VERSION "HINBNNNYYNNNYYNNNNNNNNNNNNYNNNYYYNNYNNNNNN/4//%%/4/'%**4NNN///"

NS_ :

BS_:

BU_: VirtualNMTMaster I_O_Device_2 Master I_O_Device_1

BO_ 1803 HBGuard_011: 1 I_O_Device_2
 SG_ Toggle : 7|1@1+ (1,0) [0|0] "" Vector__XXX
 SG_ State : 0|7@1+ (1,0) [0|0] "" Vector__XXX

BO_ 1419 SSDO_011: 8 I_O_Device_2
 SG_ Write_Output_32_Bit16_6320_10 m16 : 32|32@1+ (1,0) [0|4294967295] "" Vector__XXX
 SG_ Write_Output_32_Bit15_6320_0F m15 : 32|32@1+ (1,0) [0|4294967295] "" Vector__XXX
 SG_ Write_Output_32_Bit14_6320_0E m14 : 32|32@1+ (1,0) [0|4294967295] "" Vector__XXX
 SG_ Write_Output_32_Bit13_6320_0D m13 : 32|32@1+ (1,0) [0|4294967295] "" Vector__XXX
 SG_ Write_Output_32_Bit12_6320_0C m12 : 32|32@1+ (1,0) [0|4294967295] "" Vector__XXX
 SG_ Write_Output_32_Bit11_6320_0B m11 : 32|32@1+ (1,0) [0|4294967295] "" Vector__XXX
 SG_ Write_Output_32_Bit10_6320_0A m10 : 32|32@1+ (1,0) [0|4294967295] "" Vector__XXX
 SG_ Write_Output_32_Bit9_6320_09 m9 : 32|32@1+ (1,0) [0|4294967295] "" Vector__XXX
 SG_ Write_Output_32_Bit8_6320_08 m8 : 32|32@1+ (1,0) [0|4294967295] "" Vector__XXX
 SG_ Write_Output_32_Bit7_6320_07 m7 : 32|32@1+ (1,0) [0|4294967295] "" Vector__XXX
 SG_ Write_Output_32_Bit6_6320_06 m6 : 32|32@1+ (1,0) [0|4294967295] "" Vector__XXX
 SG_ Write_Output_32_Bit5_6320_05 m5 : 32|32@1+ (1,0) [0|4294967295] "" Vector__XXX
 SG_ Write_Output_32_Bit4_6320_04 m4 : 32|32@1+ (1,0) [0|4294967295] "" Vector__XXX
 SG_ Write_Output_32_Bit3_6320_03 m3 : 32|32@1+ (1,0) [0|4294967295] "" Vector__XXX
 SG_ Write_Output_32_Bit2_6320_02 m2 : 32|32@1+ (1,0) [0|4294967295] "" Vector__XXX
 SG_ Write_Output_32_Bit1_6320_01 m1 : 32|32@1+ (1,0) [0|4294967295] "" Vector__XXX
 SG_ NrOfObjects_6320_00 m0 : 32|8@1+ (1,0) [0|255] "" Vector__XXX
 SG_ SubIndex_6320 m25376M : 24|8@1+ (1,0) [0|16] "" Vector__XXX
 SG_ Write_Output_16_Bit16_6300_10 m16 : 32|16@1+ (1,0) [0|65535] "" Vector__XXX
 SG_ Write_Output_16_Bit15_6300_0F m15 : 32|16@1+ (1,0) [0|65535] "" Vector__XXX
 SG_ Write_Output_16_Bit14_6300_0E m14 : 32|16@1+ (1,0) [0|65535] "" Vector__XXX
 SG_ Write_Output_16_Bit13_6300_0D m13 : 32|16@1+ (1,0) [0|65535] "" Vector__XXX
 SG_ Write_Output_16_Bit12_6300_0C m12 : 32|16@1+ (1,0) [0|65535] "" Vector__XXX
 SG_ Write_Output_16_Bit11_6300_0B m11 : 32|16@1+ (1,0) [0|65535] "" Vector__XXX
 SG_ Write_Output_16_Bit10_6300_0A m10 : 32|16@1+ (1,0) [0|65535] "" Vector__XXX
 SG_ Write_Output_16_Bit9_6300_09 m9 : 32|16@1+ (1,0) [0|65535] "" Vector__XXX
 SG_ Write_Output_16_Bit8_6300_08 m8 : 32|16@1+ (1,0) [0|65535] "" Vector__XXX
 SG_ Write_Output_16_Bit7_6300_07 m7 : 32|16@1+ (1,0) [0|65535] "" Vector__XXX
 SG_ Write_Output_16_Bit6_6300_06 m6 : 32|16@1+ (1,0) [0|65535] "" Vector__XXX
 SG_ Write_Output_16_Bit5_6300_05 m5 : 32|16@1+ (1,0) [0|65535] "" Vector__XXX
 SG_ Write_Output_16_Bit4_6300_04 m4 : 32|16@1+ (1,0) [0|65535] "" Vector__XXX
 SG_ Write_Output_16_Bit3_6300_03 m3 : 32|16@1+ (1,0) [0|65535] "" Vector__XXX
 SG_ Write_Output_16_Bit2_6300_02 m2 : 32|16@1+ (1,0) [0|65535] "" Vector__XXX
 SG_ Write_Output_16_Bit1_6300_01 m1 : 32|16@1+ (1,0) [0|65535] "" Vector__XXX
 SG_ NrOfObjects_6300_00 m0 : 32|8@1+ (1,0) [0|255] "" Vector__XXX
 SG_ SubIndex_6300 m25344M : 24|8@1+ (1,0) [0|16] "" Vector__XXX
 SG_ Write_Output_1_Bit64_6220_40 m64 : 32|1@1+ (1,0) [0|1] "" Vector__XXX
 SG_ Write_Output_1_Bit63_6220_3F m63 : 32|1@1+ (1,0) [0|1] "" Vector__XXX
 SG_ Write_Output_1_Bit62_6220_3E m62 : 32|1@1+ (1,0) [0|1] "" Vector__XXX
 SG_ Write_Output_1_Bit61_6220_3D m61 : 32|1@1+ (1,0) [0|1] "" Vector__XXX
 SG_ Write_Output_1_Bit60_6220_3C m60 : 32|1@1+ (1,0) [0|1] "" Vector__XXX
 SG_ Write_Output_1_Bit59_6220_3B m59 : 32|1@1+ (1,0) [0|1] "" Vector__XXX
 SG_ Write_Output_1_Bit58_6220_3A m58 : 32|1@1+ (1,0) [0|1] "" Vector__XXX
 SG_ Write_Output_1_Bit57_6220_39 m57 : 32|1@1+ (1,0) [0|1] "" Vector__XXX
 SG_ Write_Output_1_Bit56_6220_38 m56 : 32|1@1+ (1,0) [0|1] "" Vector__XXX
 SG_ Write_Output_1_Bit55_6220_37 m55 : 32|1@1+ (1,0) [0|1] "" Vector__XXX
 SG_ Write_Output_1_Bit54_6220_36 m54 : 32|1@1+ (1,0) [0|1] "" Vector__XXX
 SG_ Write_Output_1_Bit53_6220_35 m53 : 32|1@1+ (1,0) [0|1] "" Vector__XXX
 SG_ Write_Output_1_Bit52_6220_34 m52 : 32|1@1+ (1,0) [0|1] "" Vector__XXX
 SG_ Write_Output_1_Bit51_6220_33 m51 : 32|1@1+ (1,0) [0|1] "" Vector__XXX
 SG_ Write_Output_1_Bit50_6220_32 m50 : 32|1@1+ (1,0) [0|1] "" Vector__XXX
 SG_ Write_Output_1_Bit49_6220_31 m49 : 32|1@1+ (1,0) [0|1] "" Vector__XXX
 SG_ Write_Output_1_Bit48_6220_30 m48 : 32|1@1+ (1,0) [0|1] "" Vector__XXX
 SG_ Write_Output_1_Bit47_6220_2F m47 : 32|1@1+ (1,0) [0|1] "" Vector__XXX
 SG_ Write_Output_1_Bit46_6220_2E m46 : 32|1@1+ (1,0) [0|1] "" Vector__XXX
 SG_ Write_Output_1_Bit45_6220_2D m45 : 32|1@1+ (1,0) [0|1] "" Vector__XXX
 SG_ Write_Output_1_Bit44_6220_2C m44 : 32|1@1+ (1,0) [0|1] "" Vector__XXX
 SG_ Write_Output_1_Bit43_6220_2B m43 : 32|1@1+ (1,0) [0|1] "" Vector__XXX
 SG_ Write_Output_1_Bit42_6220_2A m42 : 32|1@1+ (1,0) [0|1] "" Vector__XXX
 SG_ Write_Output_1_Bit41_6220_29 m41 : 32|1@1+ (1,0) [0|1] "" Vector__XXX
 SG_ Write_Output_1_Bit40_6220_28 m40 : 32|1@1+ (1,0) [0|1] "" Vector__XXX
 SG_ Write_Output_1_Bit39_6220_27 m39 : 32|1@1+ (1,0) [0|1] "" Vector__XXX
 SG_ Write_Output_1_Bit38_6220_26 m38 : 32|1@1+ (1,0) [0|1] "" Vector__XXX
 SG_ Write_Output_1_Bit37_6220_25 m37 : 32|1@1+ (1,0) [0|1] "" Vector__XXX
 SG_ Write_Output_1_Bit36_6220_24 m36 : 32|1@1+ (1,0) [0|1] "" Vector__XXX
 SG_ Write_Output_1_Bit35_6220_23 m35 : 32|1@1+ (1,0) [0|1] "" Vector__XXX
 SG_ Write_Output_1_Bit34_6220_22 m34 : 32|1@1+ (1,0) [0|1] "" Vector__XXX
 SG_ Write_Output_1_Bit33_6220_21 m33 : 32|1@1+ (1,0) [0|1] "" Vector__XXX
 SG_ Write_Output_1_Bit32_6220_20 m32 : 32|1@1+ (1,0) [0|1] "" Vector__XXX
 SG_ Write_Output_1_Bit31_6220_1F m31 : 32|1@1+ (1,0) [0|1] "" Vector__XXX
 SG_ Write_Output_1_Bit30_6220_1E m30 : 32|1@1+ (1,0) [0|1] "" Vector__XXX
 SG_ Write_Output_1_Bit29_6220_1D m29 : 32|1@1+ (1,0) [0|1] "" Vector__XXX
 SG_ Write_Output_1_Bit28_6220_1C m28 : 32|1@1+ (1,0) [0|1] "" Vector__XXX
 SG_ Write_Output_1_Bit27_6220_1B m27 : 32|1@1+ (1,0) [0|1] "" Vector__XXX
 SG_ Write_Output_1_Bit26_6220_1A m26 : 32|1@1+ (1,0) [0|1] "" Vector__XXX
 SG_ Write_Output_1_Bit25_6220_19 m25 : 32|1@1+ (1,0) [0|1] "" Vector__XXX
 SG_ Write_Output_1_Bit24_6220_18 m24 : 32|1@1+ (1,0) [0|1] "" Vector__XXX
 SG_ Write_Output_1_Bit23_6220_17 m23 : 32|1@1+ (1,0) [0|1] "" Vector__XXX
 SG_ Write_Output_1_Bit22_6220_16 m22 : 32|1@1+ (1,0) [0|1] "" Vector__XXX
 SG_ Write_Output_1_Bit21_6220_15 m21 : 32|1@1+ (1,0) [0|1] "" Vector__XXX
 SG_ Write_Output_1_Bit20_6220_14 m20 : 32|1@1+ (1,0) [0|1] "" Vector__XXX
 SG_ Write_Output_1_Bit19_6220_13 m19 : 32|1@1+ (1,0) [0|1] "" Vector__XXX
 SG_ Write_Output_1_Bit18_6220_12 m18 : 32|1@1+ (1,0) [0|1] "" Vector__XXX
 SG_ Write_Output_1_Bit17_6220_11 m17 : 32|1@1+ (1,0) [0|1] "" Vector__XXX
 SG_ Write_Output_1_Bit16_6220_10 m16 : 32|1@1+ (1,0) [0|1] "" Vector__XXX
 SG_ Write_Output_1_Bit15_6220_0F m15 : 32|1@1+ (1,0) [0|1] "" Vector__XXX
 SG_ Write_Output_1_Bit14_6220_0E m14 : 32|1@1+ (1,0) [0|1] "" Vector__XXX
 SG_ Write_Output_1_Bit13_6220_0D m13 : 32|1@1+ (1,0) [0|1] "" Vector__XXX
 SG_ Write_Output_1_Bit12_6220_0C m12 : 32|1@1+ (1,0) [0|1] "" Vector__XXX
 SG_ Write_Output_1_Bit11_6220_0B m11 : 32|1@1+ (1,0) [0|1] "" Vector__XXX
 SG_ Write_Output_1_Bit10_6220_0A m10 : 32|1@1+ (1,0) [0|1] "" Vector__XXX
 SG_ Write_Output_1_Bit9_6220_09 m9 : 32|1@1+ (1,0) [0|1] "" Vector__XXX
 SG_ Write_Output_1_Bit8_6220_08 m8 : 32|1@1+ (1,0) [0|1] "" Vector__XXX
 SG_ Write_Output_1_Bit7_6220_07 m7 : 32|1@1+ (1,0) [0|1] "" Vector__XXX
 SG_ Write_Output_1_Bit6_6220_06 m6 : 32|1@1+ (1,0) [0|1] "" Vector__XXX
 SG_ Write_Output_1_Bit5_6220_05 m5 : 32|1@1+ (1,0) [0|1] "" Vector__XXX
 SG_ Write_Output_1_Bit4_6220_04 m4 : 32|1@1+ (1,0) [0|1] "" Vector__XXX
 SG_ Write_Output_1_Bit3_6220_03 m3 : 32|1@1+ (1,0) [0|1] "" Vector__XXX
 SG_ Write_Output_1_Bit2_6220_02 m2 : 32|1@1+ (1,0) [0|1] "" Vector__XXX
 SG_ Write_Output_1_Bit1_6220_01 m1 : 32|1@1+ (1,0) [0|1] "" Vector__XXX
 SG_ NrOfObjects_6220_00 m0 : 32|8@1+ (1,0) [0|255] "" Vector__XXX
 SG_ SubIndex_6220 m25120M : 24|8@1+ (1,0) [0|64] "" Vector__XXX
 SG_ Write_Output_8_Bit16_6200_10 m16 : 32|8@1+ (1,0) [0|255] "" Vector__XXX
 SG_ Write_Output_8_Bit15_6200_0F m15 : 32|8@1+ (1,0) [0|255] "" Vector__XXX
 SG_ Write_Output_8_Bit14_6200_0E m14 : 32|8@1+ (1,0) [0|255] "" Vector__XXX
 SG_ Write_Output_8_Bit13_6200_0D m13 : 32|8@1+ (1,0) [0|255] "" Vector__XXX
 SG_ Write_Output_8_Bit12_6200_0C m12 : 32|8@1+ (1,0) [0|255] "" Vector__XXX
 SG_ Write_Output_8_Bit11_6200_0B m11 : 32|8@1+ (1,0) [0|255] "" Vector__XXX
 SG_ Write_Output_8_Bit10_6200_0A m10 : 32|8@1+ (1,0) [0|255] "" Vector__XXX
 SG_ Write_Output_8_Bit9_6200_09 m9 : 32|8@1+ (1,0) [0|255] "" Vector__XXX
 SG_ Write_Output_8_Bit8_6200_08 m8 : 32|8@1+ (1,0) [0|255] "" Vector__XXX
 SG_ Write_Output_8_Bit7_6200_07 m7 : 32|8@1+ (1,0) [0|255] "" Vector__XXX
 SG_ Write_Output_8_Bit6_6200_06 m6 : 32|8@1+ (1,0) [0|255] "" Vector__XXX
 SG_ Write_Output_8_Bit5_6200_05 m5 : 32|8@1+ (1,0) [0|255] "" Vector__XXX
 SG_ Write_Output_8_Bit4_6200_04 m4 : 32|8@1+ (1,0) [0|255] "" Vector__XXX
 SG_ Write_Output_8_Bit3_6200_03 m3 : 32|8@1+ (1,0) [0|255] "" Vector__XXX
 SG_ Write_Output_8_Bit2_6200_02 m2 : 32|8@1+ (1,0) [0|255] "" Vector__XXX
 SG_ Write_Output_8_Bit1_6200_01 m1 : 32|8@1+ (1,0) [0|255] "" Vector__XXX
 SG_ NrOfObjects_6200_00 m0 : 32|8@1+ (1,0) [0|255] "" Vector__XXX
 SG_ SubIndex_6200 m25088M : 24|8@1+ (1,0) [0|16] "" Vector__XXX
 SG_ Read_Input_32_Bit16_6120_10 m16 : 32|32@1+ (1,0) [0|4294967295] "" Vector__XXX
 SG_ Read_Input_32_Bit15_6120_0F m15 : 32|32@1+ (1,0) [0|4294967295] "" Vector__XXX
 SG_ Read_Input_32_Bit14_6120_0E m14 : 32|32@1+ (1,0) [0|4294967295] "" Vector__XXX
 SG_ Read_Input_32_Bit13_6120_0D m13 : 32|32@1+ (1,0) [0|4294967295] "" Vector__XXX
 SG_ Read_Input_32_Bit12_6120_0C m12 : 32|32@1+ (1,0) [0|4294967295] "" Vector__XXX
 SG_ Read_Input_32_Bit11_6120_0B m11 : 32|32@1+ (1,0) [0|4294967295] "" Vector__XXX
 SG_ Read_Input_32_Bit10_6120_0A m10 : 32|32@1+ (1,0) [0|4294967295] "" Vector__XXX
 SG_ Read_Input_32_Bit9_6120_09 m9 : 32|32@1+ (1,0) [0|4294967295] "" Vector__XXX
 SG_ Read_Input_32_Bit8_6120_08 m8 : 32|32@1+ (1,0) [0|4294967295] "" Vector__XXX
 SG_ Read_Input_32_Bit7_6120_07 m7 : 32|32@1+ (1,0) [0|4294967295] "" Vector__XXX
 SG_ Read_Input_32_Bit6_6120_06 m6 : 32|32@1+ (1,0) [0|4294967295] "" Vector__XXX
 SG_ Read_Input_32_Bit5_6120_05 m5 : 32|32@1+ (1,0) [0|4294967295] "" Vector__XXX
 SG_ Read_Input_32_Bit4_6120_04 m4 : 32|32@1+ (1,0) [0|4294967295] "" Vector__XXX
 SG_ Read_Input_32_Bit3_6120_03 m3 : 32|32@1+ (1,0) [0|4294967295] "" Vector__XXX
 SG_ Read_Input_32_Bit2_6120_02 m2 : 32|32@1+ (1,0) [0|4294967295] "" Vector__XXX
 SG_ Read_Input_32_Bit1_6120_01 m1 : 32|32@1+ (1,0) [0|4294967295] "" Vector__XXX
 SG_ NrOfObjects_6120_00 m0 : 32|8@1+ (1,0) [0|255] "" Vector__XXX
 SG_ SubIndex_6120 m24864M : 24|8@1+ (1,0) [0|16] "" Vector__XXX
 SG_ Read_Input_16_Bit16_6100_10 m16 : 32|16@1+ (1,0) [0|65535] "" Vector__XXX
 SG_ Read_Input_16_Bit15_6100_0F m15 : 32|16@1+ (1,0) [0|65535] "" Vector__XXX
 SG_ Read_Input_16_Bit14_6100_0E m14 : 32|16@1+ (1,0) [0|65535] "" Vector__XXX
 SG_ Read_Input_16_Bit13_6100_0D m13 : 32|16@1+ (1,0) [0|65535] "" Vector__XXX
 SG_ Read_Input_16_Bit12_6100_0C m12 : 32|16@1+ (1,0) [0|65535] "" Vector__XXX
 SG_ Read_Input_16_Bit11_6100_0B m11 : 32|16@1+ (1,0) [0|65535] "" Vector__XXX
 SG_ Read_Input_16_Bit10_6100_0A m10 : 32|16@1+ (1,0) [0|65535] "" Vector__XXX
 SG_ Read_Input_16_Bit9_6100_09 m9 : 32|16@1+ (1,0) [0|65535] "" Vector__XXX
 SG_ Read_Input_16_Bit8_6100_08 m8 : 32|16@1+ (1,0) [0|65535] "" Vector__XXX
 SG_ Read_Input_16_Bit7_6100_07 m7 : 32|16@1+ (1,0) [0|65535] "" Vector__XXX
 SG_ Read_Input_16_Bit6_6100_06 m6 : 32|16@1+ (1,0) [0|65535] "" Vector__XXX
 SG_ Read_Input_16_Bit5_6100_05 m5 : 32|16@1+ (1,0) [0|65535] "" Vector__XXX
 SG_ Read_Input_16_Bit4_6100_04 m4 : 32|16@1+ (1,0) [0|65535] "" Vector__XXX
 SG_ Read_Input_16_Bit3_6100_03 m3 : 32|16@1+ (1,0) [0|65535] "" Vector__XXX
 SG_ Read_Input_16_Bit2_6100_02 m2 : 32|16@1+ (1,0) [0|65535] "" Vector__XXX
 SG_ Read_Input_16_Bit1_6100_01 m1 : 32|16@1+ (1,0) [0|65535] "" Vector__XXX
 SG_ NrOfObjects_6100_00 m0 : 32|8@1+ (1,0) [0|255] "" Vector__XXX
 SG_ SubIndex_6100 m24832M : 24|8@1+ (1,0) [0|16] "" Vector__XXX
 SG_ Read_Input_1_Bit64_6020_40 m64 : 32|1@1+ (1,0) [0|1] "" Vector__XXX
 SG_ Read_Input_1_Bit63_6020_3F m63 : 32|1@1+ (1,0) [0|1] "" Vector__XXX
 SG_ Read_Input_1_Bit62_6020_3E m62 : 32|1@1+ (1,0) [0|1] "" Vector__XXX
 SG_ Read_Input_1_Bit61_6020_3D m61 : 32|1@1+ (1,0) [0|1] "" Vector__XXX
 SG_ Read_Input_1_Bit60_6020_3C m60 : 32|1@1+ (1,0) [0|1] "" Vector__XXX
 SG_ Read_Input_1_Bit59_6020_3B m59 : 32|1@1+ (1,0) [0|1] "" Vector__XXX
 SG_ Read_Input_1_Bit58_6020_3A m58 : 32|1@1+ (1,0) [0|1] "" Vector__XXX
 SG_ Read_Input_1_Bit57_6020_39 m57 : 32|1@1+ (1,0) [0|1] "" Vector__XXX
 SG_ Read_Input_1_Bit56_6020_38 m56 : 32|1@1+ (1,0) [0|1] "" Vector__XXX
 SG_ Read_Input_1_Bit55_6020_37 m55 : 32|1@1+ (1,0) [0|1] "" Vector__XXX
 SG_ Read_Input_1_Bit54_6020_36 m54 : 32|1@1+ (1,0) [0|1] "" Vector__XXX
 SG_ Read_Input_1_Bit53_6020_35 m53 : 32|1@1+ (1,0) [0|1] "" Vector__XXX
 SG_ Read_Input_1_Bit52_6020_34 m52 : 32|1@1+ (1,0) [0|1] "" Vector__XXX
 SG_ Read_Input_1_Bit51_6020_33 m51 : 32|1@1+ (1,0) [0|1] "" Vector__XXX
 SG_ Read_Input_1_Bit50_6020_32 m50 : 32|1@1+ (1,0) [0|1] "" Vector__XXX
 SG_ Read_Input_1_Bit49_6020_31 m49 : 32|1@1+ (1,0) [0|1] "" Vector__XXX
 SG_ Read_Input_1_Bit48_6020_30 m48 : 32|1@1+ (1,0) [0|1] "" Vector__XXX
 SG_ Read_Input_1_Bit47_6020_2F m47 : 32|1@1+ (1,0) [0|1] "" Vector__XXX
 SG_ Read_Input_1_Bit46_6020_2E m46 : 32|1@1+ (1,0) [0|1] "" Vector__XXX
 SG_ Read_Input_1_Bit45_6020_2D m45 : 32|1@1+ (1,0) [0|1] "" Vector__XXX
 SG_ Read_Input_1_Bit44_6020_2C m44 : 32|1@1+ (1,0) [0|1] "" Vector__XXX
 SG_ Read_Input_1_Bit43_6020_2B m43 : 32|1@1+ (1,0) [0|1] "" Vector__XXX
 SG_ Read_Input_1_Bit42_6020_2A m42 : 32|1@1+ (1,0) [0|1] "" Vector__XXX
 SG_ Read_Input_1_Bit41_6020_29 m41 : 32|1@1+ (1,0) [0|1] "" Vector__XXX
 SG_ Read_Input_1_Bit40_6020_28 m40 : 32|1@1+ (1,0) [0|1] "" Vector__XXX
 SG_ Read_Input_1_Bit39_6020_27 m39 : 32|1@1+ (1,0) [0|1] "" Vector__XXX
 SG_ Read_Input_1_Bit38_6020_26 m38 : 32|1@1+ (1,0) [0|1] "" Vector__XXX
 SG_ Read_Input_1_Bit37_6020_25 m37 : 32|1@1+ (1,0) [0|1] "" Vector__XXX
 SG_ Read_Input_1_Bit36_6020_24 m36 : 32|1@1+ (1,0) [0|1] "" Vector__XXX
 SG_ Read_Input_1_Bit35_6020_23 m35 : 32|1@1+ (1,0) [0|1] "" Vector__XXX
 SG_ Read_Input_1_Bit34_6020_22 m34 : 32|1@1+ (1,0) [0|1] "" Vector__XXX
 SG_ Read_Input_1_Bit33_6020_21 m33 : 32|1@1+ (1,0) [0|1] "" Vector__XXX
 SG_ Read_Input_1_Bit32_6020_20 m32 : 32|1@1+ (1,0) [0|1] "" Vector__XXX
 SG_ Read_Input_1_Bit31_6020_1F m31 : 32|1@1+ (1,0) [0|1] "" Vector__XXX
 SG_ Read_Input_1_Bit30_6020_1E m30 : 32|1@1+ (1,0) [0|1] "" Vector__XXX
 SG_ Read_Input_1_Bit29_6020_1D m29 : 32|1@1+ (1,0) [0|1] "" Vector__XXX
 SG_ Read_Input_1_Bit28_6020_1C m28 : 32|1@1+ (1,0) [0|1] "" Vector__XXX
 SG_ Read_Input_1_Bit27_6020_1B m27 : 32|1@1+ (1,0) [0|1] "" Vector__XXX
 SG_ Read_Input_1_Bit26_6020_1A m26 : 32|1@1+ (1,0) [0|1] "" Vector__XXX
 SG_ Read_Input_1_Bit25_6020_19 m25 : 32|1@1+ (1,0) [0|1] "" Vector__XXX
 SG_ Read_Input_1_Bit24_6020_18 m24 : 32|1@1+ (1,0) [0|1] "" Vector__XXX
 SG_ Read_Input_1_Bit23_6020_17 m23 : 32|1@1+ (1,0) [0|1] "" Vector__XXX
 SG_ Read_Input_1_Bit22_6020_16 m22 : 32|1@1+ (1,0) [0|1] "" Vector__XXX
 SG_ Read_Input_1_Bit21_6020_15 m21 : 32|1@1+ (1,0) [0|1] "" Vector__XXX
 SG_ Read_Input_1_Bit20_6020_14 m20 : 32|1@1+ (1,0) [0|1] "" Vector__XXX
 SG_ Read_Input_1_Bit19_6020_13 m19 : 32|1@1+ (1,0) [0|1] "" Vector__XXX
 SG_ Read_Input_1_Bit18_6020_12 m18 : 32|1@1+ (1,0) [0|1] "" Vector__XXX
 SG_ Read_Input_1_Bit17_6020_11 m17 : 32|1@1+ (1,0) [0|1] "" Vector__XXX
 SG_ Read_Input_1_Bit16_6020_10 m16 : 32|1@1+ (1,0) [0|1] "" Vector__XXX
 SG_ Read_Input_1_Bit15_6020_0F m15 : 32|1@1+ (1,0) [0|1] "" Vector__XXX
 SG_ Read_Input_1_Bit14_6020_0E m14 : 32|1@1+ (1,0) [0|1] "" Vector__XXX
 SG_ Read_Input_1_Bit13_6020_0D m13 : 32|1@1+ (1,0) [0|1] "" Vector__XXX
 SG_ Read_Input_1_Bit12_6020_0C m12 : 32|1@1+ (1,0) [0|1] "" Vector__XXX
 SG_ Read_Input_1_Bit11_6020_0B m11 : 32|1@1+ (1,0) [0|1] "" Vector__XXX
 SG_ Read_Input_1_Bit10_6020_0A m10 : 32|1@1+ (1,0) [0|1] "" Vector__XXX
 SG_ Read_Input_1_Bit9_6020_09 m9 : 32|1@1+ (1,0) [0|1] "" Vector__XXX
 SG_ Read_Input_1_Bit8_6020_08 m8 : 32|1@1+ (1,0) [0|1] "" Vector__XXX
 SG_ Read_Input_1_Bit7_6020_07 m7 : 32|1@1+ (1,0) [0|1] "" Vector__XXX
 SG_ Read_Input_1_Bit6_6020_06 m6 : 32|1@1+ (1,0) [0|1] "" Vector__XXX
 SG_ Read_Input_1_Bit5_6020_05 m5 : 32|1@1+ (1,0) [0|1] "" Vector__XXX
 SG_ Read_Input_1_Bit4_6020_04 m4 : 32|1@1+ (1,0) [0|1] "" Vector__XXX
 SG_ Read_Input_1_Bit3_6020_03 m3 : 32|1@1+ (1,0) [0|1] "" Vector__XXX
 SG_ Read_Input_1_Bit2_6020_02 m2 : 32|1@1+ (1,0) [0|1] "" Vector__XXX
 SG_ Read_Input_1_Bit1_6020_01 m1 : 32|1@1+ (1,0) [0|1] "" Vector__XXX
 SG_ NrOfObjects_6020_00 m0 : 32|8@1+ (1,0) [0|255] "" Vector__XXX
 SG_ SubIndex_6020 m24608M : 24|8@1+ (1,0) [0|64] "" Vector__XXX
 SG_ Read_Input_8_Bit16_6000_10 m16 : 32|8@1+ (1,0) [0|255] "" Vector__XXX
 SG_ Read_Input_8_Bit15_6000_0F m15 : 32|8@1+ (1,0) [0|255] "" Vector__XXX
 SG_ Read_Input_8_Bit14_6000_0E m14 : 32|8@1+ (1,0) [0|255] "" Vector__XXX
 SG_ Read_Input_8_Bit13_6000_0D m13 : 32|8@1+ (1,0) [0|255] "" Vector__XXX
 SG_ Read_Input_8_Bit12_6000_0C m12 : 32|8@1+ (1,0) [0|255] "" Vector__XXX
 SG_ Read_Input_8_Bit11_6000_0B m11 : 32|8@1+ (1,0) [0|255] "" Vector__XXX
 SG_ Read_Input_8_Bit10_6000_0A m10 : 32|8@1+ (1,0) [0|255] "" Vector__XXX
 SG_ Read_Input_8_Bit9_6000_09 m9 : 32|8@1+ (1,0) [0|255] "" Vector__XXX
 SG_ Read_Input_8_Bit8_6000_08 m8 : 32|8@1+ (1,0) [0|255] "" Vector__XXX
 SG_ Read_Input_8_Bit7_6000_07 m7 : 32|8@1+ (1,0) [0|255] "" Vector__XXX
 SG_ Read_Input_8_Bit6_6000_06 m6 : 32|8@1+ (1,0) [0|255] "" Vector__XXX
 SG_ Read_Input_8_Bit5_6000_05 m5 : 32|8@1+ (1,0) [0|255] "" Vector__XXX
 SG_ Read_Input_8_Bit4_6000_04 m4 : 32|8@1+ (1,0) [0|255] "" Vector__XXX
 SG_ Read_Input_8_Bit3_6000_03 m3 : 32|8@1+ (1,0) [0|255] "" Vector__XXX
 SG_ Read_Input_8_Bit2_6000_02 m2 : 32|8@1+ (1,0) [0|255] "" Vector__XXX
 SG_ Read_Input_8_Bit1_6000_01 m1 : 32|8@1+ (1,0) [0|255] "" Vector__XXX
 SG_ NrOfObjects_6000_00 m0 : 32|8@1+ (1,0) [0|255] "" Vector__XXX
 SG_ SubIndex_6000 m24576M : 24|8@1+ (1,0) [0|16] "" Vector__XXX
 SG_ NrOfObjects_2300_00 m0 : 32|8@1+ (1,0) [0|255] "" Vector__XXX
 SG_ SubIndex_2300 m8960M : 24|8@1+ (1,0) [0|4] "" Vector__XXX
 SG_ NrOfObjects_2200_00 m0 : 32|8@1+ (1,0) [0|255] "" Vector__XXX
 SG_ SubIndex_2200 m8704M : 24|8@1+ (1,0) [0|4] "" Vector__XXX
 SG_ NrOfMappedObjects_1A03_00 m0 : 32|8@1+ (1,0) [0|64] "" Vector__XXX
 SG_ SubIndex_1A03 m6659M : 24|8@1+ (1,0) [0|0] "" Vector__XXX
 SG_ NrOfMappedObjects_1A02_00 m0 : 32|8@1+ (1,0) [0|64] "" Vector__XXX
 SG_ SubIndex_1A02 m6658M : 24|8@1+ (1,0) [0|0] "" Vector__XXX
 SG_ NrOfMappedObjects_1A01_00 m0 : 32|8@1+ (1,0) [0|64] "" Vector__XXX
 SG_ SubIndex_1A01 m6657M : 24|8@1+ (1,0) [0|0] "" Vector__XXX
 SG_ NrOfMappedObjects_1A00_00 m0 : 32|8@1+ (1,0) [0|64] "" Vector__XXX
 SG_ SubIndex_1A00 m6656M : 24|8@1+ (1,0) [0|0] "" Vector__XXX
 SG_ EventTimer_1803_05 m5 : 32|16@1+ (1,0) [0|65535] "" Vector__XXX
 SG_ TransmissionType_1803_02 m2 : 32|8@1+ (1,0) [0|255] "" Vector__XXX
 SG_ COB_ID_1803_01 m1 : 32|32@1+ (1,0) [128|4294967295] "" Vector__XXX
 SG_ NrOfEntries_1803_00 m0 : 32|8@1+ (1,0) [2|5] "" Vector__XXX
 SG_ SubIndex_1803 m6147M : 24|8@1+ (1,0) [0|5] "" Vector__XXX
 SG_ EventTimer_1802_05 m5 : 32|16@1+ (1,0) [0|65535] "" Vector__XXX
 SG_ TransmissionType_1802_02 m2 : 32|8@1+ (1,0) [0|255] "" Vector__XXX
 SG_ COB_ID_1802_01 m1 : 32|32@1+ (1,0) [128|4294967295] "" Vector__XXX
 SG_ NrOfEntries_1802_00 m0 : 32|8@1+ (1,0) [2|5] "" Vector__XXX
 SG_ SubIndex_1802 m6146M : 24|8@1+ (1,0) [0|5] "" Vector__XXX
 SG_ EventTimer_1801_05 m5 : 32|16@1+ (1,0) [0|65535] "" Vector__XXX
 SG_ TransmissionType_1801_02 m2 : 32|8@1+ (1,0) [0|255] "" Vector__XXX
 SG_ COB_ID_1801_01 m1 : 32|32@1+ (1,0) [128|4294967295] "" Vector__XXX
 SG_ NrOfEntries_1801_00 m0 : 32|8@1+ (1,0) [2|5] "" Vector__XXX
 SG_ SubIndex_1801 m6145M : 24|8@1+ (1,0) [0|5] "" Vector__XXX
 SG_ EventTimer_1800_05 m5 : 32|16@1+ (1,0) [0|65535] "" Vector__XXX
 SG_ TransmissionType_1800_02 m2 : 32|8@1+ (1,0) [0|255] "" Vector__XXX
 SG_ COB_ID_1800_01 m1 : 32|32@1+ (1,0) [128|4294967295] "" Vector__XXX
 SG_ NrOfEntries_1800_00 m0 : 32|8@1+ (1,0) [2|5] "" Vector__XXX
 SG_ SubIndex_1800 m6144M : 24|8@1+ (1,0) [0|5] "" Vector__XXX
 SG_ NrOfMappedObjects_1603_00 m0 : 32|8@1+ (1,0) [0|64] "" Vector__XXX
 SG_ SubIndex_1603 m5635M : 24|8@1+ (1,0) [0|0] "" Vector__XXX
 SG_ NrOfMappedObjects_1602_00 m0 : 32|8@1+ (1,0) [0|64] "" Vector__XXX
 SG_ SubIndex_1602 m5634M : 24|8@1+ (1,0) [0|0] "" Vector__XXX
 SG_ NrOfMappedObjects_1601_00 m0 : 32|8@1+ (1,0) [0|64] "" Vector__XXX
 SG_ SubIndex_1601 m5633M : 24|8@1+ (1,0) [0|0] "" Vector__XXX
 SG_ mappedObj2_1600_02 m2 : 32|32@1+ (1,0) [0|4294967295] "" Vector__XXX
 SG_ mappedObj1_1600_01 m1 : 32|32@1+ (1,0) [0|4294967295] "" Vector__XXX
 SG_ NrOfMappedObjects_1600_00 m0 : 32|8@1+ (1,0) [0|64] "" Vector__XXX
 SG_ SubIndex_1600 m5632M : 24|8@1+ (1,0) [0|2] "" Vector__XXX
 SG_ TransmissionType_1403_02 m2 : 32|8@1+ (1,0) [0|255] "" Vector__XXX
 SG_ COB_ID_1403_01 m1 : 32|32@1+ (1,0) [128|4294967295] "" Vector__XXX
 SG_ NrOfEntries_1403_00 m0 : 32|8@1+ (1,0) [2|5] "" Vector__XXX
 SG_ SubIndex_1403 m5123M : 24|8@1+ (1,0) [0|2] "" Vector__XXX
 SG_ TransmissionType_1402_02 m2 : 32|8@1+ (1,0) [0|255] "" Vector__XXX
 SG_ COB_ID_1402_01 m1 : 32|32@1+ (1,0) [128|4294967295] "" Vector__XXX
 SG_ NrOfEntries_1402_00 m0 : 32|8@1+ (1,0) [2|5] "" Vector__XXX
 SG_ SubIndex_1402 m5122M : 24|8@1+ (1,0) [0|2] "" Vector__XXX
 SG_ TransmissionType_1401_02 m2 : 32|8@1+ (1,0) [0|255] "" Vector__XXX
 SG_ COB_ID_1401_01 m1 : 32|32@1+ (1,0) [128|4294967295] "" Vector__XXX
 SG_ NrOfEntries_1401_00 m0 : 32|8@1+ (1,0) [2|5] "" Vector__XXX
 SG_ SubIndex_1401 m5121M : 24|8@1+ (1,0) [0|2] "" Vector__XXX
 SG_ TransmissionType_1400_02 m2 : 32|8@1+ (1,0) [0|255] "" Vector__XXX
 SG_ COB_ID_1400_01 m1 : 32|32@1+ (1,0) [128|4294967295] "" Vector__XXX
 SG_ NrOfEntries_1400_00 m0 : 32|8@1+ (1,0) [2|5] "" Vector__XXX
 SG_ SubIndex_1400 m5120M : 24|8@1+ (1,0) [0|2] "" Vector__XXX
 SG_ Serial_number_1018_04 m4 : 32|32@1+ (1,0) [0|4294967295] "" Vector__XXX
 SG_ Revision_number_1018_03 m3 : 32|32@1+ (1,0) [0|4294967295] "" Vector__XXX
 SG_ Product_Code_1018_02 m2 : 32|32@1+ (1,0) [0|4294967295] "" Vector__XXX
 SG_ Vendor_Id_1018_01 m1 : 32|32@1+ (1,0) [0|4294967295] "" Vector__XXX
 SG_ number_of_entries_1018_00 m0 : 32|8@1+ (1,0) [1|4] "" Vector__XXX
 SG_ SubIndex_1018 m4120M : 24|8@1+ (1,0) [0|4] "" Vector__XXX
 SG_ Producer_Heartbeat_Time_1017 m0 : 32|16@1+ (1,0) [0|65535] "" Vector__XXX
 SG_ SubIndex_1017 m4119M : 24|8@1+ (1,0) [0|0] "" Vector__XXX
 SG_ Consumer_Heartbeat_Time16_1016_1 m16 : 32|32@1+ (1,0) [0|4294967295] "" Vector__XXX
 SG_ Consumer_Heartbeat_Time15_1016_0 m15 : 32|32@1+ (1,0) [0|4294967295] "" Vector__XXX
 SG_ Consumer_Heartbeat_Time14_1016_0 m14 : 32|32@1+ (1,0) [0|4294967295] "" Vector__XXX
 SG_ Consumer_Heartbeat_Time13_1016_0 m13 : 32|32@1+ (1,0) [0|4294967295] "" Vector__XXX
 SG_ Consumer_Heartbeat_Time12_1016_0 m12 : 32|32@1+ (1,0) [0|4294967295] "" Vector__XXX
 SG_ Consumer_Heartbeat_Time11_1016_0 m11 : 32|32@1+ (1,0) [0|4294967295] "" Vector__XXX
 SG_ Consumer_Heartbeat_Time10_1016_0 m10 : 32|32@1+ (1,0) [0|4294967295] "" Vector__XXX
 SG_ Consumer_Heartbeat_Time9_1016_09 m9 : 32|32@1+ (1,0) [0|4294967295] "" Vector__XXX
 SG_ Consumer_Heartbeat_Time8_1016_08 m8 : 32|32@1+ (1,0) [0|4294967295] "" Vector__XXX
 SG_ Consumer_Heartbeat_Time7_1016_07 m7 : 32|32@1+ (1,0) [0|4294967295] "" Vector__XXX
 SG_ Consumer_Heartbeat_Time6_1016_06 m6 : 32|32@1+ (1,0) [0|4294967295] "" Vector__XXX
 SG_ Consumer_Heartbeat_Time5_1016_05 m5 : 32|32@1+ (1,0) [0|4294967295] "" Vector__XXX
 SG_ Consumer_Heartbeat_Time4_1016_04 m4 : 32|32@1+ (1,0) [0|4294967295] "" Vector__XXX
 SG_ Consumer_Heartbeat_Time3_1016_03 m3 : 32|32@1+ (1,0) [0|4294967295] "" Vector__XXX
 SG_ Consumer_Heartbeat_Time2_1016_02 m2 : 32|32@1+ (1,0) [0|4294967295] "" Vector__XXX
 SG_ Consumer_Heartbeat_Time1_1016_01 m1 : 32|32@1+ (1,0) [0|4294967295] "" Vector__XXX
 SG_ NrOfObjects_1016_00 m0 : 32|8@1+ (1,0) [0|255] "" Vector__XXX
 SG_ SubIndex_1016 m4118M : 24|8@1+ (1,0) [0|16] "" Vector__XXX
 SG_ COB_ID_EMCY_1014 m0 : 32|32@1+ (1,0) [128|3221225471] "" Vector__XXX
 SG_ SubIndex_1014 m4116M : 24|8@1+ (1,0) [0|0] "" Vector__XXX
 SG_ Restore_all_Default_Parameters_1 m1 : 32|32@1+ (1,0) [0|4294967295] "" Vector__XXX
 SG_ Number_of_Entries_1011_00 m0 : 32|8@1+ (1,0) [0|255] "" Vector__XXX
 SG_ SubIndex_1011 m4113M : 24|8@1+ (1,0) [0|1] "" Vector__XXX
 SG_ Save_all_Parameters_1010_01 m1 : 32|32@1+ (1,0) [0|4294967295] "" Vector__XXX
 SG_ Number_of_Entries_1010_00 m0 : 32|8@1+ (1,0) [0|255] "" Vector__XXX
 SG_ SubIndex_1010 m4112M : 24|8@1+ (1,0) [0|1] "" Vector__XXX
 SG_ Life_Time_Factor_100D m0 : 32|8@1+ (1,0) [0|255] "" Vector__XXX
 SG_ SubIndex_100D m4109M : 24|8@1+ (1,0) [0|0] "" Vector__XXX
 SG_ Guard_Time_100C m0 : 32|16@1+ (1,0) [0|65535] "" Vector__XXX
 SG_ SubIndex_100C m4108M : 24|8@1+ (1,0) [0|0] "" Vector__XXX
 SG_ Synchronous_Window_Length_1007 m0 : 32|32@1+ (1,0) [0|4294967295] "" Vector__XXX
 SG_ SubIndex_1007 m4103M : 24|8@1+ (1,0) [0|0] "" Vector__XXX
 SG_ Communication_Cycle_Period_1006 m0 : 32|32@1+ (1,0) [0|4294967295] "" Vector__XXX
 SG_ SubIndex_1006 m4102M : 24|8@1+ (1,0) [0|0] "" Vector__XXX
 SG_ COB_ID_SYNC_1005 m0 : 32|32@1+ (1,0) [128|4294967295] "" Vector__XXX
 SG_ SubIndex_1005 m4101M : 24|8@1+ (1,0) [0|0] "" Vector__XXX
 SG_ Standard_error_field_1003_09 m9 : 32|32@1+ (1,0) [0|4294967295] "" Vector__XXX
 SG_ Standard_error_field_1003_08 m8 : 32|32@1+ (1,0) [0|4294967295] "" Vector__XXX
 SG_ Standard_error_field_1003_07 m7 : 32|32@1+ (1,0) [0|4294967295] "" Vector__XXX
 SG_ Standard_error_field_1003_06 m6 : 32|32@1+ (1,0) [0|4294967295] "" Vector__XXX
 SG_ Standard_error_field_1003_05 m5 : 32|32@1+ (1,0) [0|4294967295] "" Vector__XXX
 SG_ Standard_error_field_1003_04 m4 : 32|32@1+ (1,0) [0|4294967295] "" Vector__XXX
 SG_ Standard_error_field_1003_03 m3 : 32|32@1+ (1,0) [0|4294967295] "" Vector__XXX
 SG_ Standard_error_field_1003_02 m2 : 32|32@1+ (1,0) [0|4294967295] "" Vector__XXX
 SG_ Standard_error_field_1003_01 m1 : 32|32@1+ (1,0) [0|4294967295] "" Vector__XXX
 SG_ Number_of_Errors_1003_00 m0 : 32|8@1+ (1,0) [0|255] "" Vector__XXX
 SG_ SubIndex_1003 m4099M : 24|8@1+ (1,0) [0|9] "" Vector__XXX
 SG_ Error_Register_1001 m0 : 32|8@1+ (1,0) [0|255] "" Vector__XXX
 SG_ SubIndex_1001 m4097M : 24|8@1+ (1,0) [0|0] "" Vector__XXX
 SG_ Device_Type_1000 m0 : 32|32@1+ (1,0) [0|4294967295] "" Vector__XXX
 SG_ SubIndex_1000 m4096M : 24|8@1+ (1,0) [0|0] "" Vector__XXX
 SG_ Index m1M : 8|16@1+ (1,0) [4096|25376] "" Vector__XXX
 SG_ TransferType m1M : 1|1@1+ (1,0) [0|1] "" Vector__XXX
 SG_ NotUsedBytes m1 : 2|2@1+ (1,0) [0|3] "" Vector__XXX
 SG_ SizeIndicator m1 : 0|1@1+ (1,0) [0|1] "" Vector__XXX
 SG_ SCS M : 5|3@1+ (1,0) [0|6] "" Vector__XXX

BO_ 1547 CSDO_011: 8 Vector__XXX
 SG_ Write_Output_32_Bit16_6320_10 m16 : 32|32@1+ (1,0) [0|4294967295] ""  I_O_Device_2
 SG_ Write_Output_32_Bit15_6320_0F m15 : 32|32@1+ (1,0) [0|4294967295] ""  I_O_Device_2
 SG_ Write_Output_32_Bit14_6320_0E m14 : 32|32@1+ (1,0) [0|4294967295] ""  I_O_Device_2
 SG_ Write_Output_32_Bit13_6320_0D m13 : 32|32@1+ (1,0) [0|4294967295] ""  I_O_Device_2
 SG_ Write_Output_32_Bit12_6320_0C m12 : 32|32@1+ (1,0) [0|4294967295] ""  I_O_Device_2
 SG_ Write_Output_32_Bit11_6320_0B m11 : 32|32@1+ (1,0) [0|4294967295] ""  I_O_Device_2
 SG_ Write_Output_32_Bit10_6320_0A m10 : 32|32@1+ (1,0) [0|4294967295] ""  I_O_Device_2
 SG_ Write_Output_32_Bit9_6320_09 m9 : 32|32@1+ (1,0) [0|4294967295] ""  I_O_Device_2
 SG_ Write_Output_32_Bit8_6320_08 m8 : 32|32@1+ (1,0) [0|4294967295] ""  I_O_Device_2
 SG_ Write_Output_32_Bit7_6320_07 m7 : 32|32@1+ (1,0) [0|4294967295] ""  I_O_Device_2
 SG_ Write_Output_32_Bit6_6320_06 m6 : 32|32@1+ (1,0) [0|4294967295] ""  I_O_Device_2
 SG_ Write_Output_32_Bit5_6320_05 m5 : 32|32@1+ (1,0) [0|4294967295] ""  I_O_Device_2
 SG_ Write_Output_32_Bit4_6320_04 m4 : 32|32@1+ (1,0) [0|4294967295] ""  I_O_Device_2
 SG_ Write_Output_32_Bit3_6320_03 m3 : 32|32@1+ (1,0) [0|4294967295] ""  I_O_Device_2
 SG_ Write_Output_32_Bit2_6320_02 m2 : 32|32@1+ (1,0) [0|4294967295] ""  I_O_Device_2
 SG_ Write_Output_32_Bit1_6320_01 m1 : 32|32@1+ (1,0) [0|4294967295] ""  I_O_Device_2
 SG_ NrOfObjects_6320_00 m0 : 32|8@1+ (1,0) [0|255] ""  I_O_Device_2
 SG_ SubIndex_6320 m25376M : 24|8@1+ (1,0) [0|16] ""  I_O_Device_2
 SG_ Write_Output_16_Bit16_6300_10 m16 : 32|16@1+ (1,0) [0|65535] ""  I_O_Device_2
 SG_ Write_Output_16_Bit15_6300_0F m15 : 32|16@1+ (1,0) [0|65535] ""  I_O_Device_2
 SG_ Write_Output_16_Bit14_6300_0E m14 : 32|16@1+ (1,0) [0|65535] ""  I_O_Device_2
 SG_ Write_Output_16_Bit13_6300_0D m13 : 32|16@1+ (1,0) [0|65535] ""  I_O_Device_2
 SG_ Write_Output_16_Bit12_6300_0C m12 : 32|16@1+ (1,0) [0|65535] ""  I_O_Device_2
 SG_ Write_Output_16_Bit11_6300_0B m11 : 32|16@1+ (1,0) [0|65535] ""  I_O_Device_2
 SG_ Write_Output_16_Bit10_6300_0A m10 : 32|16@1+ (1,0) [0|65535] ""  I_O_Device_2
 SG_ Write_Output_16_Bit9_6300_09 m9 : 32|16@1+ (1,0) [0|65535] ""  I_O_Device_2
 SG_ Write_Output_16_Bit8_6300_08 m8 : 32|16@1+ (1,0) [0|65535] ""  I_O_Device_2
 SG_ Write_Output_16_Bit7_6300_07 m7 : 32|16@1+ (1,0) [0|65535] ""  I_O_Device_2
 SG_ Write_Output_16_Bit6_6300_06 m6 : 32|16@1+ (1,0) [0|65535] ""  I_O_Device_2
 SG_ Write_Output_16_Bit5_6300_05 m5 : 32|16@1+ (1,0) [0|65535] ""  I_O_Device_2
 SG_ Write_Output_16_Bit4_6300_04 m4 : 32|16@1+ (1,0) [0|65535] ""  I_O_Device_2
 SG_ Write_Output_16_Bit3_6300_03 m3 : 32|16@1+ (1,0) [0|65535] ""  I_O_Device_2
 SG_ Write_Output_16_Bit2_6300_02 m2 : 32|16@1+ (1,0) [0|65535] ""  I_O_Device_2
 SG_ Write_Output_16_Bit1_6300_01 m1 : 32|16@1+ (1,0) [0|65535] ""  I_O_Device_2
 SG_ NrOfObjects_6300_00 m0 : 32|8@1+ (1,0) [0|255] ""  I_O_Device_2
 SG_ SubIndex_6300 m25344M : 24|8@1+ (1,0) [0|16] ""  I_O_Device_2
 SG_ Write_Output_1_Bit64_6220_40 m64 : 32|1@1+ (1,0) [0|1] ""  I_O_Device_2
 SG_ Write_Output_1_Bit63_6220_3F m63 : 32|1@1+ (1,0) [0|1] ""  I_O_Device_2
 SG_ Write_Output_1_Bit62_6220_3E m62 : 32|1@1+ (1,0) [0|1] ""  I_O_Device_2
 SG_ Write_Output_1_Bit61_6220_3D m61 : 32|1@1+ (1,0) [0|1] ""  I_O_Device_2
 SG_ Write_Output_1_Bit60_6220_3C m60 : 32|1@1+ (1,0) [0|1] ""  I_O_Device_2
 SG_ Write_Output_1_Bit59_6220_3B m59 : 32|1@1+ (1,0) [0|1] ""  I_O_Device_2
 SG_ Write_Output_1_Bit58_6220_3A m58 : 32|1@1+ (1,0) [0|1] ""  I_O_Device_2
 SG_ Write_Output_1_Bit57_6220_39 m57 : 32|1@1+ (1,0) [0|1] ""  I_O_Device_2
 SG_ Write_Output_1_Bit56_6220_38 m56 : 32|1@1+ (1,0) [0|1] ""  I_O_Device_2
 SG_ Write_Output_1_Bit55_6220_37 m55 : 32|1@1+ (1,0) [0|1] ""  I_O_Device_2
 SG_ Write_Output_1_Bit54_6220_36 m54 : 32|1@1+ (1,0) [0|1] ""  I_O_Device_2
 SG_ Write_Output_1_Bit53_6220_35 m53 : 32|1@1+ (1,0) [0|1] ""  I_O_Device_2
 SG_ Write_Output_1_Bit52_6220_34 m52 : 32|1@1+ (1,0) [0|1] ""  I_O_Device_2
 SG_ Write_Output_1_Bit51_6220_33 m51 : 32|1@1+ (1,0) [0|1] ""  I_O_Device_2
 SG_ Write_Output_1_Bit50_6220_32 m50 : 32|1@1+ (1,0) [0|1] ""  I_O_Device_2
 SG_ Write_Output_1_Bit49_6220_31 m49 : 32|1@1+ (1,0) [0|1] ""  I_O_Device_2
 SG_ Write_Output_1_Bit48_6220_30 m48 : 32|1@1+ (1,0) [0|1] ""  I_O_Device_2
 SG_ Write_Output_1_Bit47_6220_2F m47 : 32|1@1+ (1,0) [0|1] ""  I_O_Device_2
 SG_ Write_Output_1_Bit46_6220_2E m46 : 32|1@1+ (1,0) [0|1] ""  I_O_Device_2
 SG_ Write_Output_1_Bit45_6220_2D m45 : 32|1@1+ (1,0) [0|1] ""  I_O_Device_2
 SG_ Write_Output_1_Bit44_6220_2C m44 : 32|1@1+ (1,0) [0|1] ""  I_O_Device_2
 SG_ Write_Output_1_Bit43_6220_2B m43 : 32|1@1+ (1,0) [0|1] ""  I_O_Device_2
 SG_ Write_Output_1_Bit42_6220_2A m42 : 32|1@1+ (1,0) [0|1] ""  I_O_Device_2
 SG_ Write_Output_1_Bit41_6220_29 m41 : 32|1@1+ (1,0) [0|1] ""  I_O_Device_2
 SG_ Write_Output_1_Bit40_6220_28 m40 : 32|1@1+ (1,0) [0|1] ""  I_O_Device_2
 SG_ Write_Output_1_Bit39_6220_27 m39 : 32|1@1+ (1,0) [0|1] ""  I_O_Device_2
 SG_ Write_Output_1_Bit38_6220_26 m38 : 32|1@1+ (1,0) [0|1] ""  I_O_Device_2
 SG_ Write_Output_1_Bit37_6220_25 m37 : 32|1@1+ (1,0) [0|1] ""  I_O_Device_2
 SG_ Write_Output_1_Bit36_6220_24 m36 : 32|1@1+ (1,0) [0|1] ""  I_O_Device_2
 SG_ Write_Output_1_Bit35_6220_23 m35 : 32|1@1+ (1,0) [0|1] ""  I_O_Device_2
 SG_ Write_Output_1_Bit34_6220_22 m34 : 32|1@1+ (1,0) [0|1] ""  I_O_Device_2
 SG_ Write_Output_1_Bit33_6220_21 m33 : 32|1@1+ (1,0) [0|1] ""  I_O_Device_2
 SG_ Write_Output_1_Bit32_6220_20 m32 : 32|1@1+ (1,0) [0|1] ""  I_O_Device_2
 SG_ Write_Output_1_Bit31_6220_1F m31 : 32|1@1+ (1,0) [0|1] ""  I_O_Device_2
 SG_ Write_Output_1_Bit30_6220_1E m30 : 32|1@1+ (1,0) [0|1] ""  I_O_Device_2
 SG_ Write_Output_1_Bit29_6220_1D m29 : 32|1@1+ (1,0) [0|1] ""  I_O_Device_2
 SG_ Write_Output_1_Bit28_6220_1C m28 : 32|1@1+ (1,0) [0|1] ""  I_O_Device_2
 SG_ Write_Output_1_Bit27_6220_1B m27 : 32|1@1+ (1,0) [0|1] ""  I_O_Device_2
 SG_ Write_Output_1_Bit26_6220_1A m26 : 32|1@1+ (1,0) [0|1] ""  I_O_Device_2
 SG_ Write_Output_1_Bit25_6220_19 m25 : 32|1@1+ (1,0) [0|1] ""  I_O_Device_2
 SG_ Write_Output_1_Bit24_6220_18 m24 : 32|1@1+ (1,0) [0|1] ""  I_O_Device_2
 SG_ Write_Output_1_Bit23_6220_17 m23 : 32|1@1+ (1,0) [0|1] ""  I_O_Device_2
 SG_ Write_Output_1_Bit22_6220_16 m22 : 32|1@1+ (1,0) [0|1] ""  I_O_Device_2
 SG_ Write_Output_1_Bit21_6220_15 m21 : 32|1@1+ (1,0) [0|1] ""  I_O_Device_2
 SG_ Write_Output_1_Bit20_6220_14 m20 : 32|1@1+ (1,0) [0|1] ""  I_O_Device_2
 SG_ Write_Output_1_Bit19_6220_13 m19 : 32|1@1+ (1,0) [0|1] ""  I_O_Device_2
 SG_ Write_Output_1_Bit18_6220_12 m18 : 32|1@1+ (1,0) [0|1] ""  I_O_Device_2
 SG_ Write_Output_1_Bit17_6220_11 m17 : 32|1@1+ (1,0) [0|1] ""  I_O_Device_2
 SG_ Write_Output_1_Bit16_6220_10 m16 : 32|1@1+ (1,0) [0|1] ""  I_O_Device_2
 SG_ Write_Output_1_Bit15_6220_0F m15 : 32|1@1+ (1,0) [0|1] ""  I_O_Device_2
 SG_ Write_Output_1_Bit14_6220_0E m14 : 32|1@1+ (1,0) [0|1] ""  I_O_Device_2
 SG_ Write_Output_1_Bit13_6220_0D m13 : 32|1@1+ (1,0) [0|1] ""  I_O_Device_2
 SG_ Write_Output_1_Bit12_6220_0C m12 : 32|1@1+ (1,0) [0|1] ""  I_O_Device_2
 SG_ Write_Output_1_Bit11_6220_0B m11 : 32|1@1+ (1,0) [0|1] ""  I_O_Device_2
 SG_ Write_Output_1_Bit10_6220_0A m10 : 32|1@1+ (1,0) [0|1] ""  I_O_Device_2
 SG_ Write_Output_1_Bit9_6220_09 m9 : 32|1@1+ (1,0) [0|1] ""  I_O_Device_2
 SG_ Write_Output_1_Bit8_6220_08 m8 : 32|1@1+ (1,0) [0|1] ""  I_O_Device_2
 SG_ Write_Output_1_Bit7_6220_07 m7 : 32|1@1+ (1,0) [0|1] ""  I_O_Device_2
 SG_ Write_Output_1_Bit6_6220_06 m6 : 32|1@1+ (1,0) [0|1] ""  I_O_Device_2
 SG_ Write_Output_1_Bit5_6220_05 m5 : 32|1@1+ (1,0) [0|1] ""  I_O_Device_2
 SG_ Write_Output_1_Bit4_6220_04 m4 : 32|1@1+ (1,0) [0|1] ""  I_O_Device_2
 SG_ Write_Output_1_Bit3_6220_03 m3 : 32|1@1+ (1,0) [0|1] ""  I_O_Device_2
 SG_ Write_Output_1_Bit2_6220_02 m2 : 32|1@1+ (1,0) [0|1] ""  I_O_Device_2
 SG_ Write_Output_1_Bit1_6220_01 m1 : 32|1@1+ (1,0) [0|1] ""  I_O_Device_2
 SG_ NrOfObjects_6220_00 m0 : 32|8@1+ (1,0) [0|255] ""  I_O_Device_2
 SG_ SubIndex_6220 m25120M : 24|8@1+ (1,0) [0|64] ""  I_O_Device_2
 SG_ Write_Output_8_Bit16_6200_10 m16 : 32|8@1+ (1,0) [0|255] ""  I_O_Device_2
 SG_ Write_Output_8_Bit15_6200_0F m15 : 32|8@1+ (1,0) [0|255] ""  I_O_Device_2
 SG_ Write_Output_8_Bit14_6200_0E m14 : 32|8@1+ (1,0) [0|255] ""  I_O_Device_2
 SG_ Write_Output_8_Bit13_6200_0D m13 : 32|8@1+ (1,0) [0|255] ""  I_O_Device_2
 SG_ Write_Output_8_Bit12_6200_0C m12 : 32|8@1+ (1,0) [0|255] ""  I_O_Device_2
 SG_ Write_Output_8_Bit11_6200_0B m11 : 32|8@1+ (1,0) [0|255] ""  I_O_Device_2
 SG_ Write_Output_8_Bit10_6200_0A m10 : 32|8@1+ (1,0) [0|255] ""  I_O_Device_2
 SG_ Write_Output_8_Bit9_6200_09 m9 : 32|8@1+ (1,0) [0|255] ""  I_O_Device_2
 SG_ Write_Output_8_Bit8_6200_08 m8 : 32|8@1+ (1,0) [0|255] ""  I_O_Device_2
 SG_ Write_Output_8_Bit7_6200_07 m7 : 32|8@1+ (1,0) [0|255] ""  I_O_Device_2
 SG_ Write_Output_8_Bit6_6200_06 m6 : 32|8@1+ (1,0) [0|255] ""  I_O_Device_2
 SG_ Write_Output_8_Bit5_6200_05 m5 : 32|8@1+ (1,0) [0|255] ""  I_O_Device_2
 SG_ Write_Output_8_Bit4_6200_04 m4 : 32|8@1+ (1,0) [0|255] ""  I_O_Device_2
 SG_ Write_Output_8_Bit3_6200_03 m3 : 32|8@1+ (1,0) [0|255] ""  I_O_Device_2
 SG_ Write_Output_8_Bit2_6200_02 m2 : 32|8@1+ (1,0) [0|255] ""  I_O_Device_2
 SG_ Write_Output_8_Bit1_6200_01 m1 : 32|8@1+ (1,0) [0|255] ""  I_O_Device_2
 SG_ NrOfObjects_6200_00 m0 : 32|8@1+ (1,0) [0|255] ""  I_O_Device_2
 SG_ SubIndex_6200 m25088M : 24|8@1+ (1,0) [0|16] ""  I_O_Device_2
 SG_ Read_Input_32_Bit16_6120_10 m16 : 32|32@1+ (1,0) [0|4294967295] ""  I_O_Device_2
 SG_ Read_Input_32_Bit15_6120_0F m15 : 32|32@1+ (1,0) [0|4294967295] ""  I_O_Device_2
 SG_ Read_Input_32_Bit14_6120_0E m14 : 32|32@1+ (1,0) [0|4294967295] ""  I_O_Device_2
 SG_ Read_Input_32_Bit13_6120_0D m13 : 32|32@1+ (1,0) [0|4294967295] ""  I_O_Device_2
 SG_ Read_Input_32_Bit12_6120_0C m12 : 32|32@1+ (1,0) [0|4294967295] ""  I_O_Device_2
 SG_ Read_Input_32_Bit11_6120_0B m11 : 32|32@1+ (1,0) [0|4294967295] ""  I_O_Device_2
 SG_ Read_Input_32_Bit10_6120_0A m10 : 32|32@1+ (1,0) [0|4294967295] ""  I_O_Device_2
 SG_ Read_Input_32_Bit9_6120_09 m9 : 32|32@1+ (1,0) [0|4294967295] ""  I_O_Device_2
 SG_ Read_Input_32_Bit8_6120_08 m8 : 32|32@1+ (1,0) [0|4294967295] ""  I_O_Device_2
 SG_ Read_Input_32_Bit7_6120_07 m7 : 32|32@1+ (1,0) [0|4294967295] ""  I_O_Device_2
 SG_ Read_Input_32_Bit6_6120_06 m6 : 32|32@1+ (1,0) [0|4294967295] ""  I_O_Device_2
 SG_ Read_Input_32_Bit5_6120_05 m5 : 32|32@1+ (1,0) [0|4294967295] ""  I_O_Device_2
 SG_ Read_Input_32_Bit4_6120_04 m4 : 32|32@1+ (1,0) [0|4294967295] ""  I_O_Device_2
 SG_ Read_Input_32_Bit3_6120_03 m3 : 32|32@1+ (1,0) [0|4294967295] ""  I_O_Device_2
 SG_ Read_Input_32_Bit2_6120_02 m2 : 32|32@1+ (1,0) [0|4294967295] ""  I_O_Device_2
 SG_ Read_Input_32_Bit1_6120_01 m1 : 32|32@1+ (1,0) [0|4294967295] ""  I_O_Device_2
 SG_ NrOfObjects_6120_00 m0 : 32|8@1+ (1,0) [0|255] ""  I_O_Device_2
 SG_ SubIndex_6120 m24864M : 24|8@1+ (1,0) [0|16] ""  I_O_Device_2
 SG_ Read_Input_16_Bit16_6100_10 m16 : 32|16@1+ (1,0) [0|65535] ""  I_O_Device_2
 SG_ Read_Input_16_Bit15_6100_0F m15 : 32|16@1+ (1,0) [0|65535] ""  I_O_Device_2
 SG_ Read_Input_16_Bit14_6100_0E m14 : 32|16@1+ (1,0) [0|65535] ""  I_O_Device_2
 SG_ Read_Input_16_Bit13_6100_0D m13 : 32|16@1+ (1,0) [0|65535] ""  I_O_Device_2
 SG_ Read_Input_16_Bit12_6100_0C m12 : 32|16@1+ (1,0) [0|65535] ""  I_O_Device_2
 SG_ Read_Input_16_Bit11_6100_0B m11 : 32|16@1+ (1,0) [0|65535] ""  I_O_Device_2
 SG_ Read_Input_16_Bit10_6100_0A m10 : 32|16@1+ (1,0) [0|65535] ""  I_O_Device_2
 SG_ Read_Input_16_Bit9_6100_09 m9 : 32|16@1+ (1,0) [0|65535] ""  I_O_Device_2
 SG_ Read_Input_16_Bit8_6100_08 m8 : 32|16@1+ (1,0) [0|65535] ""  I_O_Device_2
 SG_ Read_Input_16_Bit7_6100_07 m7 : 32|16@1+ (1,0) [0|65535] ""  I_O_Device_2
 SG_ Read_Input_16_Bit6_6100_06 m6 : 32|16@1+ (1,0) [0|65535] ""  I_O_Device_2
 SG_ Read_Input_16_Bit5_6100_05 m5 : 32|16@1+ (1,0) [0|65535] ""  I_O_Device_2
 SG_ Read_Input_16_Bit4_6100_04 m4 : 32|16@1+ (1,0) [0|65535] ""  I_O_Device_2
 SG_ Read_Input_16_Bit3_6100_03 m3 : 32|16@1+ (1,0) [0|65535] ""  I_O_Device_2
 SG_ Read_Input_16_Bit2_6100_02 m2 : 32|16@1+ (1,0) [0|65535] ""  I_O_Device_2
 SG_ Read_Input_16_Bit1_6100_01 m1 : 32|16@1+ (1,0) [0|65535] ""  I_O_Device_2
 SG_ NrOfObjects_6100_00 m0 : 32|8@1+ (1,0) [0|255] ""  I_O_Device_2
 SG_ SubIndex_6100 m24832M : 24|8@1+ (1,0) [0|16] ""  I_O_Device_2
 SG_ Read_Input_1_Bit64_6020_40 m64 : 32|1@1+ (1,0) [0|1] ""  I_O_Device_2
 SG_ Read_Input_1_Bit63_6020_3F m63 : 32|1@1+ (1,0) [0|1] ""  I_O_Device_2
 SG_ Read_Input_1_Bit62_6020_3E m62 : 32|1@1+ (1,0) [0|1] ""  I_O_Device_2
 SG_ Read_Input_1_Bit61_6020_3D m61 : 32|1@1+ (1,0) [0|1] ""  I_O_Device_2
 SG_ Read_Input_1_Bit60_6020_3C m60 : 32|1@1+ (1,0) [0|1] ""  I_O_Device_2
 SG_ Read_Input_1_Bit59_6020_3B m59 : 32|1@1+ (1,0) [0|1] ""  I_O_Device_2
 SG_ Read_Input_1_Bit58_6020_3A m58 : 32|1@1+ (1,0) [0|1] ""  I_O_Device_2
 SG_ Read_Input_1_Bit57_6020_39 m57 : 32|1@1+ (1,0) [0|1] ""  I_O_Device_2
 SG_ Read_Input_1_Bit56_6020_38 m56 : 32|1@1+ (1,0) [0|1] ""  I_O_Device_2
 SG_ Read_Input_1_Bit55_6020_37 m55 : 32|1@1+ (1,0) [0|1] ""  I_O_Device_2
 SG_ Read_Input_1_Bit54_6020_36 m54 : 32|1@1+ (1,0) [0|1] ""  I_O_Device_2
 SG_ Read_Input_1_Bit53_6020_35 m53 : 32|1@1+ (1,0) [0|1] ""  I_O_Device_2
 SG_ Read_Input_1_Bit52_6020_34 m52 : 32|1@1+ (1,0) [0|1] ""  I_O_Device_2
 SG_ Read_Input_1_Bit51_6020_33 m51 : 32|1@1+ (1,0) [0|1] ""  I_O_Device_2
 SG_ Read_Input_1_Bit50_6020_32 m50 : 32|1@1+ (1,0) [0|1] ""  I_O_Device_2
 SG_ Read_Input_1_Bit49_6020_31 m49 : 32|1@1+ (1,0) [0|1] ""  I_O_Device_2
 SG_ Read_Input_1_Bit48_6020_30 m48 : 32|1@1+ (1,0) [0|1] ""  I_O_Device_2
 SG_ Read_Input_1_Bit47_6020_2F m47 : 32|1@1+ (1,0) [0|1] ""  I_O_Device_2
 SG_ Read_Input_1_Bit46_6020_2E m46 : 32|1@1+ (1,0) [0|1] ""  I_O_Device_2
 SG_ Read_Input_1_Bit45_6020_2D m45 : 32|1@1+ (1,0) [0|1] ""  I_O_Device_2
 SG_ Read_Input_1_Bit44_6020_2C m44 : 32|1@1+ (1,0) [0|1] ""  I_O_Device_2
 SG_ Read_Input_1_Bit43_6020_2B m43 : 32|1@1+ (1,0) [0|1] ""  I_O_Device_2
 SG_ Read_Input_1_Bit42_6020_2A m42 : 32|1@1+ (1,0) [0|1] ""  I_O_Device_2
 SG_ Read_Input_1_Bit41_6020_29 m41 : 32|1@1+ (1,0) [0|1] ""  I_O_Device_2
 SG_ Read_Input_1_Bit40_6020_28 m40 : 32|1@1+ (1,0) [0|1] ""  I_O_Device_2
 SG_ Read_Input_1_Bit39_6020_27 m39 : 32|1@1+ (1,0) [0|1] ""  I_O_Device_2
 SG_ Read_Input_1_Bit38_6020_26 m38 : 32|1@1+ (1,0) [0|1] ""  I_O_Device_2
 SG_ Read_Input_1_Bit37_6020_25 m37 : 32|1@1+ (1,0) [0|1] ""  I_O_Device_2
 SG_ Read_Input_1_Bit36_6020_24 m36 : 32|1@1+ (1,0) [0|1] ""  I_O_Device_2
 SG_ Read_Input_1_Bit35_6020_23 m35 : 32|1@1+ (1,0) [0|1] ""  I_O_Device_2
 SG_ Read_Input_1_Bit34_6020_22 m34 : 32|1@1+ (1,0) [0|1] ""  I_O_Device_2
 SG_ Read_Input_1_Bit33_6020_21 m33 : 32|1@1+ (1,0) [0|1] ""  I_O_Device_2
 SG_ Read_Input_1_Bit32_6020_20 m32 : 32|1@1+ (1,0) [0|1] ""  I_O_Device_2
 SG_ Read_Input_1_Bit31_6020_1F m31 : 32|1@1+ (1,0) [0|1] ""  I_O_Device_2
 SG_ Read_Input_1_Bit30_6020_1E m30 : 32|1@1+ (1,0) [0|1] ""  I_O_Device_2
 SG_ Read_Input_1_Bit29_6020_1D m29 : 32|1@1+ (1,0) [0|1] ""  I_O_Device_2
 SG_ Read_Input_1_Bit28_6020_1C m28 : 32|1@1+ (1,0) [0|1] ""  I_O_Device_2
 SG_ Read_Input_1_Bit27_6020_1B m27 : 32|1@1+ (1,0) [0|1] ""  I_O_Device_2
 SG_ Read_Input_1_Bit26_6020_1A m26 : 32|1@1+ (1,0) [0|1] ""  I_O_Device_2
 SG_ Read_Input_1_Bit25_6020_19 m25 : 32|1@1+ (1,0) [0|1] ""  I_O_Device_2
 SG_ Read_Input_1_Bit24_6020_18 m24 : 32|1@1+ (1,0) [0|1] ""  I_O_Device_2
 SG_ Read_Input_1_Bit23_6020_17 m23 : 32|1@1+ (1,0) [0|1] ""  I_O_Device_2
 SG_ Read_Input_1_Bit22_6020_16 m22 : 32|1@1+ (1,0) [0|1] ""  I_O_Device_2
 SG_ Read_Input_1_Bit21_6020_15 m21 : 32|1@1+ (1,0) [0|1] ""  I_O_Device_2
 SG_ Read_Input_1_Bit20_6020_14 m20 : 32|1@1+ (1,0) [0|1] ""  I_O_Device_2
 SG_ Read_Input_1_Bit19_6020_13 m19 : 32|1@1+ (1,0) [0|1] ""  I_O_Device_2
 SG_ Read_Input_1_Bit18_6020_12 m18 : 32|1@1+ (1,0) [0|1] ""  I_O_Device_2
 SG_ Read_Input_1_Bit17_6020_11 m17 : 32|1@1+ (1,0) [0|1] ""  I_O_Device_2
 SG_ Read_Input_1_Bit16_6020_10 m16 : 32|1@1+ (1,0) [0|1] ""  I_O_Device_2
 SG_ Read_Input_1_Bit15_6020_0F m15 : 32|1@1+ (1,0) [0|1] ""  I_O_Device_2
 SG_ Read_Input_1_Bit14_6020_0E m14 : 32|1@1+ (1,0) [0|1] ""  I_O_Device_2
 SG_ Read_Input_1_Bit13_6020_0D m13 : 32|1@1+ (1,0) [0|1] ""  I_O_Device_2
 SG_ Read_Input_1_Bit12_6020_0C m12 : 32|1@1+ (1,0) [0|1] ""  I_O_Device_2
 SG_ Read_Input_1_Bit11_6020_0B m11 : 32|1@1+ (1,0) [0|1] ""  I_O_Device_2
 SG_ Read_Input_1_Bit10_6020_0A m10 : 32|1@1+ (1,0) [0|1] ""  I_O_Device_2
 SG_ Read_Input_1_Bit9_6020_09 m9 : 32|1@1+ (1,0) [0|1] ""  I_O_Device_2
 SG_ Read_Input_1_Bit8_6020_08 m8 : 32|1@1+ (1,0) [0|1] ""  I_O_Device_2
 SG_ Read_Input_1_Bit7_6020_07 m7 : 32|1@1+ (1,0) [0|1] ""  I_O_Device_2
 SG_ Read_Input_1_Bit6_6020_06 m6 : 32|1@1+ (1,0) [0|1] ""  I_O_Device_2
 SG_ Read_Input_1_Bit5_6020_05 m5 : 32|1@1+ (1,0) [0|1] ""  I_O_Device_2
 SG_ Read_Input_1_Bit4_6020_04 m4 : 32|1@1+ (1,0) [0|1] ""  I_O_Device_2
 SG_ Read_Input_1_Bit3_6020_03 m3 : 32|1@1+ (1,0) [0|1] ""  I_O_Device_2
 SG_ Read_Input_1_Bit2_6020_02 m2 : 32|1@1+ (1,0) [0|1] ""  I_O_Device_2
 SG_ Read_Input_1_Bit1_6020_01 m1 : 32|1@1+ (1,0) [0|1] ""  I_O_Device_2
 SG_ NrOfObjects_6020_00 m0 : 32|8@1+ (1,0) [0|255] ""  I_O_Device_2
 SG_ SubIndex_6020 m24608M : 24|8@1+ (1,0) [0|64] ""  I_O_Device_2
 SG_ Read_Input_8_Bit16_6000_10 m16 : 32|8@1+ (1,0) [0|255] ""  I_O_Device_2
 SG_ Read_Input_8_Bit15_6000_0F m15 : 32|8@1+ (1,0) [0|255] ""  I_O_Device_2
 SG_ Read_Input_8_Bit14_6000_0E m14 : 32|8@1+ (1,0) [0|255] ""  I_O_Device_2
 SG_ Read_Input_8_Bit13_6000_0D m13 : 32|8@1+ (1,0) [0|255] ""  I_O_Device_2
 SG_ Read_Input_8_Bit12_6000_0C m12 : 32|8@1+ (1,0) [0|255] ""  I_O_Device_2
 SG_ Read_Input_8_Bit11_6000_0B m11 : 32|8@1+ (1,0) [0|255] ""  I_O_Device_2
 SG_ Read_Input_8_Bit10_6000_0A m10 : 32|8@1+ (1,0) [0|255] ""  I_O_Device_2
 SG_ Read_Input_8_Bit9_6000_09 m9 : 32|8@1+ (1,0) [0|255] ""  I_O_Device_2
 SG_ Read_Input_8_Bit8_6000_08 m8 : 32|8@1+ (1,0) [0|255] ""  I_O_Device_2
 SG_ Read_Input_8_Bit7_6000_07 m7 : 32|8@1+ (1,0) [0|255] ""  I_O_Device_2
 SG_ Read_Input_8_Bit6_6000_06 m6 : 32|8@1+ (1,0) [0|255] ""  I_O_Device_2
 SG_ Read_Input_8_Bit5_6000_05 m5 : 32|8@1+ (1,0) [0|255] ""  I_O_Device_2
 SG_ Read_Input_8_Bit4_6000_04 m4 : 32|8@1+ (1,0) [0|255] ""  I_O_Device_2
 SG_ Read_Input_8_Bit3_6000_03 m3 : 32|8@1+ (1,0) [0|255] ""  I_O_Device_2
 SG_ Read_Input_8_Bit2_6000_02 m2 : 32|8@1+ (1,0) [0|255] ""  I_O_Device_2
 SG_ Read_Input_8_Bit1_6000_01 m1 : 32|8@1+ (1,0) [0|255] ""  I_O_Device_2
 SG_ NrOfObjects_6000_00 m0 : 32|8@1+ (1,0) [0|255] ""  I_O_Device_2
 SG_ SubIndex_6000 m24576M : 24|8@1+ (1,0) [0|16] ""  I_O_Device_2
 SG_ NrOfObjects_2300_00 m0 : 32|8@1+ (1,0) [0|255] ""  I_O_Device_2
 SG_ SubIndex_2300 m8960M : 24|8@1+ (1,0) [0|4] ""  I_O_Device_2
 SG_ NrOfObjects_2200_00 m0 : 32|8@1+ (1,0) [0|255] ""  I_O_Device_2
 SG_ SubIndex_2200 m8704M : 24|8@1+ (1,0) [0|4] ""  I_O_Device_2
 SG_ NrOfMappedObjects_1A03_00 m0 : 32|8@1+ (1,0) [0|64] ""  I_O_Device_2
 SG_ SubIndex_1A03 m6659M : 24|8@1+ (1,0) [0|0] ""  I_O_Device_2
 SG_ NrOfMappedObjects_1A02_00 m0 : 32|8@1+ (1,0) [0|64] ""  I_O_Device_2
 SG_ SubIndex_1A02 m6658M : 24|8@1+ (1,0) [0|0] ""  I_O_Device_2
 SG_ NrOfMappedObjects_1A01_00 m0 : 32|8@1+ (1,0) [0|64] ""  I_O_Device_2
 SG_ SubIndex_1A01 m6657M : 24|8@1+ (1,0) [0|0] ""  I_O_Device_2
 SG_ NrOfMappedObjects_1A00_00 m0 : 32|8@1+ (1,0) [0|64] ""  I_O_Device_2
 SG_ SubIndex_1A00 m6656M : 24|8@1+ (1,0) [0|0] ""  I_O_Device_2
 SG_ EventTimer_1803_05 m5 : 32|16@1+ (1,0) [0|65535] ""  I_O_Device_2
 SG_ TransmissionType_1803_02 m2 : 32|8@1+ (1,0) [0|255] ""  I_O_Device_2
 SG_ COB_ID_1803_01 m1 : 32|32@1+ (1,0) [128|4294967295] ""  I_O_Device_2
 SG_ NrOfEntries_1803_00 m0 : 32|8@1+ (1,0) [2|5] ""  I_O_Device_2
 SG_ SubIndex_1803 m6147M : 24|8@1+ (1,0) [0|5] ""  I_O_Device_2
 SG_ EventTimer_1802_05 m5 : 32|16@1+ (1,0) [0|65535] ""  I_O_Device_2
 SG_ TransmissionType_1802_02 m2 : 32|8@1+ (1,0) [0|255] ""  I_O_Device_2
 SG_ COB_ID_1802_01 m1 : 32|32@1+ (1,0) [128|4294967295] ""  I_O_Device_2
 SG_ NrOfEntries_1802_00 m0 : 32|8@1+ (1,0) [2|5] ""  I_O_Device_2
 SG_ SubIndex_1802 m6146M : 24|8@1+ (1,0) [0|5] ""  I_O_Device_2
 SG_ EventTimer_1801_05 m5 : 32|16@1+ (1,0) [0|65535] ""  I_O_Device_2
 SG_ TransmissionType_1801_02 m2 : 32|8@1+ (1,0) [0|255] ""  I_O_Device_2
 SG_ COB_ID_1801_01 m1 : 32|32@1+ (1,0) [128|4294967295] ""  I_O_Device_2
 SG_ NrOfEntries_1801_00 m0 : 32|8@1+ (1,0) [2|5] ""  I_O_Device_2
 SG_ SubIndex_1801 m6145M : 24|8@1+ (1,0) [0|5] ""  I_O_Device_2
 SG_ EventTimer_1800_05 m5 : 32|16@1+ (1,0) [0|65535] ""  I_O_Device_2
 SG_ TransmissionType_1800_02 m2 : 32|8@1+ (1,0) [0|255] ""  I_O_Device_2
 SG_ COB_ID_1800_01 m1 : 32|32@1+ (1,0) [128|4294967295] ""  I_O_Device_2
 SG_ NrOfEntries_1800_00 m0 : 32|8@1+ (1,0) [2|5] ""  I_O_Device_2
 SG_ SubIndex_1800 m6144M : 24|8@1+ (1,0) [0|5] ""  I_O_Device_2
 SG_ NrOfMappedObjects_1603_00 m0 : 32|8@1+ (1,0) [0|64] ""  I_O_Device_2
 SG_ SubIndex_1603 m5635M : 24|8@1+ (1,0) [0|0] ""  I_O_Device_2
 SG_ NrOfMappedObjects_1602_00 m0 : 32|8@1+ (1,0) [0|64] ""  I_O_Device_2
 SG_ SubIndex_1602 m5634M : 24|8@1+ (1,0) [0|0] ""  I_O_Device_2
 SG_ NrOfMappedObjects_1601_00 m0 : 32|8@1+ (1,0) [0|64] ""  I_O_Device_2
 SG_ SubIndex_1601 m5633M : 24|8@1+ (1,0) [0|0] ""  I_O_Device_2
 SG_ mappedObj2_1600_02 m2 : 32|32@1+ (1,0) [0|4294967295] ""  I_O_Device_2
 SG_ mappedObj1_1600_01 m1 : 32|32@1+ (1,0) [0|4294967295] ""  I_O_Device_2
 SG_ NrOfMappedObjects_1600_00 m0 : 32|8@1+ (1,0) [0|64] ""  I_O_Device_2
 SG_ SubIndex_1600 m5632M : 24|8@1+ (1,0) [0|2] ""  I_O_Device_2
 SG_ TransmissionType_1403_02 m2 : 32|8@1+ (1,0) [0|255] ""  I_O_Device_2
 SG_ COB_ID_1403_01 m1 : 32|32@1+ (1,0) [128|4294967295] ""  I_O_Device_2
 SG_ NrOfEntries_1403_00 m0 : 32|8@1+ (1,0) [2|5] ""  I_O_Device_2
 SG_ SubIndex_1403 m5123M : 24|8@1+ (1,0) [0|2] ""  I_O_Device_2
 SG_ TransmissionType_1402_02 m2 : 32|8@1+ (1,0) [0|255] ""  I_O_Device_2
 SG_ COB_ID_1402_01 m1 : 32|32@1+ (1,0) [128|4294967295] ""  I_O_Device_2
 SG_ NrOfEntries_1402_00 m0 : 32|8@1+ (1,0) [2|5] ""  I_O_Device_2
 SG_ SubIndex_1402 m5122M : 24|8@1+ (1,0) [0|2] ""  I_O_Device_2
 SG_ TransmissionType_1401_02 m2 : 32|8@1+ (1,0) [0|255] ""  I_O_Device_2
 SG_ COB_ID_1401_01 m1 : 32|32@1+ (1,0) [128|4294967295] ""  I_O_Device_2
 SG_ NrOfEntries_1401_00 m0 : 32|8@1+ (1,0) [2|5] ""  I_O_Device_2
 SG_ SubIndex_1401 m5121M : 24|8@1+ (1,0) [0|2] ""  I_O_Device_2
 SG_ TransmissionType_1400_02 m2 : 32|8@1+ (1,0) [0|255] ""  I_O_Device_2
 SG_ COB_ID_1400_01 m1 : 32|32@1+ (1,0) [128|4294967295] ""  I_O_Device_2
 SG_ NrOfEntries_1400_00 m0 : 32|8@1+ (1,0) [2|5] ""  I_O_Device_2
 SG_ SubIndex_1400 m5120M : 24|8@1+ (1,0) [0|2] ""  I_O_Device_2
 SG_ Serial_number_1018_04 m4 : 32|32@1+ (1,0) [0|4294967295] ""  I_O_Device_2
 SG_ Revision_number_1018_03 m3 : 32|32@1+ (1,0) [0|4294967295] ""  I_O_Device_2
 SG_ Product_Code_1018_02 m2 : 32|32@1+ (1,0) [0|4294967295] ""  I_O_Device_2
 SG_ Vendor_Id_1018_01 m1 : 32|32@1+ (1,0) [0|4294967295] ""  I_O_Device_2
 SG_ number_of_entries_1018_00 m0 : 32|8@1+ (1,0) [1|4] ""  I_O_Device_2
 SG_ SubIndex_1018 m4120M : 24|8@1+ (1,0) [0|4] ""  I_O_Device_2
 SG_ Producer_Heartbeat_Time_1017 m0 : 32|16@1+ (1,0) [0|65535] ""  I_O_Device_2
 SG_ SubIndex_1017 m4119M : 24|8@1+ (1,0) [0|0] ""  I_O_Device_2
 SG_ Consumer_Heartbeat_Time16_1_0000 m16 : 32|32@1+ (1,0) [0|4294967295] ""  I_O_Device_2
 SG_ Consumer_Heartbeat_Time15_1_0000 m15 : 32|32@1+ (1,0) [0|4294967295] ""  I_O_Device_2
 SG_ Consumer_Heartbeat_Time14_1_0000 m14 : 32|32@1+ (1,0) [0|4294967295] ""  I_O_Device_2
 SG_ Consumer_Heartbeat_Time13_1_0000 m13 : 32|32@1+ (1,0) [0|4294967295] ""  I_O_Device_2
 SG_ Consumer_Heartbeat_Time12_1_0000 m12 : 32|32@1+ (1,0) [0|4294967295] ""  I_O_Device_2
 SG_ Consumer_Heartbeat_Time11_1_0000 m11 : 32|32@1+ (1,0) [0|4294967295] ""  I_O_Device_2
 SG_ Consumer_Heartbeat_Time10_1_0000 m10 : 32|32@1+ (1,0) [0|4294967295] ""  I_O_Device_2
 SG_ Consumer_Heartbeat_Time9_1016_09 m9 : 32|32@1+ (1,0) [0|4294967295] ""  I_O_Device_2
 SG_ Consumer_Heartbeat_Time8_1016_08 m8 : 32|32@1+ (1,0) [0|4294967295] ""  I_O_Device_2
 SG_ Consumer_Heartbeat_Time7_1016_07 m7 : 32|32@1+ (1,0) [0|4294967295] ""  I_O_Device_2
 SG_ Consumer_Heartbeat_Time6_1016_06 m6 : 32|32@1+ (1,0) [0|4294967295] ""  I_O_Device_2
 SG_ Consumer_Heartbeat_Time5_1016_05 m5 : 32|32@1+ (1,0) [0|4294967295] ""  I_O_Device_2
 SG_ Consumer_Heartbeat_Time4_1016_04 m4 : 32|32@1+ (1,0) [0|4294967295] ""  I_O_Device_2
 SG_ Consumer_Heartbeat_Time3_1016_03 m3 : 32|32@1+ (1,0) [0|4294967295] ""  I_O_Device_2
 SG_ Consumer_Heartbeat_Time2_1016_02 m2 : 32|32@1+ (1,0) [0|4294967295] ""  I_O_Device_2
 SG_ Consumer_Heartbeat_Time1_1016_01 m1 : 32|32@1+ (1,0) [0|4294967295] ""  I_O_Device_2
 SG_ NrOfObjects_1016_00 m0 : 32|8@1+ (1,0) [0|255] ""  I_O_Device_2
 SG_ SubIndex_1016 m4118M : 24|8@1+ (1,0) [0|16] ""  I_O_Device_2
 SG_ COB_ID_EMCY_1014 m0 : 32|32@1+ (1,0) [128|3221225471] ""  I_O_Device_2
 SG_ SubIndex_1014 m4116M : 24|8@1+ (1,0) [0|0] ""  I_O_Device_2
 SG_ Restore_all_Default_Paramet_0000 m1 : 32|32@1+ (1,0) [0|4294967295] ""  I_O_Device_2
 SG_ Number_of_Entries_1011_00 m0 : 32|8@1+ (1,0) [0|255] ""  I_O_Device_2
 SG_ SubIndex_1011 m4113M : 24|8@1+ (1,0) [0|1] ""  I_O_Device_2
 SG_ Save_all_Parameters_1010_01 m1 : 32|32@1+ (1,0) [0|4294967295] ""  I_O_Device_2
 SG_ Number_of_Entries_1010_00 m0 : 32|8@1+ (1,0) [0|255] ""  I_O_Device_2
 SG_ SubIndex_1010 m4112M : 24|8@1+ (1,0) [0|1] ""  I_O_Device_2
 SG_ Life_Time_Factor_100D m0 : 32|8@1+ (1,0) [0|255] ""  I_O_Device_2
 SG_ SubIndex_100D m4109M : 24|8@1+ (1,0) [0|0] ""  I_O_Device_2
 SG_ Guard_Time_100C m0 : 32|16@1+ (1,0) [0|65535] ""  I_O_Device_2
 SG_ SubIndex_100C m4108M : 24|8@1+ (1,0) [0|0] ""  I_O_Device_2
 SG_ Synchronous_Window_Length_1007 m0 : 32|32@1+ (1,0) [0|4294967295] ""  I_O_Device_2
 SG_ SubIndex_1007 m4103M : 24|8@1+ (1,0) [0|0] ""  I_O_Device_2
 SG_ Communication_Cycle_Period_1006 m0 : 32|32@1+ (1,0) [0|4294967295] ""  I_O_Device_2
 SG_ SubIndex_1006 m4102M : 24|8@1+ (1,0) [0|0] ""  I_O_Device_2
 SG_ COB_ID_SYNC_1005 m0 : 32|32@1+ (1,0) [128|4294967295] ""  I_O_Device_2
 SG_ SubIndex_1005 m4101M : 24|8@1+ (1,0) [0|0] ""  I_O_Device_2
 SG_ Standard_error_field_1003_09 m9 : 32|32@1+ (1,0) [0|4294967295] ""  I_O_Device_2
 SG_ Standard_error_field_1003_08 m8 : 32|32@1+ (1,0) [0|4294967295] ""  I_O_Device_2
 SG_ Standard_error_field_1003_07 m7 : 32|32@1+ (1,0) [0|4294967295] ""  I_O_Device_2
 SG_ Standard_error_field_1003_06 m6 : 32|32@1+ (1,0) [0|4294967295] ""  I_O_Device_2
 SG_ Standard_error_field_1003_05 m5 : 32|32@1+ (1,0) [0|4294967295] ""  I_O_Device_2
 SG_ Standard_error_field_1003_04 m4 : 32|32@1+ (1,0) [0|4294967295] ""  I_O_Device_2
 SG_ Standard_error_field_1003_03 m3 : 32|32@1+ (1,0) [0|4294967295] ""  I_O_Device_2
 SG_ Standard_error_field_1003_02 m2 : 32|32@1+ (1,0) [0|4294967295] ""  I_O_Device_2
 SG_ Standard_error_field_1003_01 m1 : 32|32@1+ (1,0) [0|4294967295] ""  I_O_Device_2
 SG_ Number_of_Errors_1003_00 m0 : 32|8@1+ (1,0) [0|255] ""  I_O_Device_2
 SG_ SubIndex_1003 m4099M : 24|8@1+ (1,0) [0|9] ""  I_O_Device_2
 SG_ Error_Register_1001 m0 : 32|8@1+ (1,0) [0|255] ""  I_O_Device_2
 SG_ SubIndex_1001 m4097M : 24|8@1+ (1,0) [0|0] ""  I_O_Device_2
 SG_ Device_Type_1000 m0 : 32|32@1+ (1,0) [0|4294967295] ""  I_O_Device_2
 SG_ SubIndex_1000 m4096M : 24|8@1+ (1,0) [0|0] ""  I_O_Device_2
 SG_ Index m1M : 8|16@1+ (1,0) [4096|25376] ""  I_O_Device_2
 SG_ TransferType m1M : 1|1@1+ (1,0) [0|1] ""  I_O_Device_2
 SG_ NotUsedBytes m1 : 2|2@1+ (1,0) [0|3] ""  I_O_Device_2
 SG_ SizeIndicator m1 : 0|1@1+ (1,0) [0|1] ""  I_O_Device_2
 SG_ CCS M : 5|3@1+ (1,0) [0|6] ""  I_O_Device_2

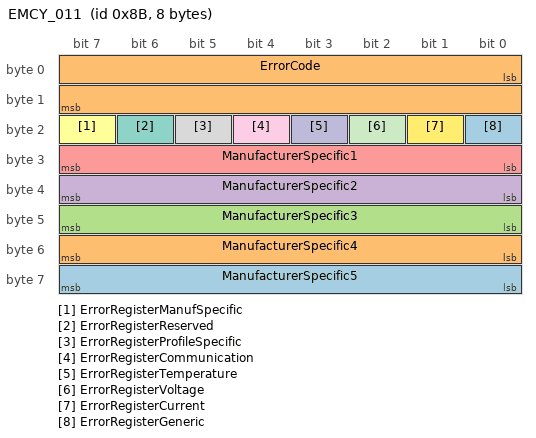
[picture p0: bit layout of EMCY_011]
BO_ 139 EMCY_011: 8 I_O_Device_2
 SG_ ManufacturerSpecific5 : 56|8@1+ (1,0) [0|0] "" Vector__XXX
 SG_ ManufacturerSpecific4 : 48|8@1+ (1,0) [0|0] "" Vector__XXX
 SG_ ManufacturerSpecific3 : 40|8@1+ (1,0) [0|0] "" Vector__XXX
 SG_ ManufacturerSpecific2 : 32|8@1+ (1,0) [0|0] "" Vector__XXX
 SG_ ManufacturerSpecific1 : 24|8@1+ (1,0) [0|0] "" Vector__XXX
 SG_ ErrorRegisterManufSpecific : 23|1@1+ (1,0) [0|0] "" Vector__XXX
 SG_ ErrorRegisterReserved : 22|1@1+ (1,0) [0|0] "" Vector__XXX
 SG_ ErrorRegisterProfileSpecific : 21|1@1+ (1,0) [0|0] "" Vector__XXX
 SG_ ErrorRegisterCommunication : 20|1@1+ (1,0) [0|0] "" Vector__XXX
 SG_ ErrorRegisterTemperature : 19|1@1+ (1,0) [0|0] "" Vector__XXX
 SG_ ErrorRegisterVoltage : 18|1@1+ (1,0) [0|0] "" Vector__XXX
 SG_ ErrorRegisterCurrent : 17|1@1+ (1,0) [0|0] "" Vector__XXX
 SG_ ErrorRegisterGeneric : 16|1@1+ (1,0) [0|0] "" Vector__XXX
 SG_ ErrorCode : 0|16@1+ (1,0) [0|0] "" Vector__XXX

BO_ 1793 HBGuard_001: 1 Master
 SG_ Toggle : 7|1@1+ (1,0) [0|0] "" Vector__XXX
 SG_ State : 0|7@1+ (1,0) [0|0] "" Vector__XXX

BO_ 1409 SSDO_001: 8 Master
 SG_ ReadInput8_Bit4_A4C0_02 m2 : 32|8@1+ (1,0) [0|255] "" Vector__XXX
 SG_ ReadInput8_Bit3_A4C0_01 m1 : 32|8@1+ (1,0) [0|255] "" Vector__XXX
 SG_ NrOfObjects_A4C0_00 m0 : 32|8@1+ (1,0) [0|255] "" Vector__XXX
 SG_ SubIndex_A4C0 m42176M : 24|8@1+ (1,0) [0|2] "" Vector__XXX
 SG_ BootTime_1F89 m0 : 32|32@1+ (1,0) [0|4294967295] "" Vector__XXX
 SG_ SubIndex_1F89 m8073M : 24|8@1+ (1,0) [0|0] "" Vector__XXX
 SG_ SerialNumber127_1F88_7F m127 : 32|32@1+ (1,0) [0|4294967295] "" Vector__XXX
 SG_ SerialNumber126_1F88_7E m126 : 32|32@1+ (1,0) [0|4294967295] "" Vector__XXX
 SG_ SerialNumber125_1F88_7D m125 : 32|32@1+ (1,0) [0|4294967295] "" Vector__XXX
 SG_ SerialNumber124_1F88_7C m124 : 32|32@1+ (1,0) [0|4294967295] "" Vector__XXX
 SG_ SerialNumber123_1F88_7B m123 : 32|32@1+ (1,0) [0|4294967295] "" Vector__XXX
 SG_ SerialNumber122_1F88_7A m122 : 32|32@1+ (1,0) [0|4294967295] "" Vector__XXX
 SG_ SerialNumber121_1F88_79 m121 : 32|32@1+ (1,0) [0|4294967295] "" Vector__XXX
 SG_ SerialNumber120_1F88_78 m120 : 32|32@1+ (1,0) [0|4294967295] "" Vector__XXX
 SG_ SerialNumber119_1F88_77 m119 : 32|32@1+ (1,0) [0|4294967295] "" Vector__XXX
 SG_ SerialNumber118_1F88_76 m118 : 32|32@1+ (1,0) [0|4294967295] "" Vector__XXX
 SG_ SerialNumber117_1F88_75 m117 : 32|32@1+ (1,0) [0|4294967295] "" Vector__XXX
 SG_ SerialNumber116_1F88_74 m116 : 32|32@1+ (1,0) [0|4294967295] "" Vector__XXX
 SG_ SerialNumber115_1F88_73 m115 : 32|32@1+ (1,0) [0|4294967295] "" Vector__XXX
 SG_ SerialNumber114_1F88_72 m114 : 32|32@1+ (1,0) [0|4294967295] "" Vector__XXX
 SG_ SerialNumber113_1F88_71 m113 : 32|32@1+ (1,0) [0|4294967295] "" Vector__XXX
 SG_ SerialNumber112_1F88_70 m112 : 32|32@1+ (1,0) [0|4294967295] "" Vector__XXX
 SG_ SerialNumber111_1F88_6F m111 : 32|32@1+ (1,0) [0|4294967295] "" Vector__XXX
 SG_ SerialNumber110_1F88_6E m110 : 32|32@1+ (1,0) [0|4294967295] "" Vector__XXX
 SG_ SerialNumber109_1F88_6D m109 : 32|32@1+ (1,0) [0|4294967295] "" Vector__XXX
 SG_ SerialNumber108_1F88_6C m108 : 32|32@1+ (1,0) [0|4294967295] "" Vector__XXX
 SG_ SerialNumber107_1F88_6B m107 : 32|32@1+ (1,0) [0|4294967295] "" Vector__XXX
 SG_ SerialNumber106_1F88_6A m106 : 32|32@1+ (1,0) [0|4294967295] "" Vector__XXX
 SG_ SerialNumber105_1F88_69 m105 : 32|32@1+ (1,0) [0|4294967295] "" Vector__XXX
 SG_ SerialNumber104_1F88_68 m104 : 32|32@1+ (1,0) [0|4294967295] "" Vector__XXX
 SG_ SerialNumber103_1F88_67 m103 : 32|32@1+ (1,0) [0|4294967295] "" Vector__XXX
 SG_ SerialNumber102_1F88_66 m102 : 32|32@1+ (1,0) [0|4294967295] "" Vector__XXX
 SG_ SerialNumber101_1F88_65 m101 : 32|32@1+ (1,0) [0|4294967295] "" Vector__XXX
 SG_ SerialNumber100_1F88_64 m100 : 32|32@1+ (1,0) [0|4294967295] "" Vector__XXX
 SG_ SerialNumber99_1F88_63 m99 : 32|32@1+ (1,0) [0|4294967295] "" Vector__XXX
 SG_ SerialNumber98_1F88_62 m98 : 32|32@1+ (1,0) [0|4294967295] "" Vector__XXX
 SG_ SerialNumber97_1F88_61 m97 : 32|32@1+ (1,0) [0|4294967295] "" Vector__XXX
 SG_ SerialNumber96_1F88_60 m96 : 32|32@1+ (1,0) [0|4294967295] "" Vector__XXX
 SG_ SerialNumber95_1F88_5F m95 : 32|32@1+ (1,0) [0|4294967295] "" Vector__XXX
 SG_ SerialNumber94_1F88_5E m94 : 32|32@1+ (1,0) [0|4294967295] "" Vector__XXX
 SG_ SerialNumber93_1F88_5D m93 : 32|32@1+ (1,0) [0|4294967295] "" Vector__XXX
 SG_ SerialNumber92_1F88_5C m92 : 32|32@1+ (1,0) [0|4294967295] "" Vector__XXX
 SG_ SerialNumber91_1F88_5B m91 : 32|32@1+ (1,0) [0|4294967295] "" Vector__XXX
 SG_ SerialNumber90_1F88_5A m90 : 32|32@1+ (1,0) [0|4294967295] "" Vector__XXX
 SG_ SerialNumber89_1F88_59 m89 : 32|32@1+ (1,0) [0|4294967295] "" Vector__XXX
 SG_ SerialNumber88_1F88_58 m88 : 32|32@1+ (1,0) [0|4294967295] "" Vector__XXX
 SG_ SerialNumber87_1F88_57 m87 : 32|32@1+ (1,0) [0|4294967295] "" Vector__XXX
 SG_ SerialNumber86_1F88_56 m86 : 32|32@1+ (1,0) [0|4294967295] "" Vector__XXX
 SG_ SerialNumber85_1F88_55 m85 : 32|32@1+ (1,0) [0|4294967295] "" Vector__XXX
 SG_ SerialNumber84_1F88_54 m84 : 32|32@1+ (1,0) [0|4294967295] "" Vector__XXX
 SG_ SerialNumber83_1F88_53 m83 : 32|32@1+ (1,0) [0|4294967295] "" Vector__XXX
 SG_ SerialNumber82_1F88_52 m82 : 32|32@1+ (1,0) [0|4294967295] "" Vector__XXX
 SG_ SerialNumber81_1F88_51 m81 : 32|32@1+ (1,0) [0|4294967295] "" Vector__XXX
 SG_ SerialNumber80_1F88_50 m80 : 32|32@1+ (1,0) [0|4294967295] "" Vector__XXX
 SG_ SerialNumber79_1F88_4F m79 : 32|32@1+ (1,0) [0|4294967295] "" Vector__XXX
 SG_ SerialNumber78_1F88_4E m78 : 32|32@1+ (1,0) [0|4294967295] "" Vector__XXX
 SG_ SerialNumber77_1F88_4D m77 : 32|32@1+ (1,0) [0|4294967295] "" Vector__XXX
 SG_ SerialNumber76_1F88_4C m76 : 32|32@1+ (1,0) [0|4294967295] "" Vector__XXX
 SG_ SerialNumber75_1F88_4B m75 : 32|32@1+ (1,0) [0|4294967295] "" Vector__XXX
 SG_ SerialNumber74_1F88_4A m74 : 32|32@1+ (1,0) [0|4294967295] "" Vector__XXX
 SG_ SerialNumber73_1F88_49 m73 : 32|32@1+ (1,0) [0|4294967295] "" Vector__XXX
 SG_ SerialNumber72_1F88_48 m72 : 32|32@1+ (1,0) [0|4294967295] "" Vector__XXX
 SG_ SerialNumber71_1F88_47 m71 : 32|32@1+ (1,0) [0|4294967295] "" Vector__XXX
 SG_ SerialNumber70_1F88_46 m70 : 32|32@1+ (1,0) [0|4294967295] "" Vector__XXX
 SG_ SerialNumber69_1F88_45 m69 : 32|32@1+ (1,0) [0|4294967295] "" Vector__XXX
 SG_ SerialNumber68_1F88_44 m68 : 32|32@1+ (1,0) [0|4294967295] "" Vector__XXX
 SG_ SerialNumber67_1F88_43 m67 : 32|32@1+ (1,0) [0|4294967295] "" Vector__XXX
 SG_ SerialNumber66_1F88_42 m66 : 32|32@1+ (1,0) [0|4294967295] "" Vector__XXX
 SG_ SerialNumber65_1F88_41 m65 : 32|32@1+ (1,0) [0|4294967295] "" Vector__XXX
 SG_ SerialNumber64_1F88_40 m64 : 32|32@1+ (1,0) [0|4294967295] "" Vector__XXX
 SG_ SerialNumber63_1F88_3F m63 : 32|32@1+ (1,0) [0|4294967295] "" Vector__XXX
 SG_ SerialNumber62_1F88_3E m62 : 32|32@1+ (1,0) [0|4294967295] "" Vector__XXX
 SG_ SerialNumber61_1F88_3D m61 : 32|32@1+ (1,0) [0|4294967295] "" Vector__XXX
 SG_ SerialNumber60_1F88_3C m60 : 32|32@1+ (1,0) [0|4294967295] "" Vector__XXX
 SG_ SerialNumber59_1F88_3B m59 : 32|32@1+ (1,0) [0|4294967295] "" Vector__XXX
 SG_ SerialNumber58_1F88_3A m58 : 32|32@1+ (1,0) [0|4294967295] "" Vector__XXX
 SG_ SerialNumber57_1F88_39 m57 : 32|32@1+ (1,0) [0|4294967295] "" Vector__XXX
 SG_ SerialNumber56_1F88_38 m56 : 32|32@1+ (1,0) [0|4294967295] "" Vector__XXX
 SG_ SerialNumber55_1F88_37 m55 : 32|32@1+ (1,0) [0|4294967295] "" Vector__XXX
 SG_ SerialNumber54_1F88_36 m54 : 32|32@1+ (1,0) [0|4294967295] "" Vector__XXX
 SG_ SerialNumber53_1F88_35 m53 : 32|32@1+ (1,0) [0|4294967295] "" Vector__XXX
 SG_ SerialNumber52_1F88_34 m52 : 32|32@1+ (1,0) [0|4294967295] "" Vector__XXX
 SG_ SerialNumber51_1F88_33 m51 : 32|32@1+ (1,0) [0|4294967295] "" Vector__XXX
 SG_ SerialNumber50_1F88_32 m50 : 32|32@1+ (1,0) [0|4294967295] "" Vector__XXX
 SG_ SerialNumber49_1F88_31 m49 : 32|32@1+ (1,0) [0|4294967295] "" Vector__XXX
 SG_ SerialNumber48_1F88_30 m48 : 32|32@1+ (1,0) [0|4294967295] "" Vector__XXX
 SG_ SerialNumber47_1F88_2F m47 : 32|32@1+ (1,0) [0|4294967295] "" Vector__XXX
 SG_ SerialNumber46_1F88_2E m46 : 32|32@1+ (1,0) [0|4294967295] "" Vector__XXX
 SG_ SerialNumber45_1F88_2D m45 : 32|32@1+ (1,0) [0|4294967295] "" Vector__XXX
 SG_ SerialNumber44_1F88_2C m44 : 32|32@1+ (1,0) [0|4294967295] "" Vector__XXX
 SG_ SerialNumber43_1F88_2B m43 : 32|32@1+ (1,0) [0|4294967295] "" Vector__XXX
 SG_ SerialNumber42_1F88_2A m42 : 32|32@1+ (1,0) [0|4294967295] "" Vector__XXX
 SG_ SerialNumber41_1F88_29 m41 : 32|32@1+ (1,0) [0|4294967295] "" Vector__XXX
 SG_ SerialNumber40_1F88_28 m40 : 32|32@1+ (1,0) [0|4294967295] "" Vector__XXX
 SG_ SerialNumber39_1F88_27 m39 : 32|32@1+ (1,0) [0|4294967295] "" Vector__XXX
 SG_ SerialNumber38_1F88_26 m38 : 32|32@1+ (1,0) [0|4294967295] "" Vector__XXX
 SG_ SerialNumber37_1F88_25 m37 : 32|32@1+ (1,0) [0|4294967295] "" Vector__XXX
 SG_ SerialNumber36_1F88_24 m36 : 32|32@1+ (1,0) [0|4294967295] "" Vector__XXX
 SG_ SerialNumber35_1F88_23 m35 : 32|32@1+ (1,0) [0|4294967295] "" Vector__XXX
 SG_ SerialNumber34_1F88_22 m34 : 32|32@1+ (1,0) [0|4294967295] "" Vector__XXX
 SG_ SerialNumber33_1F88_21 m33 : 32|32@1+ (1,0) [0|4294967295] "" Vector__XXX
 SG_ SerialNumber32_1F88_20 m32 : 32|32@1+ (1,0) [0|4294967295] "" Vector__XXX
 SG_ SerialNumber31_1F88_1F m31 : 32|32@1+ (1,0) [0|4294967295] "" Vector__XXX
 SG_ SerialNumber30_1F88_1E m30 : 32|32@1+ (1,0) [0|4294967295] "" Vector__XXX
 SG_ SerialNumber29_1F88_1D m29 : 32|32@1+ (1,0) [0|4294967295] "" Vector__XXX
 SG_ SerialNumber28_1F88_1C m28 : 32|32@1+ (1,0) [0|4294967295] "" Vector__XXX
 SG_ SerialNumber27_1F88_1B m27 : 32|32@1+ (1,0) [0|4294967295] "" Vector__XXX
 SG_ SerialNumber26_1F88_1A m26 : 32|32@1+ (1,0) [0|4294967295] "" Vector__XXX
 SG_ SerialNumber25_1F88_19 m25 : 32|32@1+ (1,0) [0|4294967295] "" Vector__XXX
 SG_ SerialNumber24_1F88_18 m24 : 32|32@1+ (1,0) [0|4294967295] "" Vector__XXX
 SG_ SerialNumber23_1F88_17 m23 : 32|32@1+ (1,0) [0|4294967295] "" Vector__XXX
 SG_ SerialNumber22_1F88_16 m22 : 32|32@1+ (1,0) [0|4294967295] "" Vector__XXX
 SG_ SerialNumber21_1F88_15 m21 : 32|32@1+ (1,0) [0|4294967295] "" Vector__XXX
 SG_ SerialNumber20_1F88_14 m20 : 32|32@1+ (1,0) [0|4294967295] "" Vector__XXX
 SG_ SerialNumber19_1F88_13 m19 : 32|32@1+ (1,0) [0|4294967295] "" Vector__XXX
 SG_ SerialNumber18_1F88_12 m18 : 32|32@1+ (1,0) [0|4294967295] "" Vector__XXX
 SG_ SerialNumber17_1F88_11 m17 : 32|32@1+ (1,0) [0|4294967295] "" Vector__XXX
 SG_ SerialNumber16_1F88_10 m16 : 32|32@1+ (1,0) [0|4294967295] "" Vector__XXX
 SG_ SerialNumber15_1F88_0F m15 : 32|32@1+ (1,0) [0|4294967295] "" Vector__XXX
 SG_ SerialNumber14_1F88_0E m14 : 32|32@1+ (1,0) [0|4294967295] "" Vector__XXX
 SG_ SerialNumber13_1F88_0D m13 : 32|32@1+ (1,0) [0|4294967295] "" Vector__XXX
 SG_ SerialNumber12_1F88_0C m12 : 32|32@1+ (1,0) [0|4294967295] "" Vector__XXX
 SG_ SerialNumber11_1F88_0B m11 : 32|32@1+ (1,0) [0|4294967295] "" Vector__XXX
 SG_ SerialNumber10_1F88_0A m10 : 32|32@1+ (1,0) [0|4294967295] "" Vector__XXX
 SG_ SerialNumber9_1F88_09 m9 : 32|32@1+ (1,0) [0|4294967295] "" Vector__XXX
 SG_ SerialNumber8_1F88_08 m8 : 32|32@1+ (1,0) [0|4294967295] "" Vector__XXX
 SG_ SerialNumber7_1F88_07 m7 : 32|32@1+ (1,0) [0|4294967295] "" Vector__XXX
 SG_ SerialNumber6_1F88_06 m6 : 32|32@1+ (1,0) [0|4294967295] "" Vector__XXX
 SG_ SerialNumber5_1F88_05 m5 : 32|32@1+ (1,0) [0|4294967295] "" Vector__XXX
 SG_ SerialNumber4_1F88_04 m4 : 32|32@1+ (1,0) [0|4294967295] "" Vector__XXX
 SG_ SerialNumber3_1F88_03 m3 : 32|32@1+ (1,0) [0|4294967295] "" Vector__XXX
 SG_ SerialNumber2_1F88_02 m2 : 32|32@1+ (1,0) [0|4294967295] "" Vector__XXX
 SG_ SerialNumber1_1F88_01 m1 : 32|32@1+ (1,0) [0|4294967295] "" Vector__XXX
 SG_ NrOfObjects_1F88_00 m0 : 32|8@1+ (1,0) [0|255] "" Vector__XXX
 SG_ SubIndex_1F88 m8072M : 24|8@1+ (1,0) [0|127] "" Vector__XXX
 SG_ RevisionNumber127_1F87_7F m127 : 32|32@1+ (1,0) [0|4294967295] "" Vector__XXX
 SG_ RevisionNumber126_1F87_7E m126 : 32|32@1+ (1,0) [0|4294967295] "" Vector__XXX
 SG_ RevisionNumber125_1F87_7D m125 : 32|32@1+ (1,0) [0|4294967295] "" Vector__XXX
 SG_ RevisionNumber124_1F87_7C m124 : 32|32@1+ (1,0) [0|4294967295] "" Vector__XXX
 SG_ RevisionNumber123_1F87_7B m123 : 32|32@1+ (1,0) [0|4294967295] "" Vector__XXX
 SG_ RevisionNumber122_1F87_7A m122 : 32|32@1+ (1,0) [0|4294967295] "" Vector__XXX
 SG_ RevisionNumber121_1F87_79 m121 : 32|32@1+ (1,0) [0|4294967295] "" Vector__XXX
 SG_ RevisionNumber120_1F87_78 m120 : 32|32@1+ (1,0) [0|4294967295] "" Vector__XXX
 SG_ RevisionNumber119_1F87_77 m119 : 32|32@1+ (1,0) [0|4294967295] "" Vector__XXX
 SG_ RevisionNumber118_1F87_76 m118 : 32|32@1+ (1,0) [0|4294967295] "" Vector__XXX
 SG_ RevisionNumber117_1F87_75 m117 : 32|32@1+ (1,0) [0|4294967295] "" Vector__XXX
 SG_ RevisionNumber116_1F87_74 m116 : 32|32@1+ (1,0) [0|4294967295] "" Vector__XXX
 SG_ RevisionNumber115_1F87_73 m115 : 32|32@1+ (1,0) [0|4294967295] "" Vector__XXX
 SG_ RevisionNumber114_1F87_72 m114 : 32|32@1+ (1,0) [0|4294967295] "" Vector__XXX
 SG_ RevisionNumber113_1F87_71 m113 : 32|32@1+ (1,0) [0|4294967295] "" Vector__XXX
 SG_ RevisionNumber112_1F87_70 m112 : 32|32@1+ (1,0) [0|4294967295] "" Vector__XXX
 SG_ RevisionNumber111_1F87_6F m111 : 32|32@1+ (1,0) [0|4294967295] "" Vector__XXX
 SG_ RevisionNumber110_1F87_6E m110 : 32|32@1+ (1,0) [0|4294967295] "" Vector__XXX
 SG_ RevisionNumber109_1F87_6D m109 : 32|32@1+ (1,0) [0|4294967295] "" Vector__XXX
 SG_ RevisionNumber108_1F87_6C m108 : 32|32@1+ (1,0) [0|4294967295] "" Vector__XXX
 SG_ RevisionNumber107_1F87_6B m107 : 32|32@1+ (1,0) [0|4294967295] "" Vector__XXX
 SG_ RevisionNumber106_1F87_6A m106 : 32|32@1+ (1,0) [0|4294967295] "" Vector__XXX
 SG_ RevisionNumber105_1F87_69 m105 : 32|32@1+ (1,0) [0|4294967295] "" Vector__XXX
 SG_ RevisionNumber104_1F87_68 m104 : 32|32@1+ (1,0) [0|4294967295] "" Vector__XXX
 SG_ RevisionNumber103_1F87_67 m103 : 32|32@1+ (1,0) [0|4294967295] "" Vector__XXX
 SG_ RevisionNumber102_1F87_66 m102 : 32|32@1+ (1,0) [0|4294967295] "" Vector__XXX
 SG_ RevisionNumber101_1F87_65 m101 : 32|32@1+ (1,0) [0|4294967295] "" Vector__XXX
 SG_ RevisionNumber100_1F87_64 m100 : 32|32@1+ (1,0) [0|4294967295] "" Vector__XXX
 SG_ RevisionNumber99_1F87_63 m99 : 32|32@1+ (1,0) [0|4294967295] "" Vector__XXX
 SG_ RevisionNumber98_1F87_62 m98 : 32|32@1+ (1,0) [0|4294967295] "" Vector__XXX
 SG_ RevisionNumber97_1F87_61 m97 : 32|32@1+ (1,0) [0|4294967295] "" Vector__XXX
 SG_ RevisionNumber96_1F87_60 m96 : 32|32@1+ (1,0) [0|4294967295] "" Vector__XXX
 SG_ RevisionNumber95_1F87_5F m95 : 32|32@1+ (1,0) [0|4294967295] "" Vector__XXX
 SG_ RevisionNumber94_1F87_5E m94 : 32|32@1+ (1,0) [0|4294967295] "" Vector__XXX
 SG_ RevisionNumber93_1F87_5D m93 : 32|32@1+ (1,0) [0|4294967295] "" Vector__XXX
 SG_ RevisionNumber92_1F87_5C m92 : 32|32@1+ (1,0) [0|4294967295] "" Vector__XXX
 SG_ RevisionNumber91_1F87_5B m91 : 32|32@1+ (1,0) [0|4294967295] "" Vector__XXX
 SG_ RevisionNumber90_1F87_5A m90 : 32|32@1+ (1,0) [0|4294967295] "" Vector__XXX
 SG_ RevisionNumber89_1F87_59 m89 : 32|32@1+ (1,0) [0|4294967295] "" Vector__XXX
 SG_ RevisionNumber88_1F87_58 m88 : 32|32@1+ (1,0) [0|4294967295] "" Vector__XXX
 SG_ RevisionNumber87_1F87_57 m87 : 32|32@1+ (1,0) [0|4294967295] "" Vector__XXX
 SG_ RevisionNumber86_1F87_56 m86 : 32|32@1+ (1,0) [0|4294967295] "" Vector__XXX
 SG_ RevisionNumber85_1F87_55 m85 : 32|32@1+ (1,0) [0|4294967295] "" Vector__XXX
 SG_ RevisionNumber84_1F87_54 m84 : 32|32@1+ (1,0) [0|4294967295] "" Vector__XXX
 SG_ RevisionNumber83_1F87_53 m83 : 32|32@1+ (1,0) [0|4294967295] "" Vector__XXX
 SG_ RevisionNumber82_1F87_52 m82 : 32|32@1+ (1,0) [0|4294967295] "" Vector__XXX
 SG_ RevisionNumber81_1F87_51 m81 : 32|32@1+ (1,0) [0|4294967295] "" Vector__XXX
 SG_ RevisionNumber80_1F87_50 m80 : 32|32@1+ (1,0) [0|4294967295] "" Vector__XXX
 SG_ RevisionNumber79_1F87_4F m79 : 32|32@1+ (1,0) [0|4294967295] "" Vector__XXX
 SG_ RevisionNumber78_1F87_4E m78 : 32|32@1+ (1,0) [0|4294967295] "" Vector__XXX
 SG_ RevisionNumber77_1F87_4D m77 : 32|32@1+ (1,0) [0|4294967295] "" Vector__XXX
 SG_ RevisionNumber76_1F87_4C m76 : 32|32@1+ (1,0) [0|4294967295] "" Vector__XXX
 SG_ RevisionNumber75_1F87_4B m75 : 32|32@1+ (1,0) [0|4294967295] "" Vector__XXX
 SG_ RevisionNumber74_1F87_4A m74 : 32|32@1+ (1,0) [0|4294967295] "" Vector__XXX
 SG_ RevisionNumber73_1F87_49 m73 : 32|32@1+ (1,0) [0|4294967295] "" Vector__XXX
 SG_ RevisionNumber72_1F87_48 m72 : 32|32@1+ (1,0) [0|4294967295] "" Vector__XXX
 SG_ RevisionNumber71_1F87_47 m71 : 32|32@1+ (1,0) [0|4294967295] "" Vector__XXX
 SG_ RevisionNumber70_1F87_46 m70 : 32|32@1+ (1,0) [0|4294967295] "" Vector__XXX
 SG_ RevisionNumber69_1F87_45 m69 : 32|32@1+ (1,0) [0|4294967295] "" Vector__XXX
 SG_ RevisionNumber68_1F87_44 m68 : 32|32@1+ (1,0) [0|4294967295] "" Vector__XXX
 SG_ RevisionNumber67_1F87_43 m67 : 32|32@1+ (1,0) [0|4294967295] "" Vector__XXX
 SG_ RevisionNumber66_1F87_42 m66 : 32|32@1+ (1,0) [0|4294967295] "" Vector__XXX
 SG_ RevisionNumber65_1F87_41 m65 : 32|32@1+ (1,0) [0|4294967295] "" Vector__XXX
 SG_ RevisionNumber64_1F87_40 m64 : 32|32@1+ (1,0) [0|4294967295] "" Vector__XXX
 SG_ RevisionNumber63_1F87_3F m63 : 32|32@1+ (1,0) [0|4294967295] "" Vector__XXX
 SG_ RevisionNumber62_1F87_3E m62 : 32|32@1+ (1,0) [0|4294967295] "" Vector__XXX
 SG_ RevisionNumber61_1F87_3D m61 : 32|32@1+ (1,0) [0|4294967295] "" Vector__XXX
 SG_ RevisionNumber60_1F87_3C m60 : 32|32@1+ (1,0) [0|4294967295] "" Vector__XXX
 SG_ RevisionNumber59_1F87_3B m59 : 32|32@1+ (1,0) [0|4294967295] "" Vector__XXX
 SG_ RevisionNumber58_1F87_3A m58 : 32|32@1+ (1,0) [0|4294967295] "" Vector__XXX
 SG_ RevisionNumber57_1F87_39 m57 : 32|32@1+ (1,0) [0|4294967295] "" Vector__XXX
 SG_ RevisionNumber56_1F87_38 m56 : 32|32@1+ (1,0) [0|4294967295] "" Vector__XXX
 SG_ RevisionNumber55_1F87_37 m55 : 32|32@1+ (1,0) [0|4294967295] "" Vector__XXX
 SG_ RevisionNumber54_1F87_36 m54 : 32|32@1+ (1,0) [0|4294967295] "" Vector__XXX
 SG_ RevisionNumber53_1F87_35 m53 : 32|32@1+ (1,0) [0|4294967295] "" Vector__XXX
 SG_ RevisionNumber52_1F87_34 m52 : 32|32@1+ (1,0) [0|4294967295] "" Vector__XXX
 SG_ RevisionNumber51_1F87_33 m51 : 32|32@1+ (1,0) [0|4294967295] "" Vector__XXX
 SG_ RevisionNumber50_1F87_32 m50 : 32|32@1+ (1,0) [0|4294967295] "" Vector__XXX
 SG_ RevisionNumber49_1F87_31 m49 : 32|32@1+ (1,0) [0|4294967295] "" Vector__XXX
 SG_ RevisionNumber48_1F87_30 m48 : 32|32@1+ (1,0) [0|4294967295] "" Vector__XXX
 SG_ RevisionNumber47_1F87_2F m47 : 32|32@1+ (1,0) [0|4294967295] "" Vector__XXX
 SG_ RevisionNumber46_1F87_2E m46 : 32|32@1+ (1,0) [0|4294967295] "" Vector__XXX
 SG_ RevisionNumber45_1F87_2D m45 : 32|32@1+ (1,0) [0|4294967295] "" Vector__XXX
 SG_ RevisionNumber44_1F87_2C m44 : 32|32@1+ (1,0) [0|4294967295] "" Vector__XXX
 SG_ RevisionNumber43_1F87_2B m43 : 32|32@1+ (1,0) [0|4294967295] "" Vector__XXX
 SG_ RevisionNumber42_1F87_2A m42 : 32|32@1+ (1,0) [0|4294967295] "" Vector__XXX
 SG_ RevisionNumber41_1F87_29 m41 : 32|32@1+ (1,0) [0|4294967295] "" Vector__XXX
 SG_ RevisionNumber40_1F87_28 m40 : 32|32@1+ (1,0) [0|4294967295] "" Vector__XXX
 SG_ RevisionNumber39_1F87_27 m39 : 32|32@1+ (1,0) [0|4294967295] "" Vector__XXX
 SG_ RevisionNumber38_1F87_26 m38 : 32|32@1+ (1,0) [0|4294967295] "" Vector__XXX
 SG_ RevisionNumber37_1F87_25 m37 : 32|32@1+ (1,0) [0|4294967295] "" Vector__XXX
 SG_ RevisionNumber36_1F87_24 m36 : 32|32@1+ (1,0) [0|4294967295] "" Vector__XXX
 SG_ RevisionNumber35_1F87_23 m35 : 32|32@1+ (1,0) [0|4294967295] "" Vector__XXX
 SG_ RevisionNumber34_1F87_22 m34 : 32|32@1+ (1,0) [0|4294967295] "" Vector__XXX
 SG_ RevisionNumber33_1F87_21 m33 : 32|32@1+ (1,0) [0|4294967295] "" Vector__XXX
 SG_ RevisionNumber32_1F87_20 m32 : 32|32@1+ (1,0) [0|4294967295] "" Vector__XXX
 SG_ RevisionNumber31_1F87_1F m31 : 32|32@1+ (1,0) [0|4294967295] "" Vector__XXX
 SG_ RevisionNumber30_1F87_1E m30 : 32|32@1+ (1,0) [0|4294967295] "" Vector__XXX
 SG_ RevisionNumber29_1F87_1D m29 : 32|32@1+ (1,0) [0|4294967295] "" Vector__XXX
 SG_ RevisionNumber28_1F87_1C m28 : 32|32@1+ (1,0) [0|4294967295] "" Vector__XXX
 SG_ RevisionNumber27_1F87_1B m27 : 32|32@1+ (1,0) [0|4294967295] "" Vector__XXX
 SG_ RevisionNumber26_1F87_1A m26 : 32|32@1+ (1,0) [0|4294967295] "" Vector__XXX
 SG_ RevisionNumber25_1F87_19 m25 : 32|32@1+ (1,0) [0|4294967295] "" Vector__XXX
 SG_ RevisionNumber24_1F87_18 m24 : 32|32@1+ (1,0) [0|4294967295] "" Vector__XXX
 SG_ RevisionNumber23_1F87_17 m23 : 32|32@1+ (1,0) [0|4294967295] "" Vector__XXX
 SG_ RevisionNumber22_1F87_16 m22 : 32|32@1+ (1,0) [0|4294967295] "" Vector__XXX
 SG_ RevisionNumber21_1F87_15 m21 : 32|32@1+ (1,0) [0|4294967295] "" Vector__XXX
 SG_ RevisionNumber20_1F87_14 m20 : 32|32@1+ (1,0) [0|4294967295] "" Vector__XXX
 SG_ RevisionNumber19_1F87_13 m19 : 32|32@1+ (1,0) [0|4294967295] "" Vector__XXX
 SG_ RevisionNumber18_1F87_12 m18 : 32|32@1+ (1,0) [0|4294967295] "" Vector__XXX
 SG_ RevisionNumber17_1F87_11 m17 : 32|32@1+ (1,0) [0|4294967295] "" Vector__XXX
 SG_ RevisionNumber16_1F87_10 m16 : 32|32@1+ (1,0) [0|4294967295] "" Vector__XXX
 SG_ RevisionNumber15_1F87_0F m15 : 32|32@1+ (1,0) [0|4294967295] "" Vector__XXX
 SG_ RevisionNumber14_1F87_0E m14 : 32|32@1+ (1,0) [0|4294967295] "" Vector__XXX
 SG_ RevisionNumber13_1F87_0D m13 : 32|32@1+ (1,0) [0|4294967295] "" Vector__XXX
 SG_ RevisionNumber12_1F87_0C m12 : 32|32@1+ (1,0) [0|4294967295] "" Vector__XXX
 SG_ RevisionNumber11_1F87_0B m11 : 32|32@1+ (1,0) [0|4294967295] "" Vector__XXX
 SG_ RevisionNumber10_1F87_0A m10 : 32|32@1+ (1,0) [0|4294967295] "" Vector__XXX
 SG_ RevisionNumber9_1F87_09 m9 : 32|32@1+ (1,0) [0|4294967295] "" Vector__XXX
 SG_ RevisionNumber8_1F87_08 m8 : 32|32@1+ (1,0) [0|4294967295] "" Vector__XXX
 SG_ RevisionNumber7_1F87_07 m7 : 32|32@1+ (1,0) [0|4294967295] "" Vector__XXX
 SG_ RevisionNumber6_1F87_06 m6 : 32|32@1+ (1,0) [0|4294967295] "" Vector__XXX
 SG_ RevisionNumber5_1F87_05 m5 : 32|32@1+ (1,0) [0|4294967295] "" Vector__XXX
 SG_ RevisionNumber4_1F87_04 m4 : 32|32@1+ (1,0) [0|4294967295] "" Vector__XXX
 SG_ RevisionNumber3_1F87_03 m3 : 32|32@1+ (1,0) [0|4294967295] "" Vector__XXX
 SG_ RevisionNumber2_1F87_02 m2 : 32|32@1+ (1,0) [0|4294967295] "" Vector__XXX
 SG_ RevisionNumber1_1F87_01 m1 : 32|32@1+ (1,0) [0|4294967295] "" Vector__XXX
 SG_ NrOfObjects_1F87_00 m0 : 32|8@1+ (1,0) [0|255] "" Vector__XXX
 SG_ SubIndex_1F87 m8071M : 24|8@1+ (1,0) [0|127] "" Vector__XXX
 SG_ ProductCode127_1F86_7F m127 : 32|32@1+ (1,0) [0|4294967295] "" Vector__XXX
 SG_ ProductCode126_1F86_7E m126 : 32|32@1+ (1,0) [0|4294967295] "" Vector__XXX
 SG_ ProductCode125_1F86_7D m125 : 32|32@1+ (1,0) [0|4294967295] "" Vector__XXX
 SG_ ProductCode124_1F86_7C m124 : 32|32@1+ (1,0) [0|4294967295] "" Vector__XXX
 SG_ ProductCode123_1F86_7B m123 : 32|32@1+ (1,0) [0|4294967295] "" Vector__XXX
 SG_ ProductCode122_1F86_7A m122 : 32|32@1+ (1,0) [0|4294967295] "" Vector__XXX
 SG_ ProductCode121_1F86_79 m121 : 32|32@1+ (1,0) [0|4294967295] "" Vector__XXX
 SG_ ProductCode120_1F86_78 m120 : 32|32@1+ (1,0) [0|4294967295] "" Vector__XXX
 SG_ ProductCode119_1F86_77 m119 : 32|32@1+ (1,0) [0|4294967295] "" Vector__XXX
 SG_ ProductCode118_1F86_76 m118 : 32|32@1+ (1,0) [0|4294967295] "" Vector__XXX
 SG_ ProductCode117_1F86_75 m117 : 32|32@1+ (1,0) [0|4294967295] "" Vector__XXX
 SG_ ProductCode116_1F86_74 m116 : 32|32@1+ (1,0) [0|4294967295] "" Vector__XXX
 SG_ ProductCode115_1F86_73 m115 : 32|32@1+ (1,0) [0|4294967295] "" Vector__XXX
 SG_ ProductCode114_1F86_72 m114 : 32|32@1+ (1,0) [0|4294967295] "" Vector__XXX
 SG_ ProductCode113_1F86_71 m113 : 32|32@1+ (1,0) [0|4294967295] "" Vector__XXX
 SG_ ProductCode112_1F86_70 m112 : 32|32@1+ (1,0) [0|4294967295] "" Vector__XXX
 SG_ ProductCode111_1F86_6F m111 : 32|32@1+ (1,0) [0|4294967295] "" Vector__XXX
 SG_ ProductCode110_1F86_6E m110 : 32|32@1+ (1,0) [0|4294967295] "" Vector__XXX
 SG_ ProductCode109_1F86_6D m109 : 32|32@1+ (1,0) [0|4294967295] "" Vector__XXX
 SG_ ProductCode108_1F86_6C m108 : 32|32@1+ (1,0) [0|4294967295] "" Vector__XXX
 SG_ ProductCode107_1F86_6B m107 : 32|32@1+ (1,0) [0|4294967295] "" Vector__XXX
 SG_ ProductCode106_1F86_6A m106 : 32|32@1+ (1,0) [0|4294967295] "" Vector__XXX
 SG_ ProductCode105_1F86_69 m105 : 32|32@1+ (1,0) [0|4294967295] "" Vector__XXX
 SG_ ProductCode104_1F86_68 m104 : 32|32@1+ (1,0) [0|4294967295] "" Vector__XXX
 SG_ ProductCode103_1F86_67 m103 : 32|32@1+ (1,0) [0|4294967295] "" Vector__XXX
 SG_ ProductCode102_1F86_66 m102 : 32|32@1+ (1,0) [0|4294967295] "" Vector__XXX
 SG_ ProductCode101_1F86_65 m101 : 32|32@1+ (1,0) [0|4294967295] "" Vector__XXX
 SG_ ProductCode100_1F86_64 m100 : 32|32@1+ (1,0) [0|4294967295] "" Vector__XXX
 SG_ ProductCode99_1F86_63 m99 : 32|32@1+ (1,0) [0|4294967295] "" Vector__XXX
 SG_ ProductCode98_1F86_62 m98 : 32|32@1+ (1,0) [0|4294967295] "" Vector__XXX
 SG_ ProductCode97_1F86_61 m97 : 32|32@1+ (1,0) [0|4294967295] "" Vector__XXX
 SG_ ProductCode96_1F86_60 m96 : 32|32@1+ (1,0) [0|4294967295] "" Vector__XXX
 SG_ ProductCode95_1F86_5F m95 : 32|32@1+ (1,0) [0|4294967295] "" Vector__XXX
 SG_ ProductCode94_1F86_5E m94 : 32|32@1+ (1,0) [0|4294967295] "" Vector__XXX
 SG_ ProductCode93_1F86_5D m93 : 32|32@1+ (1,0) [0|4294967295] "" Vector__XXX
 SG_ ProductCode92_1F86_5C m92 : 32|32@1+ (1,0) [0|4294967295] "" Vector__XXX
 SG_ ProductCode91_1F86_5B m91 : 32|32@1+ (1,0) [0|4294967295] "" Vector__XXX
 SG_ ProductCode90_1F86_5A m90 : 32|32@1+ (1,0) [0|4294967295] "" Vector__XXX
 SG_ ProductCode89_1F86_59 m89 : 32|32@1+ (1,0) [0|4294967295] "" Vector__XXX
 SG_ ProductCode88_1F86_58 m88 : 32|32@1+ (1,0) [0|4294967295] "" Vector__XXX
 SG_ ProductCode87_1F86_57 m87 : 32|32@1+ (1,0) [0|4294967295] "" Vector__XXX
 SG_ ProductCode86_1F86_56 m86 : 32|32@1+ (1,0) [0|4294967295] "" Vector__XXX
 SG_ ProductCode85_1F86_55 m85 : 32|32@1+ (1,0) [0|4294967295] "" Vector__XXX
 SG_ ProductCode84_1F86_54 m84 : 32|32@1+ (1,0) [0|4294967295] "" Vector__XXX
 SG_ ProductCode83_1F86_53 m83 : 32|32@1+ (1,0) [0|4294967295] "" Vector__XXX
 SG_ ProductCode82_1F86_52 m82 : 32|32@1+ (1,0) [0|4294967295] "" Vector__XXX
 SG_ ProductCode81_1F86_51 m81 : 32|32@1+ (1,0) [0|4294967295] "" Vector__XXX
 SG_ ProductCode80_1F86_50 m80 : 32|32@1+ (1,0) [0|4294967295] "" Vector__XXX
 SG_ ProductCode79_1F86_4F m79 : 32|32@1+ (1,0) [0|4294967295] "" Vector__XXX
 SG_ ProductCode78_1F86_4E m78 : 32|32@1+ (1,0) [0|4294967295] "" Vector__XXX
 SG_ ProductCode77_1F86_4D m77 : 32|32@1+ (1,0) [0|4294967295] "" Vector__XXX
 SG_ ProductCode76_1F86_4C m76 : 32|32@1+ (1,0) [0|4294967295] "" Vector__XXX
 SG_ ProductCode75_1F86_4B m75 : 32|32@1+ (1,0) [0|4294967295] "" Vector__XXX
 SG_ ProductCode74_1F86_4A m74 : 32|32@1+ (1,0) [0|4294967295] "" Vector__XXX
 SG_ ProductCode73_1F86_49 m73 : 32|32@1+ (1,0) [0|4294967295] "" Vector__XXX
 SG_ ProductCode72_1F86_48 m72 : 32|32@1+ (1,0) [0|4294967295] "" Vector__XXX
 SG_ ProductCode71_1F86_47 m71 : 32|32@1+ (1,0) [0|4294967295] "" Vector__XXX
 SG_ ProductCode70_1F86_46 m70 : 32|32@1+ (1,0) [0|4294967295] "" Vector__XXX
 SG_ ProductCode69_1F86_45 m69 : 32|32@1+ (1,0) [0|4294967295] "" Vector__XXX
 SG_ ProductCode68_1F86_44 m68 : 32|32@1+ (1,0) [0|4294967295] "" Vector__XXX
 SG_ ProductCode67_1F86_43 m67 : 32|32@1+ (1,0) [0|4294967295] "" Vector__XXX
 SG_ ProductCode66_1F86_42 m66 : 32|32@1+ (1,0) [0|4294967295] "" Vector__XXX
 SG_ ProductCode65_1F86_41 m65 : 32|32@1+ (1,0) [0|4294967295] "" Vector__XXX
 SG_ ProductCode64_1F86_40 m64 : 32|32@1+ (1,0) [0|4294967295] "" Vector__XXX
 SG_ ProductCode63_1F86_3F m63 : 32|32@1+ (1,0) [0|4294967295] "" Vector__XXX
 SG_ ProductCode62_1F86_3E m62 : 32|32@1+ (1,0) [0|4294967295] "" Vector__XXX
 SG_ ProductCode61_1F86_3D m61 : 32|32@1+ (1,0) [0|4294967295] "" Vector__XXX
 SG_ ProductCode60_1F86_3C m60 : 32|32@1+ (1,0) [0|4294967295] "" Vector__XXX
 SG_ ProductCode59_1F86_3B m59 : 32|32@1+ (1,0) [0|4294967295] "" Vector__XXX
 SG_ ProductCode58_1F86_3A m58 : 32|32@1+ (1,0) [0|4294967295] "" Vector__XXX
 SG_ ProductCode57_1F86_39 m57 : 32|32@1+ (1,0) [0|4294967295] "" Vector__XXX
 SG_ ProductCode56_1F86_38 m56 : 32|32@1+ (1,0) [0|4294967295] "" Vector__XXX
 SG_ ProductCode55_1F86_37 m55 : 32|32@1+ (1,0) [0|4294967295] "" Vector__XXX
 SG_ ProductCode54_1F86_36 m54 : 32|32@1+ (1,0) [0|4294967295] "" Vector__XXX
 SG_ ProductCode53_1F86_35 m53 : 32|32@1+ (1,0) [0|4294967295] "" Vector__XXX
 SG_ ProductCode52_1F86_34 m52 : 32|32@1+ (1,0) [0|4294967295] "" Vector__XXX
 SG_ ProductCode51_1F86_33 m51 : 32|32@1+ (1,0) [0|4294967295] "" Vector__XXX
 SG_ ProductCode50_1F86_32 m50 : 32|32@1+ (1,0) [0|4294967295] "" Vector__XXX
 SG_ ProductCode49_1F86_31 m49 : 32|32@1+ (1,0) [0|4294967295] "" Vector__XXX
 SG_ ProductCode48_1F86_30 m48 : 32|32@1+ (1,0) [0|4294967295] "" Vector__XXX
 SG_ SubIndex_1F86 m8070M : 24|8@1+ (1,0) [0|127] "" Vector__XXX
 SG_ Index m1M : 8|16@1+ (1,0) [4096|42176] "" Vector__XXX
 SG_ SCS M : 5|3@1+ (1,0) [0|6] "" Vector__XXX

BA_DEF_ BU_  "CO_DCF" STRING ;
BA_DEF_ BU_  "CO_ID" INT 0 127;
BA_DEF_ BU_  "CO_NVSEGMENT0" STRING ;
BA_DEF_ BU_  "CO_NVSEGMENT1" STRING ;
BA_DEF_ BU_  "CO_NVSEGMENT2" STRING ;
BA_DEF_ BU_  "CO_NVSEGMENT3" STRING ;
BA_DEF_ BU_  "CO_NVSEGMENT4" STRING ;
BA_DEF_ BU_  "CO_NVSEGMENT5" STRING ;
BA_DEF_ BU_  "CO_NVSEGMENT6" STRING ;
BA_DEF_ BU_  "CO_NVSEGMENT7" STRING ;
BA_DEF_ BU_  "CO_NVSEGMENT8" STRING ;
BA_DEF_ BU_  "CO_NVSEGMENT9" STRING ;
BA_DEF_ BU_  "CO_NVSEGMENT10" STRING ;
BA_DEF_ BU_  "CO_NVSEGMENT11" STRING ;
BA_DEF_ BU_  "CO_NVSEGMENT12" STRING ;
BA_DEF_ BU_  "CO_NVSEGMENT13" STRING ;
BA_DEF_ BU_  "CO_NVSEGMENT14" STRING ;
BA_DEF_ BU_  "CO_NVSEGMENT15" STRING ;
BA_DEF_ BU_  "CO_NVSEGMENT16" STRING ;
BA_DEF_ BU_  "CO_NVSEGMENT17" STRING ;
BA_DEF_ BU_  "CO_NVSEGMENT18" STRING ;
BA_DEF_ BU_  "CO_NVSEGMENT19" STRING ;
BA_DEF_ BU_  "CO_NVSEGMENT20" STRING ;
BA_DEF_ BU_  "CO_NVSEGMENT21" STRING ;
BA_DEF_ BU_  "CO_NVSEGMENT22" STRING ;
BA_DEF_ BU_  "CO_NVSEGMENT23" STRING ;
BA_DEF_ BU_  "CO_NVSEGMENT24" STRING ;
BA_DEF_ BU_  "CO_NVSEGMENT25" STRING ;
BA_DEF_ BU_  "CO_NVSEGMENT26" STRING ;
BA_DEF_ BU_  "CO_NVSEGMENT27" STRING ;
BA_DEF_ BU_  "CO_NVSEGMENT28" STRING ;
BA_DEF_ BU_  "CO_NVSEGMENT29" STRING ;
BA_DEF_ BU_  "CO_NVSEGMENT30" STRING ;
BA_DEF_ BU_  "CO_NVSEGMENT31" STRING ;
BA_DEF_ BU_  "CO_NVSEGMENT32" STRING ;
BA_DEF_ BU_  "CO_NVSEGMENT33" STRING ;
BA_DEF_ BU_  "CO_NVSEGMENT34" STRING ;
BA_DEF_ BU_  "CO_NVSEGMENT35" STRING ;
BA_DEF_ BU_  "CO_NVSEGMENT36" STRING ;
BA_DEF_ BU_  "CO_NVSEGMENT37" STRING ;
BA_DEF_ BU_  "CO_NVSEGMENT38" STRING ;
BA_DEF_ BU_  "CO_NVSEGMENT39" STRING ;
BA_DEF_ BU_  "CO_NVSEGMENT40" STRING ;
BA_DEF_ BU_  "CO_NVSEGMENT41" STRING ;
BA_DEF_ BU_  "CO_NVSEGMENT42" STRING ;
BA_DEF_ BU_  "CO_NVSEGMENT43" STRING ;
BA_DEF_ BU_  "CO_NVSEGMENT44" STRING ;
BA_DEF_ BU_  "CO_NVSEGMENT45" STRING ;
BA_DEF_  "OptionLoadDCF" INT 0 1;
BA_DEF_ SG_  "GenSigStartValue" INT 0 0;
BA_DEF_ BO_  "CO_MsgCategory" INT 0 0;
BA_DEF_  "CO_MsgColourSupported" INT 0 1;
BA_DEF_  "GeneratedBy" STRING ;
BA_DEF_  "CANopenApplProfile" INT 0 0;
BA_DEF_  "ProtocolType" STRING ;
BA_DEF_  "AUTOGENERATION" INT 0 1;
BA_DEF_ SG_  "SystemSignalLongSymbol" STRING ;
BA_DEF_DEF_  "CO_DCF" "";
BA_DEF_DEF_  "CO_ID" 0;
BA_DEF_DEF_  "CO_NVSEGMENT0" "";
BA_DEF_DEF_  "CO_NVSEGMENT1" "";
BA_DEF_DEF_  "CO_NVSEGMENT2" "";
BA_DEF_DEF_  "CO_NVSEGMENT3" "";
BA_DEF_DEF_  "CO_NVSEGMENT4" "";
BA_DEF_DEF_  "CO_NVSEGMENT5" "";
BA_DEF_DEF_  "CO_NVSEGMENT6" "";
BA_DEF_DEF_  "CO_NVSEGMENT7" "";
BA_DEF_DEF_  "CO_NVSEGMENT8" "";
BA_DEF_DEF_  "CO_NVSEGMENT9" "";
BA_DEF_DEF_  "CO_NVSEGMENT10" "";
BA_DEF_DEF_  "CO_NVSEGMENT11" "";
BA_DEF_DEF_  "CO_NVSEGMENT12" "";
BA_DEF_DEF_  "CO_NVSEGMENT13" "";
BA_DEF_DEF_  "CO_NVSEGMENT14" "";
BA_DEF_DEF_  "CO_NVSEGMENT15" "";
BA_DEF_DEF_  "CO_NVSEGMENT16" "";
BA_DEF_DEF_  "CO_NVSEGMENT17" "";
BA_DEF_DEF_  "CO_NVSEGMENT18" "";
BA_DEF_DEF_  "CO_NVSEGMENT19" "";
BA_DEF_DEF_  "CO_NVSEGMENT20" "";
BA_DEF_DEF_  "CO_NVSEGMENT21" "";
BA_DEF_DEF_  "CO_NVSEGMENT22" "";
BA_DEF_DEF_  "CO_NVSEGMENT23" "";
BA_DEF_DEF_  "CO_NVSEGMENT24" "";
BA_DEF_DEF_  "CO_NVSEGMENT25" "";
BA_DEF_DEF_  "CO_NVSEGMENT26" "";
BA_DEF_DEF_  "CO_NVSEGMENT27" "";
BA_DEF_DEF_  "CO_NVSEGMENT28" "";
BA_DEF_DEF_  "CO_NVSEGMENT29" "";
BA_DEF_DEF_  "CO_NVSEGMENT30" "";
BA_DEF_DEF_  "CO_NVSEGMENT31" "";
BA_DEF_DEF_  "CO_NVSEGMENT32" "";
BA_DEF_DEF_  "CO_NVSEGMENT33" "";
BA_DEF_DEF_  "CO_NVSEGMENT34" "";
BA_DEF_DEF_  "CO_NVSEGMENT35" "";
BA_DEF_DEF_  "CO_NVSEGMENT36" "";
BA_DEF_DEF_  "CO_NVSEGMENT37" "";
BA_DEF_DEF_  "CO_NVSEGMENT38" "";
BA_DEF_DEF_  "CO_NVSEGMENT39" "";
BA_DEF_DEF_  "CO_NVSEGMENT40" "";
BA_DEF_DEF_  "CO_NVSEGMENT41" "";
BA_DEF_DEF_  "CO_NVSEGMENT42" "";
BA_DEF_DEF_  "CO_NVSEGMENT43" "";
BA_DEF_DEF_  "CO_NVSEGMENT44" "";
BA_DEF_DEF_  "CO_NVSEGMENT45" "";
BA_DEF_DEF_  "OptionLoadDCF" 0;
BA_DEF_DEF_  "GenSigStartValue" 0;
BA_DEF_DEF_  "CO_MsgCategory" 0;
BA_DEF_DEF_  "CO_MsgColourSupported" 1;
BA_DEF_DEF_  "GeneratedBy" "";
BA_DEF_DEF_  "CANopenApplProfile" 301;
BA_DEF_DEF_  "ProtocolType" "CANopen";
BA_DEF_DEF_  "AUTOGENERATION" 0;
BA_DEF_DEF_  "SystemSignalLongSymbol" "";
BA_ "OptionLoadDCF" 1;
BA_ "GeneratedBy" "CANoe 12.0.58";
BA_ "AUTOGENERATION" 1;
BA_ "CO_DCF" BU_ I_O_Device_2 "I_O_Device_2_ID11.dcf";
BA_ "CO_ID" BU_ I_O_Device_2 11;
BA_ "CO_NVSEGMENT19" BU_ Master "a440,a447,1,27,0,0";
BA_ "CO_NVSEGMENT18" BU_ Master "a400,a407,1,21,0,0";
BA_ "CO_NVSEGMENT17" BU_ Master "a240,a247,1,8,0,0";
BA_ "CO_NVSEGMENT16" BU_ Master "a200,a207,1,7,0,0";
BA_ "CO_NVSEGMENT15" BU_ Master "a1c0,a1c7,1,4,0,0";
BA_ "CO_NVSEGMENT14" BU_ Master "a100,a107,1,6,0,0";
BA_ "CO_NVSEGMENT13" BU_ Master "a0c0,a0c7,1,3,0,0";
BA_ "CO_NVSEGMENT12" BU_ Master "a040,a047,1,5,0,0";
BA_ "CO_NVSEGMENT11" BU_ Master "a000,a007,1,2,0,0";
BA_ "CO_NVSEGMENT10" BU_ Master "a080,a087,1,1,0,8";
BA_ "CO_NVSEGMENT9" BU_ Master "a8c0,a8c7,0,27,0,0";
BA_ "CO_NVSEGMENT8" BU_ Master "a880,a887,0,21,0,0";
BA_ "CO_NVSEGMENT7" BU_ Master "a6c0,a6c7,0,8,0,0";
BA_ "CO_NVSEGMENT6" BU_ Master "a680,a687,0,7,0,0";
BA_ "CO_NVSEGMENT5" BU_ Master "a640,a647,0,4,0,0";
BA_ "CO_NVSEGMENT4" BU_ Master "a580,a587,0,6,0,0";
BA_ "CO_NVSEGMENT3" BU_ Master "a540,a547,0,3,0,0";
BA_ "CO_NVSEGMENT2" BU_ Master "a4c0,a4c7,0,5,0,0";
BA_ "CO_NVSEGMENT1" BU_ Master "a480,a487,0,2,0,0";
BA_ "CO_NVSEGMENT0" BU_ Master "a500,a507,0,1,0,8";
BA_ "CO_DCF" BU_ Master "Master_ID1.dcf";
BA_ "CO_ID" BU_ Master 1;
BA_ "CO_DCF" BU_ I_O_Device_1 "I_O_Device_1_ID10.dcf";
BA_ "CO_ID" BU_ I_O_Device_1 10;
BA_ "CO_MsgCategory" BO_ 1803 505;
BA_ "CO_MsgCategory" BO_ 1419 410;
BA_ "CO_MsgCategory" BO_ 1547 405;
BA_ "CO_MsgCategory" BO_ 139 205;
BA_ "CO_MsgCategory" BO_ 1793 505;
BA_ "CO_MsgCategory" BO_ 1409 410;
BA_ "GenSigStartValue" SG_ 1419 NrOfObjects_6320_00 16;
BA_ "GenSigStartValue" SG_ 1419 NrOfObjects_6300_00 16;
BA_ "GenSigStartValue" SG_ 1419 NrOfObjects_6220_00 64;
BA_ "GenSigStartValue" SG_ 1419 NrOfObjects_6200_00 16;
BA_ "GenSigStartValue" SG_ 1419 NrOfObjects_6120_00 16;
BA_ "GenSigStartValue" SG_ 1419 NrOfObjects_6100_00 16;
BA_ "GenSigStartValue" SG_ 1419 NrOfObjects_6020_00 64;
BA_ "GenSigStartValue" SG_ 1419 NrOfObjects_6000_00 16;
BA_ "GenSigStartValue" SG_ 1419 NrOfObjects_2300_00 4;
BA_ "GenSigStartValue" SG_ 1419 NrOfObjects_2200_00 4;
BA_ "GenSigStartValue" SG_ 1419 TransmissionType_1803_02 255;
BA_ "GenSigStartValue" SG_ 1419 COB_ID_1803_01 2147484811;
BA_ "GenSigStartValue" SG_ 1419 NrOfEntries_1803_00 5;
BA_ "GenSigStartValue" SG_ 1419 TransmissionType_1802_02 255;
BA_ "GenSigStartValue" SG_ 1419 COB_ID_1802_01 2147484555;
BA_ "GenSigStartValue" SG_ 1419 NrOfEntries_1802_00 5;
BA_ "GenSigStartValue" SG_ 1419 TransmissionType_1801_02 255;
BA_ "GenSigStartValue" SG_ 1419 COB_ID_1801_01 2147484299;
BA_ "GenSigStartValue" SG_ 1419 NrOfEntries_1801_00 5;
BA_ "GenSigStartValue" SG_ 1419 TransmissionType_1800_02 255;
BA_ "GenSigStartValue" SG_ 1419 COB_ID_1800_01 2147484043;
BA_ "GenSigStartValue" SG_ 1419 NrOfEntries_1800_00 5;
BA_ "GenSigStartValue" SG_ 1419 mappedObj2_1600_02 1644167688;
BA_ "GenSigStartValue" SG_ 1419 mappedObj1_1600_01 1644167432;
BA_ "GenSigStartValue" SG_ 1419 NrOfMappedObjects_1600_00 2;
BA_ "GenSigStartValue" SG_ 1419 TransmissionType_1403_02 255;
BA_ "GenSigStartValue" SG_ 1419 COB_ID_1403_01 2147484939;
BA_ "GenSigStartValue" SG_ 1419 NrOfEntries_1403_00 2;
BA_ "GenSigStartValue" SG_ 1419 TransmissionType_1402_02 255;
BA_ "GenSigStartValue" SG_ 1419 COB_ID_1402_01 2147484683;
BA_ "GenSigStartValue" SG_ 1419 NrOfEntries_1402_00 2;
BA_ "GenSigStartValue" SG_ 1419 TransmissionType_1401_02 255;
BA_ "GenSigStartValue" SG_ 1419 COB_ID_1401_01 2147484427;
BA_ "GenSigStartValue" SG_ 1419 NrOfEntries_1401_00 2;
BA_ "GenSigStartValue" SG_ 1419 TransmissionType_1400_02 255;
BA_ "GenSigStartValue" SG_ 1419 COB_ID_1400_01 394;
BA_ "GenSigStartValue" SG_ 1419 NrOfEntries_1400_00 2;
BA_ "GenSigStartValue" SG_ 1419 Revision_number_1018_03 256;
BA_ "GenSigStartValue" SG_ 1419 Product_Code_1018_02 305419896;
BA_ "GenSigStartValue" SG_ 1419 Vendor_Id_1018_01 5;
BA_ "GenSigStartValue" SG_ 1419 number_of_entries_1018_00 4;
BA_ "SystemSignalLongSymbol" SG_ 1419 Consumer_Heartbeat_Time16_1016_1 "Consumer_Heartbeat_Time16_1016_10";
BA_ "SystemSignalLongSymbol" SG_ 1419 Consumer_Heartbeat_Time15_1016_0 "Consumer_Heartbeat_Time15_1016_0F";
BA_ "SystemSignalLongSymbol" SG_ 1419 Consumer_Heartbeat_Time14_1016_0 "Consumer_Heartbeat_Time14_1016_0E";
BA_ "SystemSignalLongSymbol" SG_ 1419 Consumer_Heartbeat_Time13_1016_0 "Consumer_Heartbeat_Time13_1016_0D";
BA_ "SystemSignalLongSymbol" SG_ 1419 Consumer_Heartbeat_Time12_1016_0 "Consumer_Heartbeat_Time12_1016_0C";
BA_ "SystemSignalLongSymbol" SG_ 1419 Consumer_Heartbeat_Time11_1016_0 "Consumer_Heartbeat_Time11_1016_0B";
BA_ "SystemSignalLongSymbol" SG_ 1419 Consumer_Heartbeat_Time10_1016_0 "Consumer_Heartbeat_Time10_1016_0A";
BA_ "GenSigStartValue" SG_ 1419 NrOfObjects_1016_00 16;
BA_ "GenSigStartValue" SG_ 1419 COB_ID_EMCY_1014 139;
BA_ "SystemSignalLongSymbol" SG_ 1419 Restore_all_Default_Parameters_1 "Restore_all_Default_Parameters_1011_01";
BA_ "GenSigStartValue" SG_ 1419 Number_of_Entries_1011_00 1;
BA_ "GenSigStartValue" SG_ 1419 Number_of_Entries_1010_00 1;
BA_ "GenSigStartValue" SG_ 1419 COB_ID_SYNC_1005 2147483776;
BA_ "GenSigStartValue" SG_ 1419 Device_Type_1000 197009;
BA_ "GenSigStartValue" SG_ 1419 Index 4096;
BA_ "GenSigStartValue" SG_ 1547 NrOfObjects_6320_00 16;
BA_ "GenSigStartValue" SG_ 1547 NrOfObjects_6300_00 16;
BA_ "GenSigStartValue" SG_ 1547 NrOfObjects_6220_00 64;
BA_ "GenSigStartValue" SG_ 1547 NrOfObjects_6200_00 16;
BA_ "GenSigStartValue" SG_ 1547 NrOfObjects_6120_00 16;
BA_ "GenSigStartValue" SG_ 1547 NrOfObjects_6100_00 16;
BA_ "GenSigStartValue" SG_ 1547 NrOfObjects_6020_00 64;
BA_ "GenSigStartValue" SG_ 1547 NrOfObjects_6000_00 16;
BA_ "GenSigStartValue" SG_ 1547 NrOfObjects_2300_00 4;
BA_ "GenSigStartValue" SG_ 1547 NrOfObjects_2200_00 4;
BA_ "GenSigStartValue" SG_ 1547 TransmissionType_1803_02 255;
BA_ "GenSigStartValue" SG_ 1547 COB_ID_1803_01 2147484811;
BA_ "GenSigStartValue" SG_ 1547 NrOfEntries_1803_00 5;
BA_ "GenSigStartValue" SG_ 1547 TransmissionType_1802_02 255;
BA_ "GenSigStartValue" SG_ 1547 COB_ID_1802_01 2147484555;
BA_ "GenSigStartValue" SG_ 1547 NrOfEntries_1802_00 5;
BA_ "GenSigStartValue" SG_ 1547 TransmissionType_1801_02 255;
BA_ "GenSigStartValue" SG_ 1547 COB_ID_1801_01 2147484299;
BA_ "GenSigStartValue" SG_ 1547 NrOfEntries_1801_00 5;
BA_ "GenSigStartValue" SG_ 1547 TransmissionType_1800_02 255;
BA_ "GenSigStartValue" SG_ 1547 COB_ID_1800_01 2147484043;
BA_ "GenSigStartValue" SG_ 1547 NrOfEntries_1800_00 5;
BA_ "GenSigStartValue" SG_ 1547 mappedObj2_1600_02 1644167688;
BA_ "GenSigStartValue" SG_ 1547 mappedObj1_1600_01 1644167432;
BA_ "GenSigStartValue" SG_ 1547 NrOfMappedObjects_1600_00 2;
BA_ "GenSigStartValue" SG_ 1547 TransmissionType_1403_02 255;
BA_ "GenSigStartValue" SG_ 1547 COB_ID_1403_01 2147484939;
BA_ "GenSigStartValue" SG_ 1547 NrOfEntries_1403_00 2;
BA_ "GenSigStartValue" SG_ 1547 TransmissionType_1402_02 255;
BA_ "GenSigStartValue" SG_ 1547 COB_ID_1402_01 2147484683;
BA_ "GenSigStartValue" SG_ 1547 NrOfEntries_1402_00 2;
BA_ "GenSigStartValue" SG_ 1547 TransmissionType_1401_02 255;
BA_ "GenSigStartValue" SG_ 1547 COB_ID_1401_01 2147484427;
BA_ "GenSigStartValue" SG_ 1547 NrOfEntries_1401_00 2;
BA_ "GenSigStartValue" SG_ 1547 TransmissionType_1400_02 255;
BA_ "GenSigStartValue" SG_ 1547 COB_ID_1400_01 394;
BA_ "GenSigStartValue" SG_ 1547 NrOfEntries_1400_00 2;
BA_ "GenSigStartValue" SG_ 1547 Revision_number_1018_03 256;
BA_ "GenSigStartValue" SG_ 1547 Product_Code_1018_02 305419896;
BA_ "GenSigStartValue" SG_ 1547 Vendor_Id_1018_01 5;
BA_ "GenSigStartValue" SG_ 1547 number_of_entries_1018_00 4;
BA_ "SystemSignalLongSymbol" SG_ 1547 Consumer_Heartbeat_Time16_1_0000 "Consumer_Heartbeat_Time16_1016_10";
BA_ "SystemSignalLongSymbol" SG_ 1547 Consumer_Heartbeat_Time15_1_0000 "Consumer_Heartbeat_Time15_1016_0F";
BA_ "SystemSignalLongSymbol" SG_ 1547 Consumer_Heartbeat_Time14_1_0000 "Consumer_Heartbeat_Time14_1016_0E";
BA_ "SystemSignalLongSymbol" SG_ 1547 Consumer_Heartbeat_Time13_1_0000 "Consumer_Heartbeat_Time13_1016_0D";
BA_ "SystemSignalLongSymbol" SG_ 1547 Consumer_Heartbeat_Time12_1_0000 "Consumer_Heartbeat_Time12_1016_0C";
BA_ "SystemSignalLongSymbol" SG_ 1547 Consumer_Heartbeat_Time11_1_0000 "Consumer_Heartbeat_Time11_1016_0B";
BA_ "SystemSignalLongSymbol" SG_ 1547 Consumer_Heartbeat_Time10_1_0000 "Consumer_Heartbeat_Time10_1016_0A";
BA_ "GenSigStartValue" SG_ 1547 NrOfObjects_1016_00 16;
BA_ "GenSigStartValue" SG_ 1547 COB_ID_EMCY_1014 139;
BA_ "SystemSignalLongSymbol" SG_ 1547 Restore_all_Default_Paramet_0000 "Restore_all_Default_Parameters_1011_01";
BA_ "GenSigStartValue" SG_ 1547 Number_of_Entries_1011_00 1;
BA_ "GenSigStartValue" SG_ 1547 Number_of_Entries_1010_00 1;
BA_ "GenSigStartValue" SG_ 1547 COB_ID_SYNC_1005 2147483776;
BA_ "GenSigStartValue" SG_ 1547 Device_Type_1000 197009;
BA_ "GenSigStartValue" SG_ 1547 Index 4096;
BA_ "GenSigStartValue" SG_ 1409 NrOfObjects_A4C0_00 2;
BA_ "GenSigStartValue" SG_ 1409 NrOfObjects_1F88_00 127;
BA_ "GenSigStartValue" SG_ 1409 NrOfObjects_1F87_00 127;
VAL_ 1803 State 127 "PreOperational" 5 "Operational" 4 "Stopped" 0 "Bootup" ;
VAL_ 1419 SubIndex_6320 16 "Write Output 32-Bit16" 15 "Write Output 32-Bit15" 14 "Write Output 32-Bit14" 13 "Write Output 32-Bit13" 12 "Write Output 32-Bit12" 11 "Write Output 32-Bit11" 10 "Write Output 32-Bit10" 9 "Write Output 32-Bit9" 8 "Write Output 32-Bit8" 7 "Write Output 32-Bit7" 6 "Write Output 32-Bit6" 5 "Write Output 32-Bit5" 4 "Write Output 32-Bit4" 3 "Write Output 32-Bit3" 2 "Write Output 32-Bit2" 1 "Write Output 32-Bit1" 0 "NrOfObjects" ;
VAL_ 1419 SubIndex_6300 16 "Write Output 16-Bit16" 15 "Write Output 16-Bit15" 14 "Write Output 16-Bit14" 13 "Write Output 16-Bit13" 12 "Write Output 16-Bit12" 11 "Write Output 16-Bit11" 10 "Write Output 16-Bit10" 9 "Write Output 16-Bit9" 8 "Write Output 16-Bit8" 7 "Write Output 16-Bit7" 6 "Write Output 16-Bit6" 5 "Write Output 16-Bit5" 4 "Write Output 16-Bit4" 3 "Write Output 16-Bit3" 2 "Write Output 16-Bit2" 1 "Write Output 16-Bit1" 0 "NrOfObjects" ;
VAL_ 1419 SubIndex_6220 64 "Write Output 1-Bit64" 63 "Write Output 1-Bit63" 62 "Write Output 1-Bit62" 61 "Write Output 1-Bit61" 60 "Write Output 1-Bit60" 59 "Write Output 1-Bit59" 58 "Write Output 1-Bit58" 57 "Write Output 1-Bit57" 56 "Write Output 1-Bit56" 55 "Write Output 1-Bit55" 54 "Write Output 1-Bit54" 53 "Write Output 1-Bit53" 52 "Write Output 1-Bit52" 51 "Write Output 1-Bit51" 50 "Write Output 1-Bit50" 49 "Write Output 1-Bit49" 48 "Write Output 1-Bit48" 47 "Write Output 1-Bit47" 46 "Write Output 1-Bit46" 45 "Write Output 1-Bit45" 44 "Write Output 1-Bit44" 43 "Write Output 1-Bit43" 42 "Write Output 1-Bit42" 41 "Write Output 1-Bit41" 40 "Write Output 1-Bit40" 39 "Write Output 1-Bit39" 38 "Write Output 1-Bit38" 37 "Write Output 1-Bit37" 36 "Write Output 1-Bit36" 35 "Write Output 1-Bit35" 34 "Write Output 1-Bit34" 33 "Write Output 1-Bit33" 32 "Write Output 1-Bit32" 31 "Write Output 1-Bit31" 30 "Write Output 1-Bit30" 29 "Write Output 1-Bit29" 28 "Write Output 1-Bit28" 27 "Write Output 1-Bit27" 26 "Write Output 1-Bit26" 25 "Write Output 1-Bit25" 24 "Write Output 1-Bit24" 23 "Write Output 1-Bit23" 22 "Write Output 1-Bit22" 21 "Write Output 1-Bit21" 20 "Write Output 1-Bit20" 19 "Write Output 1-Bit19" 18 "Write Output 1-Bit18" 17 "Write Output 1-Bit17" 16 "Write Output 1-Bit16" 15 "Write Output 1-Bit15" 14 "Write Output 1-Bit14" 13 "Write Output 1-Bit13" 12 "Write Output 1-Bit12" 11 "Write Output 1-Bit11" 10 "Write Output 1-Bit10" 9 "Write Output 1-Bit9" 8 "Write Output 1-Bit8" 7 "Write Output 1-Bit7" 6 "Write Output 1-Bit6" 5 "Write Output 1-Bit5" 4 "Write Output 1-Bit4" 3 "Write Output 1-Bit3" 2 "Write Output 1-Bit2" 1 "Write Output 1-Bit1" 0 "NrOfObjects" ;
VAL_ 1419 SubIndex_6200 16 "Write Output 8-Bit16" 15 "Write Output 8-Bit15" 14 "Write Output 8-Bit14" 13 "Write Output 8-Bit13" 12 "Write Output 8-Bit12" 11 "Write Output 8-Bit11" 10 "Write Output 8-Bit10" 9 "Write Output 8-Bit9" 8 "Write Output 8-Bit8" 7 "Write Output 8-Bit7" 6 "Write Output 8-Bit6" 5 "Write Output 8-Bit5" 4 "Write Output 8-Bit4" 3 "Write Output 8-Bit3" 2 "Write Output 8-Bit2" 1 "Write Output 8-Bit1" 0 "NrOfObjects" ;
VAL_ 1419 SubIndex_6120 16 "Read Input 32-Bit16" 15 "Read Input 32-Bit15" 14 "Read Input 32-Bit14" 13 "Read Input 32-Bit13" 12 "Read Input 32-Bit12" 11 "Read Input 32-Bit11" 10 "Read Input 32-Bit10" 9 "Read Input 32-Bit9" 8 "Read Input 32-Bit8" 7 "Read Input 32-Bit7" 6 "Read Input 32-Bit6" 5 "Read Input 32-Bit5" 4 "Read Input 32-Bit4" 3 "Read Input 32-Bit3" 2 "Read Input 32-Bit2" 1 "Read Input 32-Bit1" 0 "NrOfObjects" ;
VAL_ 1419 SubIndex_6100 16 "Read Input 16-Bit16" 15 "Read Input 16-Bit15" 14 "Read Input 16-Bit14" 13 "Read Input 16-Bit13" 12 "Read Input 16-Bit12" 11 "Read Input 16-Bit11" 10 "Read Input 16-Bit10" 9 "Read Input 16-Bit9" 8 "Read Input 16-Bit8" 7 "Read Input 16-Bit7" 6 "Read Input 16-Bit6" 5 "Read Input 16-Bit5" 4 "Read Input 16-Bit4" 3 "Read Input 16-Bit3" 2 "Read Input 16-Bit2" 1 "Read Input 16-Bit1" 0 "NrOfObjects" ;
VAL_ 1419 SubIndex_6020 64 "Read Input 1-Bit64" 63 "Read Input 1-Bit63" 62 "Read Input 1-Bit62" 61 "Read Input 1-Bit61" 60 "Read Input 1-Bit60" 59 "Read Input 1-Bit59" 58 "Read Input 1-Bit58" 57 "Read Input 1-Bit57" 56 "Read Input 1-Bit56" 55 "Read Input 1-Bit55" 54 "Read Input 1-Bit54" 53 "Read Input 1-Bit53" 52 "Read Input 1-Bit52" 51 "Read Input 1-Bit51" 50 "Read Input 1-Bit50" 49 "Read Input 1-Bit49" 48 "Read Input 1-Bit48" 47 "Read Input 1-Bit47" 46 "Read Input 1-Bit46" 45 "Read Input 1-Bit45" 44 "Read Input 1-Bit44" 43 "Read Input 1-Bit43" 42 "Read Input 1-Bit42" 41 "Read Input 1-Bit41" 40 "Read Input 1-Bit40" 39 "Read Input 1-Bit39" 38 "Read Input 1-Bit38" 37 "Read Input 1-Bit37" 36 "Read Input 1-Bit36" 35 "Read Input 1-Bit35" 34 "Read Input 1-Bit34" 33 "Read Input 1-Bit33" 32 "Read Input 1-Bit32" 31 "Read Input 1-Bit31" 30 "Read Input 1-Bit30" 29 "Read Input 1-Bit29" 28 "Read Input 1-Bit28" 27 "Read Input 1-Bit27" 26 "Read Input 1-Bit26" 25 "Read Input 1-Bit25" 24 "Read Input 1-Bit24" 23 "Read Input 1-Bit23" 22 "Read Input 1-Bit22" 21 "Read Input 1-Bit21" 20 "Read Input 1-Bit20" 19 "Read Input 1-Bit19" 18 "Read Input 1-Bit18" 17 "Read Input 1-Bit17" 16 "Read Input 1-Bit16" 15 "Read Input 1-Bit15" 14 "Read Input 1-Bit14" 13 "Read Input 1-Bit13" 12 "Read Input 1-Bit12" 11 "Read Input 1-Bit11" 10 "Read Input 1-Bit10" 9 "Read Input 1-Bit9" 8 "Read Input 1-Bit8" 7 "Read Input 1-Bit7" 6 "Read Input 1-Bit6" 5 "Read Input 1-Bit5" 4 "Read Input 1-Bit4" 3 "Read Input 1-Bit3" 2 "Read Input 1-Bit2" 1 "Read Input 1-Bit1" 0 "NrOfObjects" ;
VAL_ 1419 SubIndex_6000 16 "Read Input 8-Bit16" 15 "Read Input 8-Bit15" 14 "Read Input 8-Bit14" 13 "Read Input 8-Bit13" 12 "Read Input 8-Bit12" 11 "Read Input 8-Bit11" 10 "Read Input 8-Bit10" 9 "Read Input 8-Bit9" 8 "Read Input 8-Bit8" 7 "Read Input 8-Bit7" 6 "Read Input 8-Bit6" 5 "Read Input 8-Bit5" 4 "Read Input 8-Bit4" 3 "Read Input 8-Bit3" 2 "Read Input 8-Bit2" 1 "Read Input 8-Bit1" 0 "NrOfObjects" ;
VAL_ 1419 SubIndex_2300 0 "NrOfObjects" ;
VAL_ 1419 SubIndex_2200 0 "NrOfObjects" ;
VAL_ 1419 SubIndex_1A03 0 "NrOfMappedObjects" ;
VAL_ 1419 SubIndex_1A02 0 "NrOfMappedObjects" ;
VAL_ 1419 SubIndex_1A01 0 "NrOfMappedObjects" ;
VAL_ 1419 SubIndex_1A00 0 "NrOfMappedObjects" ;
VAL_ 1419 SubIndex_1803 5 "EventTimer" 2 "TransmissionType" 1 "COB-ID" 0 "NrOfEntries" ;
VAL_ 1419 SubIndex_1802 5 "EventTimer" 2 "TransmissionType" 1 "COB-ID" 0 "NrOfEntries" ;
VAL_ 1419 SubIndex_1801 5 "EventTimer" 2 "TransmissionType" 1 "COB-ID" 0 "NrOfEntries" ;
VAL_ 1419 SubIndex_1800 5 "EventTimer" 2 "TransmissionType" 1 "COB-ID" 0 "NrOfEntries" ;
VAL_ 1419 SubIndex_1603 0 "NrOfMappedObjects" ;
VAL_ 1419 SubIndex_1602 0 "NrOfMappedObjects" ;
VAL_ 1419 SubIndex_1601 0 "NrOfMappedObjects" ;
VAL_ 1419 SubIndex_1600 2 "mappedObj2" 1 "mappedObj1" 0 "NrOfMappedObjects" ;
VAL_ 1419 SubIndex_1403 2 "TransmissionType" 1 "COB-ID" 0 "NrOfEntries" ;
VAL_ 1419 SubIndex_1402 2 "TransmissionType" 1 "COB-ID" 0 "NrOfEntries" ;
VAL_ 1419 SubIndex_1401 2 "TransmissionType" 1 "COB-ID" 0 "NrOfEntries" ;
VAL_ 1419 SubIndex_1400 2 "TransmissionType" 1 "COB-ID" 0 "NrOfEntries" ;
VAL_ 1419 SubIndex_1018 4 "Serial number" 3 "Revision number" 2 "Product Code" 1 "Vendor Id" 0 "number of entries" ;
VAL_ 1419 SubIndex_1017 0 "Producer Heartbeat Time" ;
VAL_ 1419 SubIndex_1016 16 "Consumer Heartbeat Time16" 15 "Consumer Heartbeat Time15" 14 "Consumer Heartbeat Time14" 13 "Consumer Heartbeat Time13" 12 "Consumer Heartbeat Time12" 11 "Consumer Heartbeat Time11" 10 "Consumer Heartbeat Time10" 9 "Consumer Heartbeat Time9" 8 "Consumer Heartbeat Time8" 7 "Consumer Heartbeat Time7" 6 "Consumer Heartbeat Time6" 5 "Consumer Heartbeat Time5" 4 "Consumer Heartbeat Time4" 3 "Consumer Heartbeat Time3" 2 "Consumer Heartbeat Time2" 1 "Consumer Heartbeat Time1" 0 "NrOfObjects" ;
VAL_ 1419 SubIndex_1014 0 "COB-ID EMCY" ;
VAL_ 1419 SubIndex_1011 1 "Restore all Default Parameters" 0 "Number of Entries" ;
VAL_ 1419 SubIndex_1010 1 "Save all Parameters" 0 "Number of Entries" ;
VAL_ 1419 SubIndex_100D 0 "Life Time Factor" ;
VAL_ 1419 SubIndex_100C 0 "Guard Time" ;
VAL_ 1419 SubIndex_1007 0 "Synchronous Window Length" ;
VAL_ 1419 SubIndex_1006 0 "Communication Cycle Period" ;
VAL_ 1419 SubIndex_1005 0 "COB-ID SYNC" ;
VAL_ 1419 SubIndex_1003 9 "Standard error field" 8 "Standard error field" 7 "Standard error field" 6 "Standard error field" 5 "Standard error field" 4 "Standard error field" 3 "Standard error field" 2 "Standard error field" 1 "Standard error field" 0 "Number of Errors" ;
VAL_ 1419 SubIndex_1001 0 "Error Register" ;
VAL_ 1419 SubIndex_1000 0 "Device Type" ;
VAL_ 1419 Index 25376 "Write Output 32-Bit" 25344 "Write Output 16-Bit" 25120 "Write Output 1-Bit" 25088 "Write Output 8-Bit" 24864 "Read Input 32-Bit" 24832 "Read Input 16-Bit" 24608 "Read Input 1-Bit" 24576 "Read Input 8-Bit" 8960 "Write Output 64-Bit" 8704 "Read Input 64-Bit" 6659 "TxPDOMapping" 6658 "TxPDOMapping" 6657 "TxPDOMapping" 6656 "TxPDOMapping" 6147 "TxPDOComPar" 6146 "TxPDOComPar" 6145 "TxPDOComPar" 6144 "TxPDOComPar" 5635 "RxPDOMapping" 5634 "RxPDOMapping" 5633 "RxPDOMapping" 5632 "RxPDOMapping" 5123 "RxPDOComPar" 5122 "RxPDOComPar" 5121 "RxPDOComPar" 5120 "RxPDOComPar" 4120 "Identity Object" 4119 "Producer Heartbeat Time" 4118 "Consumer Heartbeat Time" 4116 "COB-ID EMCY" 4113 "Restore Default Parameters" 4112 "Store Parameter Field" 4109 "Life Time Factor" 4108 "Guard Time" 4103 "Synchronous Window Length" 4102 "Communication Cycle Period" 4101 "COB-ID SYNC" 4099 "Pre-defined Error Field" 4097 "Error Register" 4096 "Device Type" ;
VAL_ 1419 TransferType 1 "Expedited transfer" 0 "Normal transfer" ;
VAL_ 1419 SizeIndicator 1 "Size is indicated" 0 "Size is not indicated" ;
VAL_ 1419 SCS 2 "Upload" 1 "Download" ;
VAL_ 1547 SubIndex_6320 16 "Write Output 32-Bit16" 15 "Write Output 32-Bit15" 14 "Write Output 32-Bit14" 13 "Write Output 32-Bit13" 12 "Write Output 32-Bit12" 11 "Write Output 32-Bit11" 10 "Write Output 32-Bit10" 9 "Write Output 32-Bit9" 8 "Write Output 32-Bit8" 7 "Write Output 32-Bit7" 6 "Write Output 32-Bit6" 5 "Write Output 32-Bit5" 4 "Write Output 32-Bit4" 3 "Write Output 32-Bit3" 2 "Write Output 32-Bit2" 1 "Write Output 32-Bit1" 0 "NrOfObjects" ;
VAL_ 1547 SubIndex_6300 16 "Write Output 16-Bit16" 15 "Write Output 16-Bit15" 14 "Write Output 16-Bit14" 13 "Write Output 16-Bit13" 12 "Write Output 16-Bit12" 11 "Write Output 16-Bit11" 10 "Write Output 16-Bit10" 9 "Write Output 16-Bit9" 8 "Write Output 16-Bit8" 7 "Write Output 16-Bit7" 6 "Write Output 16-Bit6" 5 "Write Output 16-Bit5" 4 "Write Output 16-Bit4" 3 "Write Output 16-Bit3" 2 "Write Output 16-Bit2" 1 "Write Output 16-Bit1" 0 "NrOfObjects" ;
VAL_ 1547 SubIndex_6220 64 "Write Output 1-Bit64" 63 "Write Output 1-Bit63" 62 "Write Output 1-Bit62" 61 "Write Output 1-Bit61" 60 "Write Output 1-Bit60" 59 "Write Output 1-Bit59" 58 "Write Output 1-Bit58" 57 "Write Output 1-Bit57" 56 "Write Output 1-Bit56" 55 "Write Output 1-Bit55" 54 "Write Output 1-Bit54" 53 "Write Output 1-Bit53" 52 "Write Output 1-Bit52" 51 "Write Output 1-Bit51" 50 "Write Output 1-Bit50" 49 "Write Output 1-Bit49" 48 "Write Output 1-Bit48" 47 "Write Output 1-Bit47" 46 "Write Output 1-Bit46" 45 "Write Output 1-Bit45" 44 "Write Output 1-Bit44" 43 "Write Output 1-Bit43" 42 "Write Output 1-Bit42" 41 "Write Output 1-Bit41" 40 "Write Output 1-Bit40" 39 "Write Output 1-Bit39" 38 "Write Output 1-Bit38" 37 "Write Output 1-Bit37" 36 "Write Output 1-Bit36" 35 "Write Output 1-Bit35" 34 "Write Output 1-Bit34" 33 "Write Output 1-Bit33" 32 "Write Output 1-Bit32" 31 "Write Output 1-Bit31" 30 "Write Output 1-Bit30" 29 "Write Output 1-Bit29" 28 "Write Output 1-Bit28" 27 "Write Output 1-Bit27" 26 "Write Output 1-Bit26" 25 "Write Output 1-Bit25" 24 "Write Output 1-Bit24" 23 "Write Output 1-Bit23" 22 "Write Output 1-Bit22" 21 "Write Output 1-Bit21" 20 "Write Output 1-Bit20" 19 "Write Output 1-Bit19" 18 "Write Output 1-Bit18" 17 "Write Output 1-Bit17" 16 "Write Output 1-Bit16" 15 "Write Output 1-Bit15" 14 "Write Output 1-Bit14" 13 "Write Output 1-Bit13" 12 "Write Output 1-Bit12" 11 "Write Output 1-Bit11" 10 "Write Output 1-Bit10" 9 "Write Output 1-Bit9" 8 "Write Output 1-Bit8" 7 "Write Output 1-Bit7" 6 "Write Output 1-Bit6" 5 "Write Output 1-Bit5" 4 "Write Output 1-Bit4" 3 "Write Output 1-Bit3" 2 "Write Output 1-Bit2" 1 "Write Output 1-Bit1" 0 "NrOfObjects" ;
VAL_ 1547 SubIndex_6200 16 "Write Output 8-Bit16" 15 "Write Output 8-Bit15" 14 "Write Output 8-Bit14" 13 "Write Output 8-Bit13" 12 "Write Output 8-Bit12" 11 "Write Output 8-Bit11" 10 "Write Output 8-Bit10" 9 "Write Output 8-Bit9" 8 "Write Output 8-Bit8" 7 "Write Output 8-Bit7" 6 "Write Output 8-Bit6" 5 "Write Output 8-Bit5" 4 "Write Output 8-Bit4" 3 "Write Output 8-Bit3" 2 "Write Output 8-Bit2" 1 "Write Output 8-Bit1" 0 "NrOfObjects" ;
VAL_ 1547 SubIndex_6120 16 "Read Input 32-Bit16" 15 "Read Input 32-Bit15" 14 "Read Input 32-Bit14" 13 "Read Input 32-Bit13" 12 "Read Input 32-Bit12" 11 "Read Input 32-Bit11" 10 "Read Input 32-Bit10" 9 "Read Input 32-Bit9" 8 "Read Input 32-Bit8" 7 "Read Input 32-Bit7" 6 "Read Input 32-Bit6" 5 "Read Input 32-Bit5" 4 "Read Input 32-Bit4" 3 "Read Input 32-Bit3" 2 "Read Input 32-Bit2" 1 "Read Input 32-Bit1" 0 "NrOfObjects" ;
VAL_ 1547 SubIndex_6100 16 "Read Input 16-Bit16" 15 "Read Input 16-Bit15" 14 "Read Input 16-Bit14" 13 "Read Input 16-Bit13" 12 "Read Input 16-Bit12" 11 "Read Input 16-Bit11" 10 "Read Input 16-Bit10" 9 "Read Input 16-Bit9" 8 "Read Input 16-Bit8" 7 "Read Input 16-Bit7" 6 "Read Input 16-Bit6" 5 "Read Input 16-Bit5" 4 "Read Input 16-Bit4" 3 "Read Input 16-Bit3" 2 "Read Input 16-Bit2" 1 "Read Input 16-Bit1" 0 "NrOfObjects" ;
VAL_ 1547 SubIndex_6020 64 "Read Input 1-Bit64" 63 "Read Input 1-Bit63" 62 "Read Input 1-Bit62" 61 "Read Input 1-Bit61" 60 "Read Input 1-Bit60" 59 "Read Input 1-Bit59" 58 "Read Input 1-Bit58" 57 "Read Input 1-Bit57" 56 "Read Input 1-Bit56" 55 "Read Input 1-Bit55" 54 "Read Input 1-Bit54" 53 "Read Input 1-Bit53" 52 "Read Input 1-Bit52" 51 "Read Input 1-Bit51" 50 "Read Input 1-Bit50" 49 "Read Input 1-Bit49" 48 "Read Input 1-Bit48" 47 "Read Input 1-Bit47" 46 "Read Input 1-Bit46" 45 "Read Input 1-Bit45" 44 "Read Input 1-Bit44" 43 "Read Input 1-Bit43" 42 "Read Input 1-Bit42" 41 "Read Input 1-Bit41" 40 "Read Input 1-Bit40" 39 "Read Input 1-Bit39" 38 "Read Input 1-Bit38" 37 "Read Input 1-Bit37" 36 "Read Input 1-Bit36" 35 "Read Input 1-Bit35" 34 "Read Input 1-Bit34" 33 "Read Input 1-Bit33" 32 "Read Input 1-Bit32" 31 "Read Input 1-Bit31" 30 "Read Input 1-Bit30" 29 "Read Input 1-Bit29" 28 "Read Input 1-Bit28" 27 "Read Input 1-Bit27" 26 "Read Input 1-Bit26" 25 "Read Input 1-Bit25" 24 "Read Input 1-Bit24" 23 "Read Input 1-Bit23" 22 "Read Input 1-Bit22" 21 "Read Input 1-Bit21" 20 "Read Input 1-Bit20" 19 "Read Input 1-Bit19" 18 "Read Input 1-Bit18" 17 "Read Input 1-Bit17" 16 "Read Input 1-Bit16" 15 "Read Input 1-Bit15" 14 "Read Input 1-Bit14" 13 "Read Input 1-Bit13" 12 "Read Input 1-Bit12" 11 "Read Input 1-Bit11" 10 "Read Input 1-Bit10" 9 "Read Input 1-Bit9" 8 "Read Input 1-Bit8" 7 "Read Input 1-Bit7" 6 "Read Input 1-Bit6" 5 "Read Input 1-Bit5" 4 "Read Input 1-Bit4" 3 "Read Input 1-Bit3" 2 "Read Input 1-Bit2" 1 "Read Input 1-Bit1" 0 "NrOfObjects" ;
VAL_ 1547 SubIndex_6000 16 "Read Input 8-Bit16" 15 "Read Input 8-Bit15" 14 "Read Input 8-Bit14" 13 "Read Input 8-Bit13" 12 "Read Input 8-Bit12" 11 "Read Input 8-Bit11" 10 "Read Input 8-Bit10" 9 "Read Input 8-Bit9" 8 "Read Input 8-Bit8" 7 "Read Input 8-Bit7" 6 "Read Input 8-Bit6" 5 "Read Input 8-Bit5" 4 "Read Input 8-Bit4" 3 "Read Input 8-Bit3" 2 "Read Input 8-Bit2" 1 "Read Input 8-Bit1" 0 "NrOfObjects" ;
VAL_ 1547 SubIndex_2300 0 "NrOfObjects" ;
VAL_ 1547 SubIndex_2200 0 "NrOfObjects" ;
VAL_ 1547 SubIndex_1A03 0 "NrOfMappedObjects" ;
VAL_ 1547 SubIndex_1A02 0 "NrOfMappedObjects" ;
VAL_ 1547 SubIndex_1A01 0 "NrOfMappedObjects" ;
VAL_ 1547 SubIndex_1A00 0 "NrOfMappedObjects" ;
VAL_ 1547 SubIndex_1803 5 "EventTimer" 2 "TransmissionType" 1 "COB-ID" 0 "NrOfEntries" ;
VAL_ 1547 SubIndex_1802 5 "EventTimer" 2 "TransmissionType" 1 "COB-ID" 0 "NrOfEntries" ;
VAL_ 1547 SubIndex_1801 5 "EventTimer" 2 "TransmissionType" 1 "COB-ID" 0 "NrOfEntries" ;
VAL_ 1547 SubIndex_1800 5 "EventTimer" 2 "TransmissionType" 1 "COB-ID" 0 "NrOfEntries" ;
VAL_ 1547 SubIndex_1603 0 "NrOfMappedObjects" ;
VAL_ 1547 SubIndex_1602 0 "NrOfMappedObjects" ;
VAL_ 1547 SubIndex_1601 0 "NrOfMappedObjects" ;
VAL_ 1547 SubIndex_1600 2 "mappedObj2" 1 "mappedObj1" 0 "NrOfMappedObjects" ;
VAL_ 1547 SubIndex_1403 2 "TransmissionType" 1 "COB-ID" 0 "NrOfEntries" ;
VAL_ 1547 SubIndex_1402 2 "TransmissionType" 1 "COB-ID" 0 "NrOfEntries" ;
VAL_ 1547 SubIndex_1401 2 "TransmissionType" 1 "COB-ID" 0 "NrOfEntries" ;
VAL_ 1547 SubIndex_1400 2 "TransmissionType" 1 "COB-ID" 0 "NrOfEntries" ;
VAL_ 1547 SubIndex_1018 4 "Serial number" 3 "Revision number" 2 "Product Code" 1 "Vendor Id" 0 "number of entries" ;
VAL_ 1547 SubIndex_1017 0 "Producer Heartbeat Time" ;
VAL_ 1547 SubIndex_1016 16 "Consumer Heartbeat Time16" 15 "Consumer Heartbeat Time15" 14 "Consumer Heartbeat Time14" 13 "Consumer Heartbeat Time13" 12 "Consumer Heartbeat Time12" 11 "Consumer Heartbeat Time11" 10 "Consumer Heartbeat Time10" 9 "Consumer Heartbeat Time9" 8 "Consumer Heartbeat Time8" 7 "Consumer Heartbeat Time7" 6 "Consumer Heartbeat Time6" 5 "Consumer Heartbeat Time5" 4 "Consumer Heartbeat Time4" 3 "Consumer Heartbeat Time3" 2 "Consumer Heartbeat Time2" 1 "Consumer Heartbeat Time1" 0 "NrOfObjects" ;
VAL_ 1547 SubIndex_1014 0 "COB-ID EMCY" ;
VAL_ 1547 SubIndex_1011 1 "Restore all Default Parameters" 0 "Number of Entries" ;
VAL_ 1547 SubIndex_1010 1 "Save all Parameters" 0 "Number of Entries" ;
VAL_ 1547 SubIndex_100D 0 "Life Time Factor" ;
VAL_ 1547 SubIndex_100C 0 "Guard Time" ;
VAL_ 1547 SubIndex_1007 0 "Synchronous Window Length" ;
VAL_ 1547 SubIndex_1006 0 "Communication Cycle Period" ;
VAL_ 1547 SubIndex_1005 0 "COB-ID SYNC" ;
VAL_ 1547 SubIndex_1003 9 "Standard error field" 8 "Standard error field" 7 "Standard error field" 6 "Standard error field" 5 "Standard error field" 4 "Standard error field" 3 "Standard error field" 2 "Standard error field" 1 "Standard error field" 0 "Number of Errors" ;
VAL_ 1547 SubIndex_1001 0 "Error Register" ;
VAL_ 1547 SubIndex_1000 0 "Device Type" ;
VAL_ 1547 Index 25376 "Write Output 32-Bit" 25344 "Write Output 16-Bit" 25120 "Write Output 1-Bit" 25088 "Write Output 8-Bit" 24864 "Read Input 32-Bit" 24832 "Read Input 16-Bit" 24608 "Read Input 1-Bit" 24576 "Read Input 8-Bit" 8960 "Write Output 64-Bit" 8704 "Read Input 64-Bit" 6659 "TxPDOMapping" 6658 "TxPDOMapping" 6657 "TxPDOMapping" 6656 "TxPDOMapping" 6147 "TxPDOComPar" 6146 "TxPDOComPar" 6145 "TxPDOComPar" 6144 "TxPDOComPar" 5635 "RxPDOMapping" 5634 "RxPDOMapping" 5633 "RxPDOMapping" 5632 "RxPDOMapping" 5123 "RxPDOComPar" 5122 "RxPDOComPar" 5121 "RxPDOComPar" 5120 "RxPDOComPar" 4120 "Identity Object" 4119 "Producer Heartbeat Time" 4118 "Consumer Heartbeat Time" 4116 "COB-ID EMCY" 4113 "Restore Default Parameters" 4112 "Store Parameter Field" 4109 "Life Time Factor" 4108 "Guard Time" 4103 "Synchronous Window Length" 4102 "Communication Cycle Period" 4101 "COB-ID SYNC" 4099 "Pre-defined Error Field" 4097 "Error Register" 4096 "Device Type" ;
VAL_ 1547 TransferType 1 "Expedited transfer" 0 "Normal transfer" ;
VAL_ 1547 SizeIndicator 1 "Size is indicated" 0 "Size is not indicated" ;
VAL_ 1547 CCS 2 "Upload" 1 "Download" ;
VAL_ 139 ErrorCode 13088 "(DS-401) Output voltage too low" 13072 "(DS-401) Output voltage too high" 12832 "(DS-401) Internal voltage too low" 12816 "(DS-401) Internal voltage too high" 12576 "(DS-401) Input voltage too low" 12560 "(DS-401) Input voltage too high" 9008 "(DS-401) Load dump at outputs" 8992 "(DS-401) Short circuit at outputs" 8976 "(DS-401) Current at outputs too high (overload)" 128 "(DS-401) Warning: Analogue inputs disabled" 33360 "RPDO timeout" 33344 "Unexpected SYNC data length" 33328 "DAM MPDO not processed, destination object not available" 33312 "PDO length exceeded" 33296 "PDO not processed due to length error" 33104 "Transmit COB-ID collision" 33088 "Recovered from bus off state" 33072 "Life guard error or heartbeat error" 33056 "CAN in error passive mode" 33040 "CAN overrun (objects lost)" ;
VAL_ 1793 State 127 "PreOperational" 5 "Operational" 4 "Stopped" 0 "Bootup" ;
VAL_ 1409 SubIndex_A4C0 2 "ReadInput8_Bit4" 1 "ReadInput8_Bit3" 0 "NrOfObjects" ;
VAL_ 1409 SubIndex_1F89 0 "BootTime" ;
VAL_ 1409 SubIndex_1F88 127 "SerialNumber127" 126 "SerialNumber126" 125 "SerialNumber125" 124 "SerialNumber124" 123 "SerialNumber123" 122 "SerialNumber122" 121 "SerialNumber121" 120 "SerialNumber120" 119 "SerialNumber119" 118 "SerialNumber118" 117 "SerialNumber117" 116 "SerialNumber116" 115 "SerialNumber115" 114 "SerialNumber114" 113 "SerialNumber113" 112 "SerialNumber112" 111 "SerialNumber111" 110 "SerialNumber110" 109 "SerialNumber109" 108 "SerialNumber108" 107 "SerialNumber107" 106 "SerialNumber106" 105 "SerialNumber105" 104 "SerialNumber104" 103 "SerialNumber103" 102 "SerialNumber102" 101 "SerialNumber101" 100 "SerialNumber100" 99 "SerialNumber99" 98 "SerialNumber98" 97 "SerialNumber97" 96 "SerialNumber96" 95 "SerialNumber95" 94 "SerialNumber94" 93 "SerialNumber93" 92 "SerialNumber92" 91 "SerialNumber91" 90 "SerialNumber90" 89 "SerialNumber89" 88 "SerialNumber88" 87 "SerialNumber87" 86 "SerialNumber86" 85 "SerialNumber85" 84 "SerialNumber84" 83 "SerialNumber83" 82 "SerialNumber82" 81 "SerialNumber81" 80 "SerialNumber80" 79 "SerialNumber79" 78 "SerialNumber78" 77 "SerialNumber77" 76 "SerialNumber76" 75 "SerialNumber75" 74 "SerialNumber74" 73 "SerialNumber73" 72 "SerialNumber72" 71 "SerialNumber71" 70 "SerialNumber70" 69 "SerialNumber69" 68 "SerialNumber68" 67 "SerialNumber67" 66 "SerialNumber66" 65 "SerialNumber65" 64 "SerialNumber64" 63 "SerialNumber63" 62 "SerialNumber62" 61 "SerialNumber61" 60 "SerialNumber60" 59 "SerialNumber59" 58 "SerialNumber58" 57 "SerialNumber57" 56 "SerialNumber56" 55 "SerialNumber55" 54 "SerialNumber54" 53 "SerialNumber53" 52 "SerialNumber52" 51 "SerialNumber51" 50 "SerialNumber50" 49 "SerialNumber49" 48 "SerialNumber48" 47 "SerialNumber47" 46 "SerialNumber46" 45 "SerialNumber45" 44 "SerialNumber44" 43 "SerialNumber43" 42 "SerialNumber42" 41 "SerialNumber41" 40 "SerialNumber40" 39 "SerialNumber39" 38 "SerialNumber38" 37 "SerialNumber37" 36 "SerialNumber36" 35 "SerialNumber35" 34 "SerialNumber34" 33 "SerialNumber33" 32 "SerialNumber32" 31 "SerialNumber31" 30 "SerialNumber30" 29 "SerialNumber29" 28 "SerialNumber28" 27 "SerialNumber27" 26 "SerialNumber26" 25 "SerialNumber25" 24 "SerialNumber24" 23 "SerialNumber23" 22 "SerialNumber22" 21 "SerialNumber21" 20 "SerialNumber20" 19 "SerialNumber19" 18 "SerialNumber18" 17 "SerialNumber17" 16 "SerialNumber16" 15 "SerialNumber15" 14 "SerialNumber14" 13 "SerialNumber13" 12 "SerialNumber12" 11 "SerialNumber11" 10 "SerialNumber10" 9 "SerialNumber9" 8 "SerialNumber8" 7 "SerialNumber7" 6 "SerialNumber6" 5 "SerialNumber5" 4 "SerialNumber4" 3 "SerialNumber3" 2 "SerialNumber2" 1 "SerialNumber1" 0 "NrOfObjects" ;
VAL_ 1409 SubIndex_1F87 127 "RevisionNumber127" 126 "RevisionNumber126" 125 "RevisionNumber125" 124 "RevisionNumber124" 123 "RevisionNumber123" 122 "RevisionNumber122" 121 "RevisionNumber121" 120 "RevisionNumber120" 119 "RevisionNumber119" 118 "RevisionNumber118" 117 "RevisionNumber117" 116 "RevisionNumber116" 115 "RevisionNumber115" 114 "RevisionNumber114" 113 "RevisionNumber113" 112 "RevisionNumber112" 111 "RevisionNumber111" 110 "RevisionNumber110" 109 "RevisionNumber109" 108 "RevisionNumber108" 107 "RevisionNumber107" 106 "RevisionNumber106" 105 "RevisionNumber105" 104 "RevisionNumber104" 103 "RevisionNumber103" 102 "RevisionNumber102" 101 "RevisionNumber101" 100 "RevisionNumber100" 99 "RevisionNumber99" 98 "RevisionNumber98" 97 "RevisionNumber97" 96 "RevisionNumber96" 95 "RevisionNumber95" 94 "RevisionNumber94" 93 "RevisionNumber93" 92 "RevisionNumber92" 91 "RevisionNumber91" 90 "RevisionNumber90" 89 "RevisionNumber89" 88 "RevisionNumber88" 87 "RevisionNumber87" 86 "RevisionNumber86" 85 "RevisionNumber85" 84 "RevisionNumber84" 83 "RevisionNumber83" 82 "RevisionNumber82" 81 "RevisionNumber81" 80 "RevisionNumber80" 79 "RevisionNumber79" 78 "RevisionNumber78" 77 "RevisionNumber77" 76 "RevisionNumber76" 75 "RevisionNumber75" 74 "RevisionNumber74" 73 "RevisionNumber73" 72 "RevisionNumber72" 71 "RevisionNumber71" 70 "RevisionNumber70" 69 "RevisionNumber69" 68 "RevisionNumber68" 67 "RevisionNumber67" 66 "RevisionNumber66" 65 "RevisionNumber65" 64 "RevisionNumber64" 63 "RevisionNumber63" 62 "RevisionNumber62" 61 "RevisionNumber61" 60 "RevisionNumber60" 59 "RevisionNumber59" 58 "RevisionNumber58" 57 "RevisionNumber57" 56 "RevisionNumber56" 55 "RevisionNumber55" 54 "RevisionNumber54" 53 "RevisionNumber53" 52 "RevisionNumber52" 51 "RevisionNumber51" 50 "RevisionNumber50" 49 "RevisionNumber49" 48 "RevisionNumber48" 47 "RevisionNumber47" 46 "RevisionNumber46" 45 "RevisionNumber45" 44 "RevisionNumber44" 43 "RevisionNumber43" 42 "RevisionNumber42" 41 "RevisionNumber41" 40 "RevisionNumber40" 39 "RevisionNumber39" 38 "RevisionNumber38" 37 "RevisionNumber37" 36 "RevisionNumber36" 35 "RevisionNumber35" 34 "RevisionNumber34" 33 "RevisionNumber33" 32 "RevisionNumber32" 31 "RevisionNumber31" 30 "RevisionNumber30" 29 "RevisionNumber29" 28 "RevisionNumber28" 27 "RevisionNumber27" 26 "RevisionNumber26" 25 "RevisionNumber25" 24 "RevisionNumber24" 23 "RevisionNumber23" 22 "RevisionNumber22" 21 "RevisionNumber21" 20 "RevisionNumber20" 19 "RevisionNumber19" 18 "RevisionNumber18" 17 "RevisionNumber17" 16 "RevisionNumber16" 15 "RevisionNumber15" 14 "RevisionNumber14" 13 "RevisionNumber13" 12 "RevisionNumber12" 11 "RevisionNumber11" 10 "RevisionNumber10" 9 "RevisionNumber9" 8 "RevisionNumber8" 7 "RevisionNumber7" 6 "RevisionNumber6" 5 "RevisionNumber5" 4 "RevisionNumber4" 3 "RevisionNumber3" 2 "RevisionNumber2" 1 "RevisionNumber1" 0 "NrOfObjects" ;

SG_MUL_VAL_ 1419 Write_Output_32_Bit16_6320_10 SubIndex_6320 16-16;
SG_MUL_VAL_ 1419 Write_Output_32_Bit15_6320_0F SubIndex_6320 15-15;
SG_MUL_VAL_ 1419 Write_Output_32_Bit14_6320_0E SubIndex_6320 14-14;
SG_MUL_VAL_ 1419 Write_Output_32_Bit13_6320_0D SubIndex_6320 13-13;
SG_MUL_VAL_ 1419 Write_Output_32_Bit12_6320_0C SubIndex_6320 12-12;
SG_MUL_VAL_ 1419 Write_Output_32_Bit11_6320_0B SubIndex_6320 11-11;
SG_MUL_VAL_ 1419 Write_Output_32_Bit10_6320_0A SubIndex_6320 10-10;
SG_MUL_VAL_ 1419 Write_Output_32_Bit9_6320_09 SubIndex_6320 9-9;
SG_MUL_VAL_ 1419 Write_Output_32_Bit8_6320_08 SubIndex_6320 8-8;
SG_MUL_VAL_ 1419 Write_Output_32_Bit7_6320_07 SubIndex_6320 7-7;
SG_MUL_VAL_ 1419 Write_Output_32_Bit6_6320_06 SubIndex_6320 6-6;
SG_MUL_VAL_ 1419 Write_Output_32_Bit5_6320_05 SubIndex_6320 5-5;
SG_MUL_VAL_ 1419 Write_Output_32_Bit4_6320_04 SubIndex_6320 4-4;
SG_MUL_VAL_ 1419 Write_Output_32_Bit3_6320_03 SubIndex_6320 3-3;
SG_MUL_VAL_ 1419 Write_Output_32_Bit2_6320_02 SubIndex_6320 2-2;
SG_MUL_VAL_ 1419 Write_Output_32_Bit1_6320_01 SubIndex_6320 1-1;
SG_MUL_VAL_ 1419 NrOfObjects_6320_00 SubIndex_6320 0-0;
SG_MUL_VAL_ 1419 SubIndex_6320 Index 25376-25376;
SG_MUL_VAL_ 1419 Write_Output_16_Bit16_6300_10 SubIndex_6300 16-16;
SG_MUL_VAL_ 1419 Write_Output_16_Bit15_6300_0F SubIndex_6300 15-15;
SG_MUL_VAL_ 1419 Write_Output_16_Bit14_6300_0E SubIndex_6300 14-14;
SG_MUL_VAL_ 1419 Write_Output_16_Bit13_6300_0D SubIndex_6300 13-13;
SG_MUL_VAL_ 1419 Write_Output_16_Bit12_6300_0C SubIndex_6300 12-12;
SG_MUL_VAL_ 1419 Write_Output_16_Bit11_6300_0B SubIndex_6300 11-11;
SG_MUL_VAL_ 1419 Write_Output_16_Bit10_6300_0A SubIndex_6300 10-10;
SG_MUL_VAL_ 1419 Write_Output_16_Bit9_6300_09 SubIndex_6300 9-9;
SG_MUL_VAL_ 1419 Write_Output_16_Bit8_6300_08 SubIndex_6300 8-8;
SG_MUL_VAL_ 1419 Write_Output_16_Bit7_6300_07 SubIndex_6300 7-7;
SG_MUL_VAL_ 1419 Write_Output_16_Bit6_6300_06 SubIndex_6300 6-6;
SG_MUL_VAL_ 1419 Write_Output_16_Bit5_6300_05 SubIndex_6300 5-5;
SG_MUL_VAL_ 1419 Write_Output_16_Bit4_6300_04 SubIndex_6300 4-4;
SG_MUL_VAL_ 1419 Write_Output_16_Bit3_6300_03 SubIndex_6300 3-3;
SG_MUL_VAL_ 1419 Write_Output_16_Bit2_6300_02 SubIndex_6300 2-2;
SG_MUL_VAL_ 1419 Write_Output_16_Bit1_6300_01 SubIndex_6300 1-1;
SG_MUL_VAL_ 1419 NrOfObjects_6300_00 SubIndex_6300 0-0;
SG_MUL_VAL_ 1419 SubIndex_6300 Index 25344-25344;
SG_MUL_VAL_ 1419 Write_Output_1_Bit64_6220_40 SubIndex_6220 64-64;
SG_MUL_VAL_ 1419 Write_Output_1_Bit63_6220_3F SubIndex_6220 63-63;
SG_MUL_VAL_ 1419 Write_Output_1_Bit62_6220_3E SubIndex_6220 62-62;
SG_MUL_VAL_ 1419 Write_Output_1_Bit61_6220_3D SubIndex_6220 61-61;
SG_MUL_VAL_ 1419 Write_Output_1_Bit60_6220_3C SubIndex_6220 60-60;
SG_MUL_VAL_ 1419 Write_Output_1_Bit59_6220_3B SubIndex_6220 59-59;
SG_MUL_VAL_ 1419 Write_Output_1_Bit58_6220_3A SubIndex_6220 58-58;
SG_MUL_VAL_ 1419 Write_Output_1_Bit57_6220_39 SubIndex_6220 57-57;
SG_MUL_VAL_ 1419 Write_Output_1_Bit56_6220_38 SubIndex_6220 56-56;
SG_MUL_VAL_ 1419 Write_Output_1_Bit55_6220_37 SubIndex_6220 55-55;
SG_MUL_VAL_ 1419 Write_Output_1_Bit54_6220_36 SubIndex_6220 54-54;
SG_MUL_VAL_ 1419 Write_Output_1_Bit53_6220_35 SubIndex_6220 53-53;
SG_MUL_VAL_ 1419 Write_Output_1_Bit52_6220_34 SubIndex_6220 52-52;
SG_MUL_VAL_ 1419 Write_Output_1_Bit51_6220_33 SubIndex_6220 51-51;
SG_MUL_VAL_ 1419 Write_Output_1_Bit50_6220_32 SubIndex_6220 50-50;
SG_MUL_VAL_ 1419 Write_Output_1_Bit49_6220_31 SubIndex_6220 49-49;
SG_MUL_VAL_ 1419 Write_Output_1_Bit48_6220_30 SubIndex_6220 48-48;
SG_MUL_VAL_ 1419 Write_Output_1_Bit47_6220_2F SubIndex_6220 47-47;
SG_MUL_VAL_ 1419 Write_Output_1_Bit46_6220_2E SubIndex_6220 46-46;
SG_MUL_VAL_ 1419 Write_Output_1_Bit45_6220_2D SubIndex_6220 45-45;
SG_MUL_VAL_ 1419 Write_Output_1_Bit44_6220_2C SubIndex_6220 44-44;
SG_MUL_VAL_ 1419 Write_Output_1_Bit43_6220_2B SubIndex_6220 43-43;
SG_MUL_VAL_ 1419 Write_Output_1_Bit42_6220_2A SubIndex_6220 42-42;
SG_MUL_VAL_ 1419 Write_Output_1_Bit41_6220_29 SubIndex_6220 41-41;
SG_MUL_VAL_ 1419 Write_Output_1_Bit40_6220_28 SubIndex_6220 40-40;
SG_MUL_VAL_ 1419 Write_Output_1_Bit39_6220_27 SubIndex_6220 39-39;
SG_MUL_VAL_ 1419 Write_Output_1_Bit38_6220_26 SubIndex_6220 38-38;
SG_MUL_VAL_ 1419 Write_Output_1_Bit37_6220_25 SubIndex_6220 37-37;
SG_MUL_VAL_ 1419 Write_Output_1_Bit36_6220_24 SubIndex_6220 36-36;
SG_MUL_VAL_ 1419 Write_Output_1_Bit35_6220_23 SubIndex_6220 35-35;
SG_MUL_VAL_ 1419 Write_Output_1_Bit34_6220_22 SubIndex_6220 34-34;
SG_MUL_VAL_ 1419 Write_Output_1_Bit33_6220_21 SubIndex_6220 33-33;
SG_MUL_VAL_ 1419 Write_Output_1_Bit32_6220_20 SubIndex_6220 32-32;
SG_MUL_VAL_ 1419 Write_Output_1_Bit31_6220_1F SubIndex_6220 31-31;
SG_MUL_VAL_ 1419 Write_Output_1_Bit30_6220_1E SubIndex_6220 30-30;
SG_MUL_VAL_ 1419 Write_Output_1_Bit29_6220_1D SubIndex_6220 29-29;
SG_MUL_VAL_ 1419 Write_Output_1_Bit28_6220_1C SubIndex_6220 28-28;
SG_MUL_VAL_ 1419 Write_Output_1_Bit27_6220_1B SubIndex_6220 27-27;
SG_MUL_VAL_ 1419 Write_Output_1_Bit26_6220_1A SubIndex_6220 26-26;
SG_MUL_VAL_ 1419 Write_Output_1_Bit25_6220_19 SubIndex_6220 25-25;
SG_MUL_VAL_ 1419 Write_Output_1_Bit24_6220_18 SubIndex_6220 24-24;
SG_MUL_VAL_ 1419 Write_Output_1_Bit23_6220_17 SubIndex_6220 23-23;
SG_MUL_VAL_ 1419 Write_Output_1_Bit22_6220_16 SubIndex_6220 22-22;
SG_MUL_VAL_ 1419 Write_Output_1_Bit21_6220_15 SubIndex_6220 21-21;
SG_MUL_VAL_ 1419 Write_Output_1_Bit20_6220_14 SubIndex_6220 20-20;
SG_MUL_VAL_ 1419 Write_Output_1_Bit19_6220_13 SubIndex_6220 19-19;
SG_MUL_VAL_ 1419 Write_Output_1_Bit18_6220_12 SubIndex_6220 18-18;
SG_MUL_VAL_ 1419 Write_Output_1_Bit17_6220_11 SubIndex_6220 17-17;
SG_MUL_VAL_ 1419 Write_Output_1_Bit16_6220_10 SubIndex_6220 16-16;
SG_MUL_VAL_ 1419 Write_Output_1_Bit15_6220_0F SubIndex_6220 15-15;
SG_MUL_VAL_ 1419 Write_Output_1_Bit14_6220_0E SubIndex_6220 14-14;
SG_MUL_VAL_ 1419 Write_Output_1_Bit13_6220_0D SubIndex_6220 13-13;
SG_MUL_VAL_ 1419 Write_Output_1_Bit12_6220_0C SubIndex_6220 12-12;
SG_MUL_VAL_ 1419 Write_Output_1_Bit11_6220_0B SubIndex_6220 11-11;
SG_MUL_VAL_ 1419 Write_Output_1_Bit10_6220_0A SubIndex_6220 10-10;
SG_MUL_VAL_ 1419 Write_Output_1_Bit9_6220_09 SubIndex_6220 9-9;
SG_MUL_VAL_ 1419 Write_Output_1_Bit8_6220_08 SubIndex_6220 8-8;
SG_MUL_VAL_ 1419 Write_Output_1_Bit7_6220_07 SubIndex_6220 7-7;
SG_MUL_VAL_ 1419 Write_Output_1_Bit6_6220_06 SubIndex_6220 6-6;
SG_MUL_VAL_ 1419 Write_Output_1_Bit5_6220_05 SubIndex_6220 5-5;
SG_MUL_VAL_ 1419 Write_Output_1_Bit4_6220_04 SubIndex_6220 4-4;
SG_MUL_VAL_ 1419 Write_Output_1_Bit3_6220_03 SubIndex_6220 3-3;
SG_MUL_VAL_ 1419 Write_Output_1_Bit2_6220_02 SubIndex_6220 2-2;
SG_MUL_VAL_ 1419 Write_Output_1_Bit1_6220_01 SubIndex_6220 1-1;
SG_MUL_VAL_ 1419 NrOfObjects_6220_00 SubIndex_6220 0-0;
SG_MUL_VAL_ 1419 SubIndex_6220 Index 25120-25120;
SG_MUL_VAL_ 1419 Write_Output_8_Bit16_6200_10 SubIndex_6200 16-16;
SG_MUL_VAL_ 1419 Write_Output_8_Bit15_6200_0F SubIndex_6200 15-15;
SG_MUL_VAL_ 1419 Write_Output_8_Bit14_6200_0E SubIndex_6200 14-14;
SG_MUL_VAL_ 1419 Write_Output_8_Bit13_6200_0D SubIndex_6200 13-13;
SG_MUL_VAL_ 1419 Write_Output_8_Bit12_6200_0C SubIndex_6200 12-12;
SG_MUL_VAL_ 1419 Write_Output_8_Bit11_6200_0B SubIndex_6200 11-11;
SG_MUL_VAL_ 1419 Write_Output_8_Bit10_6200_0A SubIndex_6200 10-10;
SG_MUL_VAL_ 1419 Write_Output_8_Bit9_6200_09 SubIndex_6200 9-9;
SG_MUL_VAL_ 1419 Write_Output_8_Bit8_6200_08 SubIndex_6200 8-8;
SG_MUL_VAL_ 1419 Write_Output_8_Bit7_6200_07 SubIndex_6200 7-7;
SG_MUL_VAL_ 1419 Write_Output_8_Bit6_6200_06 SubIndex_6200 6-6;
SG_MUL_VAL_ 1419 Write_Output_8_Bit5_6200_05 SubIndex_6200 5-5;
SG_MUL_VAL_ 1419 Write_Output_8_Bit4_6200_04 SubIndex_6200 4-4;
SG_MUL_VAL_ 1419 Write_Output_8_Bit3_6200_03 SubIndex_6200 3-3;
SG_MUL_VAL_ 1419 Write_Output_8_Bit2_6200_02 SubIndex_6200 2-2;
SG_MUL_VAL_ 1419 Write_Output_8_Bit1_6200_01 SubIndex_6200 1-1;
SG_MUL_VAL_ 1419 NrOfObjects_6200_00 SubIndex_6200 0-0;
SG_MUL_VAL_ 1419 SubIndex_6200 Index 25088-25088;
SG_MUL_VAL_ 1419 Read_Input_32_Bit16_6120_10 SubIndex_6120 16-16;
SG_MUL_VAL_ 1419 Read_Input_32_Bit15_6120_0F SubIndex_6120 15-15;
SG_MUL_VAL_ 1419 Read_Input_32_Bit14_6120_0E SubIndex_6120 14-14;
SG_MUL_VAL_ 1419 Read_Input_32_Bit13_6120_0D SubIndex_6120 13-13;
SG_MUL_VAL_ 1419 Read_Input_32_Bit12_6120_0C SubIndex_6120 12-12;
SG_MUL_VAL_ 1419 Read_Input_32_Bit11_6120_0B SubIndex_6120 11-11;
SG_MUL_VAL_ 1419 Read_Input_32_Bit10_6120_0A SubIndex_6120 10-10;
SG_MUL_VAL_ 1419 Read_Input_32_Bit9_6120_09 SubIndex_6120 9-9;
SG_MUL_VAL_ 1419 Read_Input_32_Bit8_6120_08 SubIndex_6120 8-8;
SG_MUL_VAL_ 1419 Read_Input_32_Bit7_6120_07 SubIndex_6120 7-7;
SG_MUL_VAL_ 1419 Read_Input_32_Bit6_6120_06 SubIndex_6120 6-6;
SG_MUL_VAL_ 1419 Read_Input_32_Bit5_6120_05 SubIndex_6120 5-5;
SG_MUL_VAL_ 1419 Read_Input_32_Bit4_6120_04 SubIndex_6120 4-4;
SG_MUL_VAL_ 1419 Read_Input_32_Bit3_6120_03 SubIndex_6120 3-3;
SG_MUL_VAL_ 1419 Read_Input_32_Bit2_6120_02 SubIndex_6120 2-2;
SG_MUL_VAL_ 1419 Read_Input_32_Bit1_6120_01 SubIndex_6120 1-1;
SG_MUL_VAL_ 1419 NrOfObjects_6120_00 SubIndex_6120 0-0;
SG_MUL_VAL_ 1419 SubIndex_6120 Index 24864-24864;
SG_MUL_VAL_ 1419 Read_Input_16_Bit16_6100_10 SubIndex_6100 16-16;
SG_MUL_VAL_ 1419 Read_Input_16_Bit15_6100_0F SubIndex_6100 15-15;
SG_MUL_VAL_ 1419 Read_Input_16_Bit14_6100_0E SubIndex_6100 14-14;
SG_MUL_VAL_ 1419 Read_Input_16_Bit13_6100_0D SubIndex_6100 13-13;
SG_MUL_VAL_ 1419 Read_Input_16_Bit12_6100_0C SubIndex_6100 12-12;
SG_MUL_VAL_ 1419 Read_Input_16_Bit11_6100_0B SubIndex_6100 11-11;
SG_MUL_VAL_ 1419 Read_Input_16_Bit10_6100_0A SubIndex_6100 10-10;
SG_MUL_VAL_ 1419 Read_Input_16_Bit9_6100_09 SubIndex_6100 9-9;
SG_MUL_VAL_ 1419 Read_Input_16_Bit8_6100_08 SubIndex_6100 8-8;
SG_MUL_VAL_ 1419 Read_Input_16_Bit7_6100_07 SubIndex_6100 7-7;
SG_MUL_VAL_ 1419 Read_Input_16_Bit6_6100_06 SubIndex_6100 6-6;
SG_MUL_VAL_ 1419 Read_Input_16_Bit5_6100_05 SubIndex_6100 5-5;
SG_MUL_VAL_ 1419 Read_Input_16_Bit4_6100_04 SubIndex_6100 4-4;
SG_MUL_VAL_ 1419 Read_Input_16_Bit3_6100_03 SubIndex_6100 3-3;
SG_MUL_VAL_ 1419 Read_Input_16_Bit2_6100_02 SubIndex_6100 2-2;
SG_MUL_VAL_ 1419 Read_Input_16_Bit1_6100_01 SubIndex_6100 1-1;
SG_MUL_VAL_ 1419 NrOfObjects_6100_00 SubIndex_6100 0-0;
SG_MUL_VAL_ 1419 SubIndex_6100 Index 24832-24832;
SG_MUL_VAL_ 1419 Read_Input_1_Bit64_6020_40 SubIndex_6020 64-64;
SG_MUL_VAL_ 1419 Read_Input_1_Bit63_6020_3F SubIndex_6020 63-63;
SG_MUL_VAL_ 1419 Read_Input_1_Bit62_6020_3E SubIndex_6020 62-62;
SG_MUL_VAL_ 1419 Read_Input_1_Bit61_6020_3D SubIndex_6020 61-61;
SG_MUL_VAL_ 1419 Read_Input_1_Bit60_6020_3C SubIndex_6020 60-60;
SG_MUL_VAL_ 1419 Read_Input_1_Bit59_6020_3B SubIndex_6020 59-59;
SG_MUL_VAL_ 1419 Read_Input_1_Bit58_6020_3A SubIndex_6020 58-58;
SG_MUL_VAL_ 1419 Read_Input_1_Bit57_6020_39 SubIndex_6020 57-57;
SG_MUL_VAL_ 1419 Read_Input_1_Bit56_6020_38 SubIndex_6020 56-56;
SG_MUL_VAL_ 1419 Read_Input_1_Bit55_6020_37 SubIndex_6020 55-55;
SG_MUL_VAL_ 1419 Read_Input_1_Bit54_6020_36 SubIndex_6020 54-54;
SG_MUL_VAL_ 1419 Read_Input_1_Bit53_6020_35 SubIndex_6020 53-53;
SG_MUL_VAL_ 1419 Read_Input_1_Bit52_6020_34 SubIndex_6020 52-52;
SG_MUL_VAL_ 1419 Read_Input_1_Bit51_6020_33 SubIndex_6020 51-51;
SG_MUL_VAL_ 1419 Read_Input_1_Bit50_6020_32 SubIndex_6020 50-50;
SG_MUL_VAL_ 1419 Read_Input_1_Bit49_6020_31 SubIndex_6020 49-49;
SG_MUL_VAL_ 1419 Read_Input_1_Bit48_6020_30 SubIndex_6020 48-48;
SG_MUL_VAL_ 1419 Read_Input_1_Bit47_6020_2F SubIndex_6020 47-47;
SG_MUL_VAL_ 1419 Read_Input_1_Bit46_6020_2E SubIndex_6020 46-46;
SG_MUL_VAL_ 1419 Read_Input_1_Bit45_6020_2D SubIndex_6020 45-45;
SG_MUL_VAL_ 1419 Read_Input_1_Bit44_6020_2C SubIndex_6020 44-44;
SG_MUL_VAL_ 1419 Read_Input_1_Bit43_6020_2B SubIndex_6020 43-43;
SG_MUL_VAL_ 1419 Read_Input_1_Bit42_6020_2A SubIndex_6020 42-42;
SG_MUL_VAL_ 1419 Read_Input_1_Bit41_6020_29 SubIndex_6020 41-41;
SG_MUL_VAL_ 1419 Read_Input_1_Bit40_6020_28 SubIndex_6020 40-40;
SG_MUL_VAL_ 1419 Read_Input_1_Bit39_6020_27 SubIndex_6020 39-39;
SG_MUL_VAL_ 1419 Read_Input_1_Bit38_6020_26 SubIndex_6020 38-38;
SG_MUL_VAL_ 1419 Read_Input_1_Bit37_6020_25 SubIndex_6020 37-37;
SG_MUL_VAL_ 1419 Read_Input_1_Bit36_6020_24 SubIndex_6020 36-36;
SG_MUL_VAL_ 1419 Read_Input_1_Bit35_6020_23 SubIndex_6020 35-35;
SG_MUL_VAL_ 1419 Read_Input_1_Bit34_6020_22 SubIndex_6020 34-34;
SG_MUL_VAL_ 1419 Read_Input_1_Bit33_6020_21 SubIndex_6020 33-33;
SG_MUL_VAL_ 1419 Read_Input_1_Bit32_6020_20 SubIndex_6020 32-32;
SG_MUL_VAL_ 1419 Read_Input_1_Bit31_6020_1F SubIndex_6020 31-31;
SG_MUL_VAL_ 1419 Read_Input_1_Bit30_6020_1E SubIndex_6020 30-30;
SG_MUL_VAL_ 1419 Read_Input_1_Bit29_6020_1D SubIndex_6020 29-29;
SG_MUL_VAL_ 1419 Read_Input_1_Bit28_6020_1C SubIndex_6020 28-28;
SG_MUL_VAL_ 1419 Read_Input_1_Bit27_6020_1B SubIndex_6020 27-27;
SG_MUL_VAL_ 1419 Read_Input_1_Bit26_6020_1A SubIndex_6020 26-26;
SG_MUL_VAL_ 1419 Read_Input_1_Bit25_6020_19 SubIndex_6020 25-25;
SG_MUL_VAL_ 1419 Read_Input_1_Bit24_6020_18 SubIndex_6020 24-24;
SG_MUL_VAL_ 1419 Read_Input_1_Bit23_6020_17 SubIndex_6020 23-23;
SG_MUL_VAL_ 1419 Read_Input_1_Bit22_6020_16 SubIndex_6020 22-22;
SG_MUL_VAL_ 1419 Read_Input_1_Bit21_6020_15 SubIndex_6020 21-21;
SG_MUL_VAL_ 1419 Read_Input_1_Bit20_6020_14 SubIndex_6020 20-20;
SG_MUL_VAL_ 1419 Read_Input_1_Bit19_6020_13 SubIndex_6020 19-19;
SG_MUL_VAL_ 1419 Read_Input_1_Bit18_6020_12 SubIndex_6020 18-18;
SG_MUL_VAL_ 1419 Read_Input_1_Bit17_6020_11 SubIndex_6020 17-17;
SG_MUL_VAL_ 1419 Read_Input_1_Bit16_6020_10 SubIndex_6020 16-16;
SG_MUL_VAL_ 1419 Read_Input_1_Bit15_6020_0F SubIndex_6020 15-15;
SG_MUL_VAL_ 1419 Read_Input_1_Bit14_6020_0E SubIndex_6020 14-14;
SG_MUL_VAL_ 1419 Read_Input_1_Bit13_6020_0D SubIndex_6020 13-13;
SG_MUL_VAL_ 1419 Read_Input_1_Bit12_6020_0C SubIndex_6020 12-12;
SG_MUL_VAL_ 1419 Read_Input_1_Bit11_6020_0B SubIndex_6020 11-11;
SG_MUL_VAL_ 1419 Read_Input_1_Bit10_6020_0A SubIndex_6020 10-10;
SG_MUL_VAL_ 1419 Read_Input_1_Bit9_6020_09 SubIndex_6020 9-9;
SG_MUL_VAL_ 1419 Read_Input_1_Bit8_6020_08 SubIndex_6020 8-8;
SG_MUL_VAL_ 1419 Read_Input_1_Bit7_6020_07 SubIndex_6020 7-7;
SG_MUL_VAL_ 1419 Read_Input_1_Bit6_6020_06 SubIndex_6020 6-6;
SG_MUL_VAL_ 1419 Read_Input_1_Bit5_6020_05 SubIndex_6020 5-5;
SG_MUL_VAL_ 1419 Read_Input_1_Bit4_6020_04 SubIndex_6020 4-4;
SG_MUL_VAL_ 1419 Read_Input_1_Bit3_6020_03 SubIndex_6020 3-3;
SG_MUL_VAL_ 1419 Read_Input_1_Bit2_6020_02 SubIndex_6020 2-2;
SG_MUL_VAL_ 1419 Read_Input_1_Bit1_6020_01 SubIndex_6020 1-1;
SG_MUL_VAL_ 1419 NrOfObjects_6020_00 SubIndex_6020 0-0;
SG_MUL_VAL_ 1419 SubIndex_6020 Index 24608-24608;
SG_MUL_VAL_ 1419 Read_Input_8_Bit16_6000_10 SubIndex_6000 16-16;
SG_MUL_VAL_ 1419 Read_Input_8_Bit15_6000_0F SubIndex_6000 15-15;
SG_MUL_VAL_ 1419 Read_Input_8_Bit14_6000_0E SubIndex_6000 14-14;
SG_MUL_VAL_ 1419 Read_Input_8_Bit13_6000_0D SubIndex_6000 13-13;
SG_MUL_VAL_ 1419 Read_Input_8_Bit12_6000_0C SubIndex_6000 12-12;
SG_MUL_VAL_ 1419 Read_Input_8_Bit11_6000_0B SubIndex_6000 11-11;
SG_MUL_VAL_ 1419 Read_Input_8_Bit10_6000_0A SubIndex_6000 10-10;
SG_MUL_VAL_ 1419 Read_Input_8_Bit9_6000_09 SubIndex_6000 9-9;
SG_MUL_VAL_ 1419 Read_Input_8_Bit8_6000_08 SubIndex_6000 8-8;
SG_MUL_VAL_ 1419 Read_Input_8_Bit7_6000_07 SubIndex_6000 7-7;
SG_MUL_VAL_ 1419 Read_Input_8_Bit6_6000_06 SubIndex_6000 6-6;
SG_MUL_VAL_ 1419 Read_Input_8_Bit5_6000_05 SubIndex_6000 5-5;
SG_MUL_VAL_ 1419 Read_Input_8_Bit4_6000_04 SubIndex_6000 4-4;
SG_MUL_VAL_ 1419 Read_Input_8_Bit3_6000_03 SubIndex_6000 3-3;
SG_MUL_VAL_ 1419 Read_Input_8_Bit2_6000_02 SubIndex_6000 2-2;
SG_MUL_VAL_ 1419 Read_Input_8_Bit1_6000_01 SubIndex_6000 1-1;
SG_MUL_VAL_ 1419 NrOfObjects_6000_00 SubIndex_6000 0-0;
SG_MUL_VAL_ 1419 SubIndex_6000 Index 24576-24576;
SG_MUL_VAL_ 1419 NrOfObjects_2300_00 SubIndex_2300 0-0;
SG_MUL_VAL_ 1419 SubIndex_2300 Index 8960-8960;
SG_MUL_VAL_ 1419 NrOfObjects_2200_00 SubIndex_2200 0-0;
SG_MUL_VAL_ 1419 SubIndex_2200 Index 8704-8704;
SG_MUL_VAL_ 1419 NrOfMappedObjects_1A03_00 SubIndex_1A03 0-0;
SG_MUL_VAL_ 1419 SubIndex_1A03 Index 6659-6659;
SG_MUL_VAL_ 1419 NrOfMappedObjects_1A02_00 SubIndex_1A02 0-0;
SG_MUL_VAL_ 1419 SubIndex_1A02 Index 6658-6658;
SG_MUL_VAL_ 1419 NrOfMappedObjects_1A01_00 SubIndex_1A01 0-0;
SG_MUL_VAL_ 1419 SubIndex_1A01 Index 6657-6657;
SG_MUL_VAL_ 1419 NrOfMappedObjects_1A00_00 SubIndex_1A00 0-0;
SG_MUL_VAL_ 1419 SubIndex_1A00 Index 6656-6656;
SG_MUL_VAL_ 1419 EventTimer_1803_05 SubIndex_1803 5-5;
SG_MUL_VAL_ 1419 TransmissionType_1803_02 SubIndex_1803 2-2;
SG_MUL_VAL_ 1419 COB_ID_1803_01 SubIndex_1803 1-1;
SG_MUL_VAL_ 1419 NrOfEntries_1803_00 SubIndex_1803 0-0;
SG_MUL_VAL_ 1419 SubIndex_1803 Index 6147-6147;
SG_MUL_VAL_ 1419 EventTimer_1802_05 SubIndex_1802 5-5;
SG_MUL_VAL_ 1419 TransmissionType_1802_02 SubIndex_1802 2-2;
SG_MUL_VAL_ 1419 COB_ID_1802_01 SubIndex_1802 1-1;
SG_MUL_VAL_ 1419 NrOfEntries_1802_00 SubIndex_1802 0-0;
SG_MUL_VAL_ 1419 SubIndex_1802 Index 6146-6146;
SG_MUL_VAL_ 1419 EventTimer_1801_05 SubIndex_1801 5-5;
SG_MUL_VAL_ 1419 TransmissionType_1801_02 SubIndex_1801 2-2;
SG_MUL_VAL_ 1419 COB_ID_1801_01 SubIndex_1801 1-1;
SG_MUL_VAL_ 1419 NrOfEntries_1801_00 SubIndex_1801 0-0;
SG_MUL_VAL_ 1419 SubIndex_1801 Index 6145-6145;
SG_MUL_VAL_ 1419 EventTimer_1800_05 SubIndex_1800 5-5;
SG_MUL_VAL_ 1419 TransmissionType_1800_02 SubIndex_1800 2-2;
SG_MUL_VAL_ 1419 COB_ID_1800_01 SubIndex_1800 1-1;
SG_MUL_VAL_ 1419 NrOfEntries_1800_00 SubIndex_1800 0-0;
SG_MUL_VAL_ 1419 SubIndex_1800 Index 6144-6144;
SG_MUL_VAL_ 1419 NrOfMappedObjects_1603_00 SubIndex_1603 0-0;
SG_MUL_VAL_ 1419 SubIndex_1603 Index 5635-5635;
SG_MUL_VAL_ 1419 NrOfMappedObjects_1602_00 SubIndex_1602 0-0;
SG_MUL_VAL_ 1419 SubIndex_1602 Index 5634-5634;
SG_MUL_VAL_ 1419 NrOfMappedObjects_1601_00 SubIndex_1601 0-0;
SG_MUL_VAL_ 1419 SubIndex_1601 Index 5633-5633;
SG_MUL_VAL_ 1419 mappedObj2_1600_02 SubIndex_1600 2-2;
SG_MUL_VAL_ 1419 mappedObj1_1600_01 SubIndex_1600 1-1;
SG_MUL_VAL_ 1419 NrOfMappedObjects_1600_00 SubIndex_1600 0-0;
SG_MUL_VAL_ 1419 SubIndex_1600 Index 5632-5632;
SG_MUL_VAL_ 1419 TransmissionType_1403_02 SubIndex_1403 2-2;
SG_MUL_VAL_ 1419 COB_ID_1403_01 SubIndex_1403 1-1;
SG_MUL_VAL_ 1419 NrOfEntries_1403_00 SubIndex_1403 0-0;
SG_MUL_VAL_ 1419 SubIndex_1403 Index 5123-5123;
SG_MUL_VAL_ 1419 TransmissionType_1402_02 SubIndex_1402 2-2;
SG_MUL_VAL_ 1419 COB_ID_1402_01 SubIndex_1402 1-1;
SG_MUL_VAL_ 1419 NrOfEntries_1402_00 SubIndex_1402 0-0;
SG_MUL_VAL_ 1419 SubIndex_1402 Index 5122-5122;
SG_MUL_VAL_ 1419 TransmissionType_1401_02 SubIndex_1401 2-2;
SG_MUL_VAL_ 1419 COB_ID_1401_01 SubIndex_1401 1-1;
SG_MUL_VAL_ 1419 NrOfEntries_1401_00 SubIndex_1401 0-0;
SG_MUL_VAL_ 1419 SubIndex_1401 Index 5121-5121;
SG_MUL_VAL_ 1419 TransmissionType_1400_02 SubIndex_1400 2-2;
SG_MUL_VAL_ 1419 COB_ID_1400_01 SubIndex_1400 1-1;
SG_MUL_VAL_ 1419 NrOfEntries_1400_00 SubIndex_1400 0-0;
SG_MUL_VAL_ 1419 SubIndex_1400 Index 5120-5120;
SG_MUL_VAL_ 1419 Serial_number_1018_04 SubIndex_1018 4-4;
SG_MUL_VAL_ 1419 Revision_number_1018_03 SubIndex_1018 3-3;
SG_MUL_VAL_ 1419 Product_Code_1018_02 SubIndex_1018 2-2;
SG_MUL_VAL_ 1419 Vendor_Id_1018_01 SubIndex_1018 1-1;
SG_MUL_VAL_ 1419 number_of_entries_1018_00 SubIndex_1018 0-0;
SG_MUL_VAL_ 1419 SubIndex_1018 Index 4120-4120;
SG_MUL_VAL_ 1419 Producer_Heartbeat_Time_1017 SubIndex_1017 0-0;
SG_MUL_VAL_ 1419 SubIndex_1017 Index 4119-4119;
SG_MUL_VAL_ 1419 Consumer_Heartbeat_Time16_1016_1 SubIndex_1016 16-16;
SG_MUL_VAL_ 1419 Consumer_Heartbeat_Time15_1016_0 SubIndex_1016 15-15;
SG_MUL_VAL_ 1419 Consumer_Heartbeat_Time14_1016_0 SubIndex_1016 14-14;
SG_MUL_VAL_ 1419 Consumer_Heartbeat_Time13_1016_0 SubIndex_1016 13-13;
SG_MUL_VAL_ 1419 Consumer_Heartbeat_Time12_1016_0 SubIndex_1016 12-12;
SG_MUL_VAL_ 1419 Consumer_Heartbeat_Time11_1016_0 SubIndex_1016 11-11;
SG_MUL_VAL_ 1419 Consumer_Heartbeat_Time10_1016_0 SubIndex_1016 10-10;
SG_MUL_VAL_ 1419 Consumer_Heartbeat_Time9_1016_09 SubIndex_1016 9-9;
SG_MUL_VAL_ 1419 Consumer_Heartbeat_Time8_1016_08 SubIndex_1016 8-8;
SG_MUL_VAL_ 1419 Consumer_Heartbeat_Time7_1016_07 SubIndex_1016 7-7;
SG_MUL_VAL_ 1419 Consumer_Heartbeat_Time6_1016_06 SubIndex_1016 6-6;
SG_MUL_VAL_ 1419 Consumer_Heartbeat_Time5_1016_05 SubIndex_1016 5-5;
SG_MUL_VAL_ 1419 Consumer_Heartbeat_Time4_1016_04 SubIndex_1016 4-4;
SG_MUL_VAL_ 1419 Consumer_Heartbeat_Time3_1016_03 SubIndex_1016 3-3;
SG_MUL_VAL_ 1419 Consumer_Heartbeat_Time2_1016_02 SubIndex_1016 2-2;
SG_MUL_VAL_ 1419 Consumer_Heartbeat_Time1_1016_01 SubIndex_1016 1-1;
SG_MUL_VAL_ 1419 NrOfObjects_1016_00 SubIndex_1016 0-0;
SG_MUL_VAL_ 1419 SubIndex_1016 Index 4118-4118;
SG_MUL_VAL_ 1419 COB_ID_EMCY_1014 SubIndex_1014 0-0;
SG_MUL_VAL_ 1419 SubIndex_1014 Index 4116-4116;
SG_MUL_VAL_ 1419 Restore_all_Default_Parameters_1 SubIndex_1011 1-1;
SG_MUL_VAL_ 1419 Number_of_Entries_1011_00 SubIndex_1011 0-0;
SG_MUL_VAL_ 1419 SubIndex_1011 Index 4113-4113;
SG_MUL_VAL_ 1419 Save_all_Parameters_1010_01 SubIndex_1010 1-1;
SG_MUL_VAL_ 1419 Number_of_Entries_1010_00 SubIndex_1010 0-0;
SG_MUL_VAL_ 1419 SubIndex_1010 Index 4112-4112;
SG_MUL_VAL_ 1419 Life_Time_Factor_100D SubIndex_100D 0-0;
SG_MUL_VAL_ 1419 SubIndex_100D Index 4109-4109;
SG_MUL_VAL_ 1419 Guard_Time_100C SubIndex_100C 0-0;
SG_MUL_VAL_ 1419 SubIndex_100C Index 4108-4108;
SG_MUL_VAL_ 1419 Synchronous_Window_Length_1007 SubIndex_1007 0-0;
SG_MUL_VAL_ 1419 SubIndex_1007 Index 4103-4103;
SG_MUL_VAL_ 1419 Communication_Cycle_Period_1006 SubIndex_1006 0-0;
SG_MUL_VAL_ 1419 SubIndex_1006 Index 4102-4102;
SG_MUL_VAL_ 1419 COB_ID_SYNC_1005 SubIndex_1005 0-0;
SG_MUL_VAL_ 1419 SubIndex_1005 Index 4101-4101;
SG_MUL_VAL_ 1419 Standard_error_field_1003_09 SubIndex_1003 9-9;
SG_MUL_VAL_ 1419 Standard_error_field_1003_08 SubIndex_1003 8-8;
SG_MUL_VAL_ 1419 Standard_error_field_1003_07 SubIndex_1003 7-7;
SG_MUL_VAL_ 1419 Standard_error_field_1003_06 SubIndex_1003 6-6;
SG_MUL_VAL_ 1419 Standard_error_field_1003_05 SubIndex_1003 5-5;
SG_MUL_VAL_ 1419 Standard_error_field_1003_04 SubIndex_1003 4-4;
SG_MUL_VAL_ 1419 Standard_error_field_1003_03 SubIndex_1003 3-3;
SG_MUL_VAL_ 1419 Standard_error_field_1003_02 SubIndex_1003 2-2;
SG_MUL_VAL_ 1419 Standard_error_field_1003_01 SubIndex_1003 1-1;
SG_MUL_VAL_ 1419 Number_of_Errors_1003_00 SubIndex_1003 0-0;
SG_MUL_VAL_ 1419 SubIndex_1003 Index 4099-4099;
SG_MUL_VAL_ 1419 Error_Register_1001 SubIndex_1001 0-0;
SG_MUL_VAL_ 1419 SubIndex_1001 Index 4097-4097;
SG_MUL_VAL_ 1419 Device_Type_1000 SubIndex_1000 0-0;
SG_MUL_VAL_ 1419 SubIndex_1000 Index 4096-4096;
SG_MUL_VAL_ 1419 Index TransferType 1-1;
SG_MUL_VAL_ 1419 TransferType SCS 1-2;
SG_MUL_VAL_ 1419 NotUsedBytes SCS 1-2;
SG_MUL_VAL_ 1419 SizeIndicator SCS 1-2;
SG_MUL_VAL_ 1547 Write_Output_32_Bit16_6320_10 SubIndex_6320 16-16;
SG_MUL_VAL_ 1547 Write_Output_32_Bit15_6320_0F SubIndex_6320 15-15;
SG_MUL_VAL_ 1547 Write_Output_32_Bit14_6320_0E SubIndex_6320 14-14;
SG_MUL_VAL_ 1547 Write_Output_32_Bit13_6320_0D SubIndex_6320 13-13;
SG_MUL_VAL_ 1547 Write_Output_32_Bit12_6320_0C SubIndex_6320 12-12;
SG_MUL_VAL_ 1547 Write_Output_32_Bit11_6320_0B SubIndex_6320 11-11;
SG_MUL_VAL_ 1547 Write_Output_32_Bit10_6320_0A SubIndex_6320 10-10;
SG_MUL_VAL_ 1547 Write_Output_32_Bit9_6320_09 SubIndex_6320 9-9;
SG_MUL_VAL_ 1547 Write_Output_32_Bit8_6320_08 SubIndex_6320 8-8;
SG_MUL_VAL_ 1547 Write_Output_32_Bit7_6320_07 SubIndex_6320 7-7;
SG_MUL_VAL_ 1547 Write_Output_32_Bit6_6320_06 SubIndex_6320 6-6;
SG_MUL_VAL_ 1547 Write_Output_32_Bit5_6320_05 SubIndex_6320 5-5;
SG_MUL_VAL_ 1547 Write_Output_32_Bit4_6320_04 SubIndex_6320 4-4;
SG_MUL_VAL_ 1547 Write_Output_32_Bit3_6320_03 SubIndex_6320 3-3;
SG_MUL_VAL_ 1547 Write_Output_32_Bit2_6320_02 SubIndex_6320 2-2;
SG_MUL_VAL_ 1547 Write_Output_32_Bit1_6320_01 SubIndex_6320 1-1;
SG_MUL_VAL_ 1547 NrOfObjects_6320_00 SubIndex_6320 0-0;
SG_MUL_VAL_ 1547 SubIndex_6320 Index 25376-25376;
SG_MUL_VAL_ 1547 Write_Output_16_Bit16_6300_10 SubIndex_6300 16-16;
SG_MUL_VAL_ 1547 Write_Output_16_Bit15_6300_0F SubIndex_6300 15-15;
SG_MUL_VAL_ 1547 Write_Output_16_Bit14_6300_0E SubIndex_6300 14-14;
SG_MUL_VAL_ 1547 Write_Output_16_Bit13_6300_0D SubIndex_6300 13-13;
SG_MUL_VAL_ 1547 Write_Output_16_Bit12_6300_0C SubIndex_6300 12-12;
SG_MUL_VAL_ 1547 Write_Output_16_Bit11_6300_0B SubIndex_6300 11-11;
SG_MUL_VAL_ 1547 Write_Output_16_Bit10_6300_0A SubIndex_6300 10-10;
SG_MUL_VAL_ 1547 Write_Output_16_Bit9_6300_09 SubIndex_6300 9-9;
SG_MUL_VAL_ 1547 Write_Output_16_Bit8_6300_08 SubIndex_6300 8-8;
SG_MUL_VAL_ 1547 Write_Output_16_Bit7_6300_07 SubIndex_6300 7-7;
SG_MUL_VAL_ 1547 Write_Output_16_Bit6_6300_06 SubIndex_6300 6-6;
SG_MUL_VAL_ 1547 Write_Output_16_Bit5_6300_05 SubIndex_6300 5-5;
SG_MUL_VAL_ 1547 Write_Output_16_Bit4_6300_04 SubIndex_6300 4-4;
SG_MUL_VAL_ 1547 Write_Output_16_Bit3_6300_03 SubIndex_6300 3-3;
SG_MUL_VAL_ 1547 Write_Output_16_Bit2_6300_02 SubIndex_6300 2-2;
SG_MUL_VAL_ 1547 Write_Output_16_Bit1_6300_01 SubIndex_6300 1-1;
SG_MUL_VAL_ 1547 NrOfObjects_6300_00 SubIndex_6300 0-0;
SG_MUL_VAL_ 1547 SubIndex_6300 Index 25344-25344;
SG_MUL_VAL_ 1547 Write_Output_1_Bit64_6220_40 SubIndex_6220 64-64;
SG_MUL_VAL_ 1547 Write_Output_1_Bit63_6220_3F SubIndex_6220 63-63;
SG_MUL_VAL_ 1547 Write_Output_1_Bit62_6220_3E SubIndex_6220 62-62;
SG_MUL_VAL_ 1547 Write_Output_1_Bit61_6220_3D SubIndex_6220 61-61;
SG_MUL_VAL_ 1547 Write_Output_1_Bit60_6220_3C SubIndex_6220 60-60;
SG_MUL_VAL_ 1547 Write_Output_1_Bit59_6220_3B SubIndex_6220 59-59;
SG_MUL_VAL_ 1547 Write_Output_1_Bit58_6220_3A SubIndex_6220 58-58;
SG_MUL_VAL_ 1547 Write_Output_1_Bit57_6220_39 SubIndex_6220 57-57;
SG_MUL_VAL_ 1547 Write_Output_1_Bit56_6220_38 SubIndex_6220 56-56;
SG_MUL_VAL_ 1547 Write_Output_1_Bit55_6220_37 SubIndex_6220 55-55;
SG_MUL_VAL_ 1547 Write_Output_1_Bit54_6220_36 SubIndex_6220 54-54;
SG_MUL_VAL_ 1547 Write_Output_1_Bit53_6220_35 SubIndex_6220 53-53;
SG_MUL_VAL_ 1547 Write_Output_1_Bit52_6220_34 SubIndex_6220 52-52;
SG_MUL_VAL_ 1547 Write_Output_1_Bit51_6220_33 SubIndex_6220 51-51;
SG_MUL_VAL_ 1547 Write_Output_1_Bit50_6220_32 SubIndex_6220 50-50;
SG_MUL_VAL_ 1547 Write_Output_1_Bit49_6220_31 SubIndex_6220 49-49;
SG_MUL_VAL_ 1547 Write_Output_1_Bit48_6220_30 SubIndex_6220 48-48;
SG_MUL_VAL_ 1547 Write_Output_1_Bit47_6220_2F SubIndex_6220 47-47;
SG_MUL_VAL_ 1547 Write_Output_1_Bit46_6220_2E SubIndex_6220 46-46;
SG_MUL_VAL_ 1547 Write_Output_1_Bit45_6220_2D SubIndex_6220 45-45;
SG_MUL_VAL_ 1547 Write_Output_1_Bit44_6220_2C SubIndex_6220 44-44;
SG_MUL_VAL_ 1547 Write_Output_1_Bit43_6220_2B SubIndex_6220 43-43;
SG_MUL_VAL_ 1547 Write_Output_1_Bit42_6220_2A SubIndex_6220 42-42;
SG_MUL_VAL_ 1547 Write_Output_1_Bit41_6220_29 SubIndex_6220 41-41;
SG_MUL_VAL_ 1547 Write_Output_1_Bit40_6220_28 SubIndex_6220 40-40;
SG_MUL_VAL_ 1547 Write_Output_1_Bit39_6220_27 SubIndex_6220 39-39;
SG_MUL_VAL_ 1547 Write_Output_1_Bit38_6220_26 SubIndex_6220 38-38;
SG_MUL_VAL_ 1547 Write_Output_1_Bit37_6220_25 SubIndex_6220 37-37;
SG_MUL_VAL_ 1547 Write_Output_1_Bit36_6220_24 SubIndex_6220 36-36;
SG_MUL_VAL_ 1547 Write_Output_1_Bit35_6220_23 SubIndex_6220 35-35;
SG_MUL_VAL_ 1547 Write_Output_1_Bit34_6220_22 SubIndex_6220 34-34;
SG_MUL_VAL_ 1547 Write_Output_1_Bit33_6220_21 SubIndex_6220 33-33;
SG_MUL_VAL_ 1547 Write_Output_1_Bit32_6220_20 SubIndex_6220 32-32;
SG_MUL_VAL_ 1547 Write_Output_1_Bit31_6220_1F SubIndex_6220 31-31;
SG_MUL_VAL_ 1547 Write_Output_1_Bit30_6220_1E SubIndex_6220 30-30;
SG_MUL_VAL_ 1547 Write_Output_1_Bit29_6220_1D SubIndex_6220 29-29;
SG_MUL_VAL_ 1547 Write_Output_1_Bit28_6220_1C SubIndex_6220 28-28;
SG_MUL_VAL_ 1547 Write_Output_1_Bit27_6220_1B SubIndex_6220 27-27;
SG_MUL_VAL_ 1547 Write_Output_1_Bit26_6220_1A SubIndex_6220 26-26;
SG_MUL_VAL_ 1547 Write_Output_1_Bit25_6220_19 SubIndex_6220 25-25;
SG_MUL_VAL_ 1547 Write_Output_1_Bit24_6220_18 SubIndex_6220 24-24;
SG_MUL_VAL_ 1547 Write_Output_1_Bit23_6220_17 SubIndex_6220 23-23;
SG_MUL_VAL_ 1547 Write_Output_1_Bit22_6220_16 SubIndex_6220 22-22;
SG_MUL_VAL_ 1547 Write_Output_1_Bit21_6220_15 SubIndex_6220 21-21;
SG_MUL_VAL_ 1547 Write_Output_1_Bit20_6220_14 SubIndex_6220 20-20;
SG_MUL_VAL_ 1547 Write_Output_1_Bit19_6220_13 SubIndex_6220 19-19;
SG_MUL_VAL_ 1547 Write_Output_1_Bit18_6220_12 SubIndex_6220 18-18;
SG_MUL_VAL_ 1547 Write_Output_1_Bit17_6220_11 SubIndex_6220 17-17;
SG_MUL_VAL_ 1547 Write_Output_1_Bit16_6220_10 SubIndex_6220 16-16;
SG_MUL_VAL_ 1547 Write_Output_1_Bit15_6220_0F SubIndex_6220 15-15;
SG_MUL_VAL_ 1547 Write_Output_1_Bit14_6220_0E SubIndex_6220 14-14;
SG_MUL_VAL_ 1547 Write_Output_1_Bit13_6220_0D SubIndex_6220 13-13;
SG_MUL_VAL_ 1547 Write_Output_1_Bit12_6220_0C SubIndex_6220 12-12;
SG_MUL_VAL_ 1547 Write_Output_1_Bit11_6220_0B SubIndex_6220 11-11;
SG_MUL_VAL_ 1547 Write_Output_1_Bit10_6220_0A SubIndex_6220 10-10;
SG_MUL_VAL_ 1547 Write_Output_1_Bit9_6220_09 SubIndex_6220 9-9;
SG_MUL_VAL_ 1547 Write_Output_1_Bit8_6220_08 SubIndex_6220 8-8;
SG_MUL_VAL_ 1547 Write_Output_1_Bit7_6220_07 SubIndex_6220 7-7;
SG_MUL_VAL_ 1547 Write_Output_1_Bit6_6220_06 SubIndex_6220 6-6;
SG_MUL_VAL_ 1547 Write_Output_1_Bit5_6220_05 SubIndex_6220 5-5;
SG_MUL_VAL_ 1547 Write_Output_1_Bit4_6220_04 SubIndex_6220 4-4;
SG_MUL_VAL_ 1547 Write_Output_1_Bit3_6220_03 SubIndex_6220 3-3;
SG_MUL_VAL_ 1547 Write_Output_1_Bit2_6220_02 SubIndex_6220 2-2;
SG_MUL_VAL_ 1547 Write_Output_1_Bit1_6220_01 SubIndex_6220 1-1;
SG_MUL_VAL_ 1547 NrOfObjects_6220_00 SubIndex_6220 0-0;
SG_MUL_VAL_ 1547 SubIndex_6220 Index 25120-25120;
SG_MUL_VAL_ 1547 Write_Output_8_Bit16_6200_10 SubIndex_6200 16-16;
SG_MUL_VAL_ 1547 Write_Output_8_Bit15_6200_0F SubIndex_6200 15-15;
SG_MUL_VAL_ 1547 Write_Output_8_Bit14_6200_0E SubIndex_6200 14-14;
SG_MUL_VAL_ 1547 Write_Output_8_Bit13_6200_0D SubIndex_6200 13-13;
SG_MUL_VAL_ 1547 Write_Output_8_Bit12_6200_0C SubIndex_6200 12-12;
SG_MUL_VAL_ 1547 Write_Output_8_Bit11_6200_0B SubIndex_6200 11-11;
SG_MUL_VAL_ 1547 Write_Output_8_Bit10_6200_0A SubIndex_6200 10-10;
SG_MUL_VAL_ 1547 Write_Output_8_Bit9_6200_09 SubIndex_6200 9-9;
SG_MUL_VAL_ 1547 Write_Output_8_Bit8_6200_08 SubIndex_6200 8-8;
SG_MUL_VAL_ 1547 Write_Output_8_Bit7_6200_07 SubIndex_6200 7-7;
SG_MUL_VAL_ 1547 Write_Output_8_Bit6_6200_06 SubIndex_6200 6-6;
SG_MUL_VAL_ 1547 Write_Output_8_Bit5_6200_05 SubIndex_6200 5-5;
SG_MUL_VAL_ 1547 Write_Output_8_Bit4_6200_04 SubIndex_6200 4-4;
SG_MUL_VAL_ 1547 Write_Output_8_Bit3_6200_03 SubIndex_6200 3-3;
SG_MUL_VAL_ 1547 Write_Output_8_Bit2_6200_02 SubIndex_6200 2-2;
SG_MUL_VAL_ 1547 Write_Output_8_Bit1_6200_01 SubIndex_6200 1-1;
SG_MUL_VAL_ 1547 NrOfObjects_6200_00 SubIndex_6200 0-0;
SG_MUL_VAL_ 1547 SubIndex_6200 Index 25088-25088;
SG_MUL_VAL_ 1547 Read_Input_32_Bit16_6120_10 SubIndex_6120 16-16;
SG_MUL_VAL_ 1547 Read_Input_32_Bit15_6120_0F SubIndex_6120 15-15;
SG_MUL_VAL_ 1547 Read_Input_32_Bit14_6120_0E SubIndex_6120 14-14;
SG_MUL_VAL_ 1547 Read_Input_32_Bit13_6120_0D SubIndex_6120 13-13;
SG_MUL_VAL_ 1547 Read_Input_32_Bit12_6120_0C SubIndex_6120 12-12;
SG_MUL_VAL_ 1547 Read_Input_32_Bit11_6120_0B SubIndex_6120 11-11;
SG_MUL_VAL_ 1547 Read_Input_32_Bit10_6120_0A SubIndex_6120 10-10;
SG_MUL_VAL_ 1547 Read_Input_32_Bit9_6120_09 SubIndex_6120 9-9;
SG_MUL_VAL_ 1547 Read_Input_32_Bit8_6120_08 SubIndex_6120 8-8;
SG_MUL_VAL_ 1547 Read_Input_32_Bit7_6120_07 SubIndex_6120 7-7;
SG_MUL_VAL_ 1547 Read_Input_32_Bit6_6120_06 SubIndex_6120 6-6;
SG_MUL_VAL_ 1547 Read_Input_32_Bit5_6120_05 SubIndex_6120 5-5;
SG_MUL_VAL_ 1547 Read_Input_32_Bit4_6120_04 SubIndex_6120 4-4;
SG_MUL_VAL_ 1547 Read_Input_32_Bit3_6120_03 SubIndex_6120 3-3;
SG_MUL_VAL_ 1547 Read_Input_32_Bit2_6120_02 SubIndex_6120 2-2;
SG_MUL_VAL_ 1547 Read_Input_32_Bit1_6120_01 SubIndex_6120 1-1;
SG_MUL_VAL_ 1547 NrOfObjects_6120_00 SubIndex_6120 0-0;
SG_MUL_VAL_ 1547 SubIndex_6120 Index 24864-24864;
SG_MUL_VAL_ 1547 Read_Input_16_Bit16_6100_10 SubIndex_6100 16-16;
SG_MUL_VAL_ 1547 Read_Input_16_Bit15_6100_0F SubIndex_6100 15-15;
SG_MUL_VAL_ 1547 Read_Input_16_Bit14_6100_0E SubIndex_6100 14-14;
SG_MUL_VAL_ 1547 Read_Input_16_Bit13_6100_0D SubIndex_6100 13-13;
SG_MUL_VAL_ 1547 Read_Input_16_Bit12_6100_0C SubIndex_6100 12-12;
SG_MUL_VAL_ 1547 Read_Input_16_Bit11_6100_0B SubIndex_6100 11-11;
SG_MUL_VAL_ 1547 Read_Input_16_Bit10_6100_0A SubIndex_6100 10-10;
SG_MUL_VAL_ 1547 Read_Input_16_Bit9_6100_09 SubIndex_6100 9-9;
SG_MUL_VAL_ 1547 Read_Input_16_Bit8_6100_08 SubIndex_6100 8-8;
SG_MUL_VAL_ 1547 Read_Input_16_Bit7_6100_07 SubIndex_6100 7-7;
SG_MUL_VAL_ 1547 Read_Input_16_Bit6_6100_06 SubIndex_6100 6-6;
SG_MUL_VAL_ 1547 Read_Input_16_Bit5_6100_05 SubIndex_6100 5-5;
SG_MUL_VAL_ 1547 Read_Input_16_Bit4_6100_04 SubIndex_6100 4-4;
SG_MUL_VAL_ 1547 Read_Input_16_Bit3_6100_03 SubIndex_6100 3-3;
SG_MUL_VAL_ 1547 Read_Input_16_Bit2_6100_02 SubIndex_6100 2-2;
SG_MUL_VAL_ 1547 Read_Input_16_Bit1_6100_01 SubIndex_6100 1-1;
SG_MUL_VAL_ 1547 NrOfObjects_6100_00 SubIndex_6100 0-0;
SG_MUL_VAL_ 1547 SubIndex_6100 Index 24832-24832;
SG_MUL_VAL_ 1547 Read_Input_1_Bit64_6020_40 SubIndex_6020 64-64;
SG_MUL_VAL_ 1547 Read_Input_1_Bit63_6020_3F SubIndex_6020 63-63;
SG_MUL_VAL_ 1547 Read_Input_1_Bit62_6020_3E SubIndex_6020 62-62;
SG_MUL_VAL_ 1547 Read_Input_1_Bit61_6020_3D SubIndex_6020 61-61;
SG_MUL_VAL_ 1547 Read_Input_1_Bit60_6020_3C SubIndex_6020 60-60;
SG_MUL_VAL_ 1547 Read_Input_1_Bit59_6020_3B SubIndex_6020 59-59;
SG_MUL_VAL_ 1547 Read_Input_1_Bit58_6020_3A SubIndex_6020 58-58;
SG_MUL_VAL_ 1547 Read_Input_1_Bit57_6020_39 SubIndex_6020 57-57;
SG_MUL_VAL_ 1547 Read_Input_1_Bit56_6020_38 SubIndex_6020 56-56;
SG_MUL_VAL_ 1547 Read_Input_1_Bit55_6020_37 SubIndex_6020 55-55;
SG_MUL_VAL_ 1547 Read_Input_1_Bit54_6020_36 SubIndex_6020 54-54;
SG_MUL_VAL_ 1547 Read_Input_1_Bit53_6020_35 SubIndex_6020 53-53;
SG_MUL_VAL_ 1547 Read_Input_1_Bit52_6020_34 SubIndex_6020 52-52;
SG_MUL_VAL_ 1547 Read_Input_1_Bit51_6020_33 SubIndex_6020 51-51;
SG_MUL_VAL_ 1547 Read_Input_1_Bit50_6020_32 SubIndex_6020 50-50;
SG_MUL_VAL_ 1547 Read_Input_1_Bit49_6020_31 SubIndex_6020 49-49;
SG_MUL_VAL_ 1547 Read_Input_1_Bit48_6020_30 SubIndex_6020 48-48;
SG_MUL_VAL_ 1547 Read_Input_1_Bit47_6020_2F SubIndex_6020 47-47;
SG_MUL_VAL_ 1547 Read_Input_1_Bit46_6020_2E SubIndex_6020 46-46;
SG_MUL_VAL_ 1547 Read_Input_1_Bit45_6020_2D SubIndex_6020 45-45;
SG_MUL_VAL_ 1547 Read_Input_1_Bit44_6020_2C SubIndex_6020 44-44;
SG_MUL_VAL_ 1547 Read_Input_1_Bit43_6020_2B SubIndex_6020 43-43;
SG_MUL_VAL_ 1547 Read_Input_1_Bit42_6020_2A SubIndex_6020 42-42;
SG_MUL_VAL_ 1547 Read_Input_1_Bit41_6020_29 SubIndex_6020 41-41;
SG_MUL_VAL_ 1547 Read_Input_1_Bit40_6020_28 SubIndex_6020 40-40;
SG_MUL_VAL_ 1547 Read_Input_1_Bit39_6020_27 SubIndex_6020 39-39;
SG_MUL_VAL_ 1547 Read_Input_1_Bit38_6020_26 SubIndex_6020 38-38;
SG_MUL_VAL_ 1547 Read_Input_1_Bit37_6020_25 SubIndex_6020 37-37;
SG_MUL_VAL_ 1547 Read_Input_1_Bit36_6020_24 SubIndex_6020 36-36;
SG_MUL_VAL_ 1547 Read_Input_1_Bit35_6020_23 SubIndex_6020 35-35;
SG_MUL_VAL_ 1547 Read_Input_1_Bit34_6020_22 SubIndex_6020 34-34;
SG_MUL_VAL_ 1547 Read_Input_1_Bit33_6020_21 SubIndex_6020 33-33;
SG_MUL_VAL_ 1547 Read_Input_1_Bit32_6020_20 SubIndex_6020 32-32;
SG_MUL_VAL_ 1547 Read_Input_1_Bit31_6020_1F SubIndex_6020 31-31;
SG_MUL_VAL_ 1547 Read_Input_1_Bit30_6020_1E SubIndex_6020 30-30;
SG_MUL_VAL_ 1547 Read_Input_1_Bit29_6020_1D SubIndex_6020 29-29;
SG_MUL_VAL_ 1547 Read_Input_1_Bit28_6020_1C SubIndex_6020 28-28;
SG_MUL_VAL_ 1547 Read_Input_1_Bit27_6020_1B SubIndex_6020 27-27;
SG_MUL_VAL_ 1547 Read_Input_1_Bit26_6020_1A SubIndex_6020 26-26;
SG_MUL_VAL_ 1547 Read_Input_1_Bit25_6020_19 SubIndex_6020 25-25;
SG_MUL_VAL_ 1547 Read_Input_1_Bit24_6020_18 SubIndex_6020 24-24;
SG_MUL_VAL_ 1547 Read_Input_1_Bit23_6020_17 SubIndex_6020 23-23;
SG_MUL_VAL_ 1547 Read_Input_1_Bit22_6020_16 SubIndex_6020 22-22;
SG_MUL_VAL_ 1547 Read_Input_1_Bit21_6020_15 SubIndex_6020 21-21;
SG_MUL_VAL_ 1547 Read_Input_1_Bit20_6020_14 SubIndex_6020 20-20;
SG_MUL_VAL_ 1547 Read_Input_1_Bit19_6020_13 SubIndex_6020 19-19;
SG_MUL_VAL_ 1547 Read_Input_1_Bit18_6020_12 SubIndex_6020 18-18;
SG_MUL_VAL_ 1547 Read_Input_1_Bit17_6020_11 SubIndex_6020 17-17;
SG_MUL_VAL_ 1547 Read_Input_1_Bit16_6020_10 SubIndex_6020 16-16;
SG_MUL_VAL_ 1547 Read_Input_1_Bit15_6020_0F SubIndex_6020 15-15;
SG_MUL_VAL_ 1547 Read_Input_1_Bit14_6020_0E SubIndex_6020 14-14;
SG_MUL_VAL_ 1547 Read_Input_1_Bit13_6020_0D SubIndex_6020 13-13;
SG_MUL_VAL_ 1547 Read_Input_1_Bit12_6020_0C SubIndex_6020 12-12;
SG_MUL_VAL_ 1547 Read_Input_1_Bit11_6020_0B SubIndex_6020 11-11;
SG_MUL_VAL_ 1547 Read_Input_1_Bit10_6020_0A SubIndex_6020 10-10;
SG_MUL_VAL_ 1547 Read_Input_1_Bit9_6020_09 SubIndex_6020 9-9;
SG_MUL_VAL_ 1547 Read_Input_1_Bit8_6020_08 SubIndex_6020 8-8;
SG_MUL_VAL_ 1547 Read_Input_1_Bit7_6020_07 SubIndex_6020 7-7;
SG_MUL_VAL_ 1547 Read_Input_1_Bit6_6020_06 SubIndex_6020 6-6;
SG_MUL_VAL_ 1547 Read_Input_1_Bit5_6020_05 SubIndex_6020 5-5;
SG_MUL_VAL_ 1547 Read_Input_1_Bit4_6020_04 SubIndex_6020 4-4;
SG_MUL_VAL_ 1547 Read_Input_1_Bit3_6020_03 SubIndex_6020 3-3;
SG_MUL_VAL_ 1547 Read_Input_1_Bit2_6020_02 SubIndex_6020 2-2;
SG_MUL_VAL_ 1547 Read_Input_1_Bit1_6020_01 SubIndex_6020 1-1;
SG_MUL_VAL_ 1547 NrOfObjects_6020_00 SubIndex_6020 0-0;
SG_MUL_VAL_ 1547 SubIndex_6020 Index 24608-24608;
SG_MUL_VAL_ 1547 Read_Input_8_Bit16_6000_10 SubIndex_6000 16-16;
SG_MUL_VAL_ 1547 Read_Input_8_Bit15_6000_0F SubIndex_6000 15-15;
SG_MUL_VAL_ 1547 Read_Input_8_Bit14_6000_0E SubIndex_6000 14-14;
SG_MUL_VAL_ 1547 Read_Input_8_Bit13_6000_0D SubIndex_6000 13-13;
SG_MUL_VAL_ 1547 Read_Input_8_Bit12_6000_0C SubIndex_6000 12-12;
SG_MUL_VAL_ 1547 Read_Input_8_Bit11_6000_0B SubIndex_6000 11-11;
SG_MUL_VAL_ 1547 Read_Input_8_Bit10_6000_0A SubIndex_6000 10-10;
SG_MUL_VAL_ 1547 Read_Input_8_Bit9_6000_09 SubIndex_6000 9-9;
SG_MUL_VAL_ 1547 Read_Input_8_Bit8_6000_08 SubIndex_6000 8-8;
SG_MUL_VAL_ 1547 Read_Input_8_Bit7_6000_07 SubIndex_6000 7-7;
SG_MUL_VAL_ 1547 Read_Input_8_Bit6_6000_06 SubIndex_6000 6-6;
SG_MUL_VAL_ 1547 Read_Input_8_Bit5_6000_05 SubIndex_6000 5-5;
SG_MUL_VAL_ 1547 Read_Input_8_Bit4_6000_04 SubIndex_6000 4-4;
SG_MUL_VAL_ 1547 Read_Input_8_Bit3_6000_03 SubIndex_6000 3-3;
SG_MUL_VAL_ 1547 Read_Input_8_Bit2_6000_02 SubIndex_6000 2-2;
SG_MUL_VAL_ 1547 Read_Input_8_Bit1_6000_01 SubIndex_6000 1-1;
SG_MUL_VAL_ 1547 NrOfObjects_6000_00 SubIndex_6000 0-0;
SG_MUL_VAL_ 1547 SubIndex_6000 Index 24576-24576;
SG_MUL_VAL_ 1547 NrOfObjects_2300_00 SubIndex_2300 0-0;
SG_MUL_VAL_ 1547 SubIndex_2300 Index 8960-8960;
SG_MUL_VAL_ 1547 NrOfObjects_2200_00 SubIndex_2200 0-0;
SG_MUL_VAL_ 1547 SubIndex_2200 Index 8704-8704;
SG_MUL_VAL_ 1547 NrOfMappedObjects_1A03_00 SubIndex_1A03 0-0;
SG_MUL_VAL_ 1547 SubIndex_1A03 Index 6659-6659;
SG_MUL_VAL_ 1547 NrOfMappedObjects_1A02_00 SubIndex_1A02 0-0;
SG_MUL_VAL_ 1547 SubIndex_1A02 Index 6658-6658;
SG_MUL_VAL_ 1547 NrOfMappedObjects_1A01_00 SubIndex_1A01 0-0;
SG_MUL_VAL_ 1547 SubIndex_1A01 Index 6657-6657;
SG_MUL_VAL_ 1547 NrOfMappedObjects_1A00_00 SubIndex_1A00 0-0;
SG_MUL_VAL_ 1547 SubIndex_1A00 Index 6656-6656;
SG_MUL_VAL_ 1547 EventTimer_1803_05 SubIndex_1803 5-5;
SG_MUL_VAL_ 1547 TransmissionType_1803_02 SubIndex_1803 2-2;
SG_MUL_VAL_ 1547 COB_ID_1803_01 SubIndex_1803 1-1;
SG_MUL_VAL_ 1547 NrOfEntries_1803_00 SubIndex_1803 0-0;
SG_MUL_VAL_ 1547 SubIndex_1803 Index 6147-6147;
SG_MUL_VAL_ 1547 EventTimer_1802_05 SubIndex_1802 5-5;
SG_MUL_VAL_ 1547 TransmissionType_1802_02 SubIndex_1802 2-2;
SG_MUL_VAL_ 1547 COB_ID_1802_01 SubIndex_1802 1-1;
SG_MUL_VAL_ 1547 NrOfEntries_1802_00 SubIndex_1802 0-0;
SG_MUL_VAL_ 1547 SubIndex_1802 Index 6146-6146;
SG_MUL_VAL_ 1547 EventTimer_1801_05 SubIndex_1801 5-5;
SG_MUL_VAL_ 1547 TransmissionType_1801_02 SubIndex_1801 2-2;
SG_MUL_VAL_ 1547 COB_ID_1801_01 SubIndex_1801 1-1;
SG_MUL_VAL_ 1547 NrOfEntries_1801_00 SubIndex_1801 0-0;
SG_MUL_VAL_ 1547 SubIndex_1801 Index 6145-6145;
SG_MUL_VAL_ 1547 EventTimer_1800_05 SubIndex_1800 5-5;
SG_MUL_VAL_ 1547 TransmissionType_1800_02 SubIndex_1800 2-2;
SG_MUL_VAL_ 1547 COB_ID_1800_01 SubIndex_1800 1-1;
SG_MUL_VAL_ 1547 NrOfEntries_1800_00 SubIndex_1800 0-0;
SG_MUL_VAL_ 1547 SubIndex_1800 Index 6144-6144;
SG_MUL_VAL_ 1547 NrOfMappedObjects_1603_00 SubIndex_1603 0-0;
SG_MUL_VAL_ 1547 SubIndex_1603 Index 5635-5635;
SG_MUL_VAL_ 1547 NrOfMappedObjects_1602_00 SubIndex_1602 0-0;
SG_MUL_VAL_ 1547 SubIndex_1602 Index 5634-5634;
SG_MUL_VAL_ 1547 NrOfMappedObjects_1601_00 SubIndex_1601 0-0;
SG_MUL_VAL_ 1547 SubIndex_1601 Index 5633-5633;
SG_MUL_VAL_ 1547 mappedObj2_1600_02 SubIndex_1600 2-2;
SG_MUL_VAL_ 1547 mappedObj1_1600_01 SubIndex_1600 1-1;
SG_MUL_VAL_ 1547 NrOfMappedObjects_1600_00 SubIndex_1600 0-0;
SG_MUL_VAL_ 1547 SubIndex_1600 Index 5632-5632;
SG_MUL_VAL_ 1547 TransmissionType_1403_02 SubIndex_1403 2-2;
SG_MUL_VAL_ 1547 COB_ID_1403_01 SubIndex_1403 1-1;
SG_MUL_VAL_ 1547 NrOfEntries_1403_00 SubIndex_1403 0-0;
SG_MUL_VAL_ 1547 SubIndex_1403 Index 5123-5123;
SG_MUL_VAL_ 1547 TransmissionType_1402_02 SubIndex_1402 2-2;
SG_MUL_VAL_ 1547 COB_ID_1402_01 SubIndex_1402 1-1;
SG_MUL_VAL_ 1547 NrOfEntries_1402_00 SubIndex_1402 0-0;
SG_MUL_VAL_ 1547 SubIndex_1402 Index 5122-5122;
SG_MUL_VAL_ 1547 TransmissionType_1401_02 SubIndex_1401 2-2;
SG_MUL_VAL_ 1547 COB_ID_1401_01 SubIndex_1401 1-1;
SG_MUL_VAL_ 1547 NrOfEntries_1401_00 SubIndex_1401 0-0;
SG_MUL_VAL_ 1547 SubIndex_1401 Index 5121-5121;
SG_MUL_VAL_ 1547 TransmissionType_1400_02 SubIndex_1400 2-2;
SG_MUL_VAL_ 1547 COB_ID_1400_01 SubIndex_1400 1-1;
SG_MUL_VAL_ 1547 NrOfEntries_1400_00 SubIndex_1400 0-0;
SG_MUL_VAL_ 1547 SubIndex_1400 Index 5120-5120;
SG_MUL_VAL_ 1547 Serial_number_1018_04 SubIndex_1018 4-4;
SG_MUL_VAL_ 1547 Revision_number_1018_03 SubIndex_1018 3-3;
SG_MUL_VAL_ 1547 Product_Code_1018_02 SubIndex_1018 2-2;
SG_MUL_VAL_ 1547 Vendor_Id_1018_01 SubIndex_1018 1-1;
SG_MUL_VAL_ 1547 number_of_entries_1018_00 SubIndex_1018 0-0;
SG_MUL_VAL_ 1547 SubIndex_1018 Index 4120-4120;
SG_MUL_VAL_ 1547 Producer_Heartbeat_Time_1017 SubIndex_1017 0-0;
SG_MUL_VAL_ 1547 SubIndex_1017 Index 4119-4119;
SG_MUL_VAL_ 1547 Consumer_Heartbeat_Time16_1_0000 SubIndex_1016 16-16;
SG_MUL_VAL_ 1547 Consumer_Heartbeat_Time15_1_0000 SubIndex_1016 15-15;
SG_MUL_VAL_ 1547 Consumer_Heartbeat_Time14_1_0000 SubIndex_1016 14-14;
SG_MUL_VAL_ 1547 Consumer_Heartbeat_Time13_1_0000 SubIndex_1016 13-13;
SG_MUL_VAL_ 1547 Consumer_Heartbeat_Time12_1_0000 SubIndex_1016 12-12;
SG_MUL_VAL_ 1547 Consumer_Heartbeat_Time11_1_0000 SubIndex_1016 11-11;
SG_MUL_VAL_ 1547 Consumer_Heartbeat_Time10_1_0000 SubIndex_1016 10-10;
SG_MUL_VAL_ 1547 Consumer_Heartbeat_Time9_1016_09 SubIndex_1016 9-9;
SG_MUL_VAL_ 1547 Consumer_Heartbeat_Time8_1016_08 SubIndex_1016 8-8;
SG_MUL_VAL_ 1547 Consumer_Heartbeat_Time7_1016_07 SubIndex_1016 7-7;
SG_MUL_VAL_ 1547 Consumer_Heartbeat_Time6_1016_06 SubIndex_1016 6-6;
SG_MUL_VAL_ 1547 Consumer_Heartbeat_Time5_1016_05 SubIndex_1016 5-5;
SG_MUL_VAL_ 1547 Consumer_Heartbeat_Time4_1016_04 SubIndex_1016 4-4;
SG_MUL_VAL_ 1547 Consumer_Heartbeat_Time3_1016_03 SubIndex_1016 3-3;
SG_MUL_VAL_ 1547 Consumer_Heartbeat_Time2_1016_02 SubIndex_1016 2-2;
SG_MUL_VAL_ 1547 Consumer_Heartbeat_Time1_1016_01 SubIndex_1016 1-1;
SG_MUL_VAL_ 1547 NrOfObjects_1016_00 SubIndex_1016 0-0;
SG_MUL_VAL_ 1547 SubIndex_1016 Index 4118-4118;
SG_MUL_VAL_ 1547 COB_ID_EMCY_1014 SubIndex_1014 0-0;
SG_MUL_VAL_ 1547 SubIndex_1014 Index 4116-4116;
SG_MUL_VAL_ 1547 Restore_all_Default_Paramet_0000 SubIndex_1011 1-1;
SG_MUL_VAL_ 1547 Number_of_Entries_1011_00 SubIndex_1011 0-0;
SG_MUL_VAL_ 1547 SubIndex_1011 Index 4113-4113;
SG_MUL_VAL_ 1547 Save_all_Parameters_1010_01 SubIndex_1010 1-1;
SG_MUL_VAL_ 1547 Number_of_Entries_1010_00 SubIndex_1010 0-0;
SG_MUL_VAL_ 1547 SubIndex_1010 Index 4112-4112;
SG_MUL_VAL_ 1547 Life_Time_Factor_100D SubIndex_100D 0-0;
SG_MUL_VAL_ 1547 SubIndex_100D Index 4109-4109;
SG_MUL_VAL_ 1547 Guard_Time_100C SubIndex_100C 0-0;
SG_MUL_VAL_ 1547 SubIndex_100C Index 4108-4108;
SG_MUL_VAL_ 1547 Synchronous_Window_Length_1007 SubIndex_1007 0-0;
SG_MUL_VAL_ 1547 SubIndex_1007 Index 4103-4103;
SG_MUL_VAL_ 1547 Communication_Cycle_Period_1006 SubIndex_1006 0-0;
SG_MUL_VAL_ 1547 SubIndex_1006 Index 4102-4102;
SG_MUL_VAL_ 1547 COB_ID_SYNC_1005 SubIndex_1005 0-0;
SG_MUL_VAL_ 1547 SubIndex_1005 Index 4101-4101;
SG_MUL_VAL_ 1547 Standard_error_field_1003_09 SubIndex_1003 9-9;
SG_MUL_VAL_ 1547 Standard_error_field_1003_08 SubIndex_1003 8-8;
SG_MUL_VAL_ 1547 Standard_error_field_1003_07 SubIndex_1003 7-7;
SG_MUL_VAL_ 1547 Standard_error_field_1003_06 SubIndex_1003 6-6;
SG_MUL_VAL_ 1547 Standard_error_field_1003_05 SubIndex_1003 5-5;
SG_MUL_VAL_ 1547 Standard_error_field_1003_04 SubIndex_1003 4-4;
SG_MUL_VAL_ 1547 Standard_error_field_1003_03 SubIndex_1003 3-3;
SG_MUL_VAL_ 1547 Standard_error_field_1003_02 SubIndex_1003 2-2;
SG_MUL_VAL_ 1547 Standard_error_field_1003_01 SubIndex_1003 1-1;
SG_MUL_VAL_ 1547 Number_of_Errors_1003_00 SubIndex_1003 0-0;
SG_MUL_VAL_ 1547 SubIndex_1003 Index 4099-4099;
SG_MUL_VAL_ 1547 Error_Register_1001 SubIndex_1001 0-0;
SG_MUL_VAL_ 1547 SubIndex_1001 Index 4097-4097;
SG_MUL_VAL_ 1547 Device_Type_1000 SubIndex_1000 0-0;
SG_MUL_VAL_ 1547 SubIndex_1000 Index 4096-4096;
SG_MUL_VAL_ 1547 Index TransferType 1-1;
SG_MUL_VAL_ 1547 TransferType CCS 1-2;
SG_MUL_VAL_ 1547 NotUsedBytes CCS 1-2;
SG_MUL_VAL_ 1547 SizeIndicator CCS 1-2;
SG_MUL_VAL_ 1409 ReadInput8_Bit4_A4C0_02 SubIndex_A4C0 2-2;
SG_MUL_VAL_ 1409 ReadInput8_Bit3_A4C0_01 SubIndex_A4C0 1-1;
SG_MUL_VAL_ 1409 NrOfObjects_A4C0_00 SubIndex_A4C0 0-0;
SG_MUL_VAL_ 1409 SubIndex_A4C0 Index 42176-42176;
SG_MUL_VAL_ 1409 BootTime_1F89 SubIndex_1F89 0-0;
SG_MUL_VAL_ 1409 SubIndex_1F89 Index 8073-8073;
SG_MUL_VAL_ 1409 SerialNumber127_1F88_7F SubIndex_1F88 127-127;
SG_MUL_VAL_ 1409 SerialNumber126_1F88_7E SubIndex_1F88 126-126;
SG_MUL_VAL_ 1409 SerialNumber125_1F88_7D SubIndex_1F88 125-125;
SG_MUL_VAL_ 1409 SerialNumber124_1F88_7C SubIndex_1F88 124-124;
SG_MUL_VAL_ 1409 SerialNumber123_1F88_7B SubIndex_1F88 123-123;
SG_MUL_VAL_ 1409 SerialNumber122_1F88_7A SubIndex_1F88 122-122;
SG_MUL_VAL_ 1409 SerialNumber121_1F88_79 SubIndex_1F88 121-121;
SG_MUL_VAL_ 1409 SerialNumber120_1F88_78 SubIndex_1F88 120-120;
SG_MUL_VAL_ 1409 SerialNumber119_1F88_77 SubIndex_1F88 119-119;
SG_MUL_VAL_ 1409 SerialNumber118_1F88_76 SubIndex_1F88 118-118;
SG_MUL_VAL_ 1409 SerialNumber117_1F88_75 SubIndex_1F88 117-117;
SG_MUL_VAL_ 1409 SerialNumber116_1F88_74 SubIndex_1F88 116-116;
SG_MUL_VAL_ 1409 SerialNumber115_1F88_73 SubIndex_1F88 115-115;
SG_MUL_VAL_ 1409 SerialNumber114_1F88_72 SubIndex_1F88 114-114;
SG_MUL_VAL_ 1409 SerialNumber113_1F88_71 SubIndex_1F88 113-113;
SG_MUL_VAL_ 1409 SerialNumber112_1F88_70 SubIndex_1F88 112-112;
SG_MUL_VAL_ 1409 SerialNumber111_1F88_6F SubIndex_1F88 111-111;
SG_MUL_VAL_ 1409 SerialNumber110_1F88_6E SubIndex_1F88 110-110;
SG_MUL_VAL_ 1409 SerialNumber109_1F88_6D SubIndex_1F88 109-109;
SG_MUL_VAL_ 1409 SerialNumber108_1F88_6C SubIndex_1F88 108-108;
SG_MUL_VAL_ 1409 SerialNumber107_1F88_6B SubIndex_1F88 107-107;
SG_MUL_VAL_ 1409 SerialNumber106_1F88_6A SubIndex_1F88 106-106;
SG_MUL_VAL_ 1409 SerialNumber105_1F88_69 SubIndex_1F88 105-105;
SG_MUL_VAL_ 1409 SerialNumber104_1F88_68 SubIndex_1F88 104-104;
SG_MUL_VAL_ 1409 SerialNumber103_1F88_67 SubIndex_1F88 103-103;
SG_MUL_VAL_ 1409 SerialNumber102_1F88_66 SubIndex_1F88 102-102;
SG_MUL_VAL_ 1409 SerialNumber101_1F88_65 SubIndex_1F88 101-101;
SG_MUL_VAL_ 1409 SerialNumber100_1F88_64 SubIndex_1F88 100-100;
SG_MUL_VAL_ 1409 SerialNumber99_1F88_63 SubIndex_1F88 99-99;
SG_MUL_VAL_ 1409 SerialNumber98_1F88_62 SubIndex_1F88 98-98;
SG_MUL_VAL_ 1409 SerialNumber97_1F88_61 SubIndex_1F88 97-97;
SG_MUL_VAL_ 1409 SerialNumber96_1F88_60 SubIndex_1F88 96-96;
SG_MUL_VAL_ 1409 SerialNumber95_1F88_5F SubIndex_1F88 95-95;
SG_MUL_VAL_ 1409 SerialNumber94_1F88_5E SubIndex_1F88 94-94;
SG_MUL_VAL_ 1409 SerialNumber93_1F88_5D SubIndex_1F88 93-93;
SG_MUL_VAL_ 1409 SerialNumber92_1F88_5C SubIndex_1F88 92-92;
SG_MUL_VAL_ 1409 SerialNumber91_1F88_5B SubIndex_1F88 91-91;
SG_MUL_VAL_ 1409 SerialNumber90_1F88_5A SubIndex_1F88 90-90;
SG_MUL_VAL_ 1409 SerialNumber89_1F88_59 SubIndex_1F88 89-89;
SG_MUL_VAL_ 1409 SerialNumber88_1F88_58 SubIndex_1F88 88-88;
SG_MUL_VAL_ 1409 SerialNumber87_1F88_57 SubIndex_1F88 87-87;
SG_MUL_VAL_ 1409 SerialNumber86_1F88_56 SubIndex_1F88 86-86;
SG_MUL_VAL_ 1409 SerialNumber85_1F88_55 SubIndex_1F88 85-85;
SG_MUL_VAL_ 1409 SerialNumber84_1F88_54 SubIndex_1F88 84-84;
SG_MUL_VAL_ 1409 SerialNumber83_1F88_53 SubIndex_1F88 83-83;
SG_MUL_VAL_ 1409 SerialNumber82_1F88_52 SubIndex_1F88 82-82;
SG_MUL_VAL_ 1409 SerialNumber81_1F88_51 SubIndex_1F88 81-81;
SG_MUL_VAL_ 1409 SerialNumber80_1F88_50 SubIndex_1F88 80-80;
SG_MUL_VAL_ 1409 SerialNumber79_1F88_4F SubIndex_1F88 79-79;
SG_MUL_VAL_ 1409 SerialNumber78_1F88_4E SubIndex_1F88 78-78;
SG_MUL_VAL_ 1409 SerialNumber77_1F88_4D SubIndex_1F88 77-77;
SG_MUL_VAL_ 1409 SerialNumber76_1F88_4C SubIndex_1F88 76-76;
SG_MUL_VAL_ 1409 SerialNumber75_1F88_4B SubIndex_1F88 75-75;
SG_MUL_VAL_ 1409 SerialNumber74_1F88_4A SubIndex_1F88 74-74;
SG_MUL_VAL_ 1409 SerialNumber73_1F88_49 SubIndex_1F88 73-73;
SG_MUL_VAL_ 1409 SerialNumber72_1F88_48 SubIndex_1F88 72-72;
SG_MUL_VAL_ 1409 SerialNumber71_1F88_47 SubIndex_1F88 71-71;
SG_MUL_VAL_ 1409 SerialNumber70_1F88_46 SubIndex_1F88 70-70;
SG_MUL_VAL_ 1409 SerialNumber69_1F88_45 SubIndex_1F88 69-69;
SG_MUL_VAL_ 1409 SerialNumber68_1F88_44 SubIndex_1F88 68-68;
SG_MUL_VAL_ 1409 SerialNumber67_1F88_43 SubIndex_1F88 67-67;
SG_MUL_VAL_ 1409 SerialNumber66_1F88_42 SubIndex_1F88 66-66;
SG_MUL_VAL_ 1409 SerialNumber65_1F88_41 SubIndex_1F88 65-65;
SG_MUL_VAL_ 1409 SerialNumber64_1F88_40 SubIndex_1F88 64-64;
SG_MUL_VAL_ 1409 SerialNumber63_1F88_3F SubIndex_1F88 63-63;
SG_MUL_VAL_ 1409 SerialNumber62_1F88_3E SubIndex_1F88 62-62;
SG_MUL_VAL_ 1409 SerialNumber61_1F88_3D SubIndex_1F88 61-61;
SG_MUL_VAL_ 1409 SerialNumber60_1F88_3C SubIndex_1F88 60-60;
SG_MUL_VAL_ 1409 SerialNumber59_1F88_3B SubIndex_1F88 59-59;
SG_MUL_VAL_ 1409 SerialNumber58_1F88_3A SubIndex_1F88 58-58;
SG_MUL_VAL_ 1409 SerialNumber57_1F88_39 SubIndex_1F88 57-57;
SG_MUL_VAL_ 1409 SerialNumber56_1F88_38 SubIndex_1F88 56-56;
SG_MUL_VAL_ 1409 SerialNumber55_1F88_37 SubIndex_1F88 55-55;
SG_MUL_VAL_ 1409 SerialNumber54_1F88_36 SubIndex_1F88 54-54;
SG_MUL_VAL_ 1409 SerialNumber53_1F88_35 SubIndex_1F88 53-53;
SG_MUL_VAL_ 1409 SerialNumber52_1F88_34 SubIndex_1F88 52-52;
SG_MUL_VAL_ 1409 SerialNumber51_1F88_33 SubIndex_1F88 51-51;
SG_MUL_VAL_ 1409 SerialNumber50_1F88_32 SubIndex_1F88 50-50;
SG_MUL_VAL_ 1409 SerialNumber49_1F88_31 SubIndex_1F88 49-49;
SG_MUL_VAL_ 1409 SerialNumber48_1F88_30 SubIndex_1F88 48-48;
SG_MUL_VAL_ 1409 SerialNumber47_1F88_2F SubIndex_1F88 47-47;
SG_MUL_VAL_ 1409 SerialNumber46_1F88_2E SubIndex_1F88 46-46;
SG_MUL_VAL_ 1409 SerialNumber45_1F88_2D SubIndex_1F88 45-45;
SG_MUL_VAL_ 1409 SerialNumber44_1F88_2C SubIndex_1F88 44-44;
SG_MUL_VAL_ 1409 SerialNumber43_1F88_2B SubIndex_1F88 43-43;
SG_MUL_VAL_ 1409 SerialNumber42_1F88_2A SubIndex_1F88 42-42;
SG_MUL_VAL_ 1409 SerialNumber41_1F88_29 SubIndex_1F88 41-41;
SG_MUL_VAL_ 1409 SerialNumber40_1F88_28 SubIndex_1F88 40-40;
SG_MUL_VAL_ 1409 SerialNumber39_1F88_27 SubIndex_1F88 39-39;
SG_MUL_VAL_ 1409 SerialNumber38_1F88_26 SubIndex_1F88 38-38;
SG_MUL_VAL_ 1409 SerialNumber37_1F88_25 SubIndex_1F88 37-37;
SG_MUL_VAL_ 1409 SerialNumber36_1F88_24 SubIndex_1F88 36-36;
SG_MUL_VAL_ 1409 SerialNumber35_1F88_23 SubIndex_1F88 35-35;
SG_MUL_VAL_ 1409 SerialNumber34_1F88_22 SubIndex_1F88 34-34;
SG_MUL_VAL_ 1409 SerialNumber33_1F88_21 SubIndex_1F88 33-33;
SG_MUL_VAL_ 1409 SerialNumber32_1F88_20 SubIndex_1F88 32-32;
SG_MUL_VAL_ 1409 SerialNumber31_1F88_1F SubIndex_1F88 31-31;
SG_MUL_VAL_ 1409 SerialNumber30_1F88_1E SubIndex_1F88 30-30;
SG_MUL_VAL_ 1409 SerialNumber29_1F88_1D SubIndex_1F88 29-29;
SG_MUL_VAL_ 1409 SerialNumber28_1F88_1C SubIndex_1F88 28-28;
SG_MUL_VAL_ 1409 SerialNumber27_1F88_1B SubIndex_1F88 27-27;
SG_MUL_VAL_ 1409 SerialNumber26_1F88_1A SubIndex_1F88 26-26;
SG_MUL_VAL_ 1409 SerialNumber25_1F88_19 SubIndex_1F88 25-25;
SG_MUL_VAL_ 1409 SerialNumber24_1F88_18 SubIndex_1F88 24-24;
SG_MUL_VAL_ 1409 SerialNumber23_1F88_17 SubIndex_1F88 23-23;
SG_MUL_VAL_ 1409 SerialNumber22_1F88_16 SubIndex_1F88 22-22;
SG_MUL_VAL_ 1409 SerialNumber21_1F88_15 SubIndex_1F88 21-21;
SG_MUL_VAL_ 1409 SerialNumber20_1F88_14 SubIndex_1F88 20-20;
SG_MUL_VAL_ 1409 SerialNumber19_1F88_13 SubIndex_1F88 19-19;
SG_MUL_VAL_ 1409 SerialNumber18_1F88_12 SubIndex_1F88 18-18;
SG_MUL_VAL_ 1409 SerialNumber17_1F88_11 SubIndex_1F88 17-17;
SG_MUL_VAL_ 1409 SerialNumber16_1F88_10 SubIndex_1F88 16-16;
SG_MUL_VAL_ 1409 SerialNumber15_1F88_0F SubIndex_1F88 15-15;
SG_MUL_VAL_ 1409 SerialNumber14_1F88_0E SubIndex_1F88 14-14;
SG_MUL_VAL_ 1409 SerialNumber13_1F88_0D SubIndex_1F88 13-13;
SG_MUL_VAL_ 1409 SerialNumber12_1F88_0C SubIndex_1F88 12-12;
SG_MUL_VAL_ 1409 SerialNumber11_1F88_0B SubIndex_1F88 11-11;
SG_MUL_VAL_ 1409 SerialNumber10_1F88_0A SubIndex_1F88 10-10;
SG_MUL_VAL_ 1409 SerialNumber9_1F88_09 SubIndex_1F88 9-9;
SG_MUL_VAL_ 1409 SerialNumber8_1F88_08 SubIndex_1F88 8-8;
SG_MUL_VAL_ 1409 SerialNumber7_1F88_07 SubIndex_1F88 7-7;
SG_MUL_VAL_ 1409 SerialNumber6_1F88_06 SubIndex_1F88 6-6;
SG_MUL_VAL_ 1409 SerialNumber5_1F88_05 SubIndex_1F88 5-5;
SG_MUL_VAL_ 1409 SerialNumber4_1F88_04 SubIndex_1F88 4-4;
SG_MUL_VAL_ 1409 SerialNumber3_1F88_03 SubIndex_1F88 3-3;
SG_MUL_VAL_ 1409 SerialNumber2_1F88_02 SubIndex_1F88 2-2;
SG_MUL_VAL_ 1409 SerialNumber1_1F88_01 SubIndex_1F88 1-1;
SG_MUL_VAL_ 1409 NrOfObjects_1F88_00 SubIndex_1F88 0-0;
SG_MUL_VAL_ 1409 SubIndex_1F88 Index 8072-8072;
SG_MUL_VAL_ 1409 RevisionNumber127_1F87_7F SubIndex_1F87 127-127;
SG_MUL_VAL_ 1409 RevisionNumber126_1F87_7E SubIndex_1F87 126-126;
SG_MUL_VAL_ 1409 RevisionNumber125_1F87_7D SubIndex_1F87 125-125;
SG_MUL_VAL_ 1409 RevisionNumber124_1F87_7C SubIndex_1F87 124-124;
SG_MUL_VAL_ 1409 RevisionNumber123_1F87_7B SubIndex_1F87 123-123;
SG_MUL_VAL_ 1409 RevisionNumber122_1F87_7A SubIndex_1F87 122-122;
SG_MUL_VAL_ 1409 RevisionNumber121_1F87_79 SubIndex_1F87 121-121;
SG_MUL_VAL_ 1409 RevisionNumber120_1F87_78 SubIndex_1F87 120-120;
SG_MUL_VAL_ 1409 RevisionNumber119_1F87_77 SubIndex_1F87 119-119;
SG_MUL_VAL_ 1409 RevisionNumber118_1F87_76 SubIndex_1F87 118-118;
SG_MUL_VAL_ 1409 RevisionNumber117_1F87_75 SubIndex_1F87 117-117;
SG_MUL_VAL_ 1409 RevisionNumber116_1F87_74 SubIndex_1F87 116-116;
SG_MUL_VAL_ 1409 RevisionNumber115_1F87_73 SubIndex_1F87 115-115;
SG_MUL_VAL_ 1409 RevisionNumber114_1F87_72 SubIndex_1F87 114-114;
SG_MUL_VAL_ 1409 RevisionNumber113_1F87_71 SubIndex_1F87 113-113;
SG_MUL_VAL_ 1409 RevisionNumber112_1F87_70 SubIndex_1F87 112-112;
SG_MUL_VAL_ 1409 RevisionNumber111_1F87_6F SubIndex_1F87 111-111;
SG_MUL_VAL_ 1409 RevisionNumber110_1F87_6E SubIndex_1F87 110-110;
SG_MUL_VAL_ 1409 RevisionNumber109_1F87_6D SubIndex_1F87 109-109;
SG_MUL_VAL_ 1409 RevisionNumber108_1F87_6C SubIndex_1F87 108-108;
SG_MUL_VAL_ 1409 RevisionNumber107_1F87_6B SubIndex_1F87 107-107;
SG_MUL_VAL_ 1409 RevisionNumber106_1F87_6A SubIndex_1F87 106-106;
SG_MUL_VAL_ 1409 RevisionNumber105_1F87_69 SubIndex_1F87 105-105;
SG_MUL_VAL_ 1409 RevisionNumber104_1F87_68 SubIndex_1F87 104-104;
SG_MUL_VAL_ 1409 RevisionNumber103_1F87_67 SubIndex_1F87 103-103;
SG_MUL_VAL_ 1409 RevisionNumber102_1F87_66 SubIndex_1F87 102-102;
SG_MUL_VAL_ 1409 RevisionNumber101_1F87_65 SubIndex_1F87 101-101;
SG_MUL_VAL_ 1409 RevisionNumber100_1F87_64 SubIndex_1F87 100-100;
SG_MUL_VAL_ 1409 RevisionNumber99_1F87_63 SubIndex_1F87 99-99;
SG_MUL_VAL_ 1409 RevisionNumber98_1F87_62 SubIndex_1F87 98-98;
SG_MUL_VAL_ 1409 RevisionNumber97_1F87_61 SubIndex_1F87 97-97;
SG_MUL_VAL_ 1409 RevisionNumber96_1F87_60 SubIndex_1F87 96-96;
SG_MUL_VAL_ 1409 RevisionNumber95_1F87_5F SubIndex_1F87 95-95;
SG_MUL_VAL_ 1409 RevisionNumber94_1F87_5E SubIndex_1F87 94-94;
SG_MUL_VAL_ 1409 RevisionNumber93_1F87_5D SubIndex_1F87 93-93;
SG_MUL_VAL_ 1409 RevisionNumber92_1F87_5C SubIndex_1F87 92-92;
SG_MUL_VAL_ 1409 RevisionNumber91_1F87_5B SubIndex_1F87 91-91;
SG_MUL_VAL_ 1409 RevisionNumber90_1F87_5A SubIndex_1F87 90-90;
SG_MUL_VAL_ 1409 RevisionNumber89_1F87_59 SubIndex_1F87 89-89;
SG_MUL_VAL_ 1409 RevisionNumber88_1F87_58 SubIndex_1F87 88-88;
SG_MUL_VAL_ 1409 RevisionNumber87_1F87_57 SubIndex_1F87 87-87;
SG_MUL_VAL_ 1409 RevisionNumber86_1F87_56 SubIndex_1F87 86-86;
SG_MUL_VAL_ 1409 RevisionNumber85_1F87_55 SubIndex_1F87 85-85;
SG_MUL_VAL_ 1409 RevisionNumber84_1F87_54 SubIndex_1F87 84-84;
SG_MUL_VAL_ 1409 RevisionNumber83_1F87_53 SubIndex_1F87 83-83;
SG_MUL_VAL_ 1409 RevisionNumber82_1F87_52 SubIndex_1F87 82-82;
SG_MUL_VAL_ 1409 RevisionNumber81_1F87_51 SubIndex_1F87 81-81;
SG_MUL_VAL_ 1409 RevisionNumber80_1F87_50 SubIndex_1F87 80-80;
SG_MUL_VAL_ 1409 RevisionNumber79_1F87_4F SubIndex_1F87 79-79;
SG_MUL_VAL_ 1409 RevisionNumber78_1F87_4E SubIndex_1F87 78-78;
SG_MUL_VAL_ 1409 RevisionNumber77_1F87_4D SubIndex_1F87 77-77;
SG_MUL_VAL_ 1409 RevisionNumber76_1F87_4C SubIndex_1F87 76-76;
SG_MUL_VAL_ 1409 RevisionNumber75_1F87_4B SubIndex_1F87 75-75;
SG_MUL_VAL_ 1409 RevisionNumber74_1F87_4A SubIndex_1F87 74-74;
SG_MUL_VAL_ 1409 RevisionNumber73_1F87_49 SubIndex_1F87 73-73;
SG_MUL_VAL_ 1409 RevisionNumber72_1F87_48 SubIndex_1F87 72-72;
SG_MUL_VAL_ 1409 RevisionNumber71_1F87_47 SubIndex_1F87 71-71;
SG_MUL_VAL_ 1409 RevisionNumber70_1F87_46 SubIndex_1F87 70-70;
SG_MUL_VAL_ 1409 RevisionNumber69_1F87_45 SubIndex_1F87 69-69;
SG_MUL_VAL_ 1409 RevisionNumber68_1F87_44 SubIndex_1F87 68-68;
SG_MUL_VAL_ 1409 RevisionNumber67_1F87_43 SubIndex_1F87 67-67;
SG_MUL_VAL_ 1409 RevisionNumber66_1F87_42 SubIndex_1F87 66-66;
SG_MUL_VAL_ 1409 RevisionNumber65_1F87_41 SubIndex_1F87 65-65;
SG_MUL_VAL_ 1409 RevisionNumber64_1F87_40 SubIndex_1F87 64-64;
SG_MUL_VAL_ 1409 RevisionNumber63_1F87_3F SubIndex_1F87 63-63;
SG_MUL_VAL_ 1409 RevisionNumber62_1F87_3E SubIndex_1F87 62-62;
SG_MUL_VAL_ 1409 RevisionNumber61_1F87_3D SubIndex_1F87 61-61;
SG_MUL_VAL_ 1409 RevisionNumber60_1F87_3C SubIndex_1F87 60-60;
SG_MUL_VAL_ 1409 RevisionNumber59_1F87_3B SubIndex_1F87 59-59;
SG_MUL_VAL_ 1409 RevisionNumber58_1F87_3A SubIndex_1F87 58-58;
SG_MUL_VAL_ 1409 RevisionNumber57_1F87_39 SubIndex_1F87 57-57;
SG_MUL_VAL_ 1409 RevisionNumber56_1F87_38 SubIndex_1F87 56-56;
SG_MUL_VAL_ 1409 RevisionNumber55_1F87_37 SubIndex_1F87 55-55;
SG_MUL_VAL_ 1409 RevisionNumber54_1F87_36 SubIndex_1F87 54-54;
SG_MUL_VAL_ 1409 RevisionNumber53_1F87_35 SubIndex_1F87 53-53;
SG_MUL_VAL_ 1409 RevisionNumber52_1F87_34 SubIndex_1F87 52-52;
SG_MUL_VAL_ 1409 RevisionNumber51_1F87_33 SubIndex_1F87 51-51;
SG_MUL_VAL_ 1409 RevisionNumber50_1F87_32 SubIndex_1F87 50-50;
SG_MUL_VAL_ 1409 RevisionNumber49_1F87_31 SubIndex_1F87 49-49;
SG_MUL_VAL_ 1409 RevisionNumber48_1F87_30 SubIndex_1F87 48-48;
SG_MUL_VAL_ 1409 RevisionNumber47_1F87_2F SubIndex_1F87 47-47;
SG_MUL_VAL_ 1409 RevisionNumber46_1F87_2E SubIndex_1F87 46-46;
SG_MUL_VAL_ 1409 RevisionNumber45_1F87_2D SubIndex_1F87 45-45;
SG_MUL_VAL_ 1409 RevisionNumber44_1F87_2C SubIndex_1F87 44-44;
SG_MUL_VAL_ 1409 RevisionNumber43_1F87_2B SubIndex_1F87 43-43;
SG_MUL_VAL_ 1409 RevisionNumber42_1F87_2A SubIndex_1F87 42-42;
SG_MUL_VAL_ 1409 RevisionNumber41_1F87_29 SubIndex_1F87 41-41;
SG_MUL_VAL_ 1409 RevisionNumber40_1F87_28 SubIndex_1F87 40-40;
SG_MUL_VAL_ 1409 RevisionNumber39_1F87_27 SubIndex_1F87 39-39;
SG_MUL_VAL_ 1409 RevisionNumber38_1F87_26 SubIndex_1F87 38-38;
SG_MUL_VAL_ 1409 RevisionNumber37_1F87_25 SubIndex_1F87 37-37;
SG_MUL_VAL_ 1409 RevisionNumber36_1F87_24 SubIndex_1F87 36-36;
SG_MUL_VAL_ 1409 RevisionNumber35_1F87_23 SubIndex_1F87 35-35;
SG_MUL_VAL_ 1409 RevisionNumber34_1F87_22 SubIndex_1F87 34-34;
SG_MUL_VAL_ 1409 RevisionNumber33_1F87_21 SubIndex_1F87 33-33;
SG_MUL_VAL_ 1409 RevisionNumber32_1F87_20 SubIndex_1F87 32-32;
SG_MUL_VAL_ 1409 RevisionNumber31_1F87_1F SubIndex_1F87 31-31;
SG_MUL_VAL_ 1409 RevisionNumber30_1F87_1E SubIndex_1F87 30-30;
SG_MUL_VAL_ 1409 RevisionNumber29_1F87_1D SubIndex_1F87 29-29;
SG_MUL_VAL_ 1409 RevisionNumber28_1F87_1C SubIndex_1F87 28-28;
SG_MUL_VAL_ 1409 RevisionNumber27_1F87_1B SubIndex_1F87 27-27;
SG_MUL_VAL_ 1409 RevisionNumber26_1F87_1A SubIndex_1F87 26-26;
SG_MUL_VAL_ 1409 RevisionNumber25_1F87_19 SubIndex_1F87 25-25;
SG_MUL_VAL_ 1409 RevisionNumber24_1F87_18 SubIndex_1F87 24-24;
SG_MUL_VAL_ 1409 RevisionNumber23_1F87_17 SubIndex_1F87 23-23;
SG_MUL_VAL_ 1409 RevisionNumber22_1F87_16 SubIndex_1F87 22-22;
SG_MUL_VAL_ 1409 RevisionNumber21_1F87_15 SubIndex_1F87 21-21;
SG_MUL_VAL_ 1409 RevisionNumber20_1F87_14 SubIndex_1F87 20-20;
SG_MUL_VAL_ 1409 RevisionNumber19_1F87_13 SubIndex_1F87 19-19;
SG_MUL_VAL_ 1409 RevisionNumber18_1F87_12 SubIndex_1F87 18-18;
SG_MUL_VAL_ 1409 RevisionNumber17_1F87_11 SubIndex_1F87 17-17;
SG_MUL_VAL_ 1409 RevisionNumber16_1F87_10 SubIndex_1F87 16-16;
SG_MUL_VAL_ 1409 RevisionNumber15_1F87_0F SubIndex_1F87 15-15;
SG_MUL_VAL_ 1409 RevisionNumber14_1F87_0E SubIndex_1F87 14-14;
SG_MUL_VAL_ 1409 RevisionNumber13_1F87_0D SubIndex_1F87 13-13;
SG_MUL_VAL_ 1409 RevisionNumber12_1F87_0C SubIndex_1F87 12-12;
SG_MUL_VAL_ 1409 RevisionNumber11_1F87_0B SubIndex_1F87 11-11;
SG_MUL_VAL_ 1409 RevisionNumber10_1F87_0A SubIndex_1F87 10-10;
SG_MUL_VAL_ 1409 RevisionNumber9_1F87_09 SubIndex_1F87 9-9;
SG_MUL_VAL_ 1409 RevisionNumber8_1F87_08 SubIndex_1F87 8-8;
SG_MUL_VAL_ 1409 RevisionNumber7_1F87_07 SubIndex_1F87 7-7;
SG_MUL_VAL_ 1409 RevisionNumber6_1F87_06 SubIndex_1F87 6-6;
SG_MUL_VAL_ 1409 RevisionNumber5_1F87_05 SubIndex_1F87 5-5;
SG_MUL_VAL_ 1409 RevisionNumber4_1F87_04 SubIndex_1F87 4-4;
SG_MUL_VAL_ 1409 RevisionNumber3_1F87_03 SubIndex_1F87 3-3;
SG_MUL_VAL_ 1409 RevisionNumber2_1F87_02 SubIndex_1F87 2-2;
SG_MUL_VAL_ 1409 RevisionNumber1_1F87_01 SubIndex_1F87 1-1;
SG_MUL_VAL_ 1409 NrOfObjects_1F87_00 SubIndex_1F87 0-0;
SG_MUL_VAL_ 1409 SubIndex_1F87 Index 8071-8071;
SG_MUL_VAL_ 1409 ProductCode127_1F86_7F SubIndex_1F86 127-127;
SG_MUL_VAL_ 1409 ProductCode126_1F86_7E SubIndex_1F86 126-126;
SG_MUL_VAL_ 1409 ProductCode125_1F86_7D SubIndex_1F86 125-125;
SG_MUL_VAL_ 1409 ProductCode124_1F86_7C SubIndex_1F86 124-124;
SG_MUL_VAL_ 1409 ProductCode123_1F86_7B SubIndex_1F86 123-123;
SG_MUL_VAL_ 1409 ProductCode122_1F86_7A SubIndex_1F86 122-122;
SG_MUL_VAL_ 1409 ProductCode121_1F86_79 SubIndex_1F86 121-121;
SG_MUL_VAL_ 1409 ProductCode120_1F86_78 SubIndex_1F86 120-120;
SG_MUL_VAL_ 1409 ProductCode119_1F86_77 SubIndex_1F86 119-119;
SG_MUL_VAL_ 1409 ProductCode118_1F86_76 SubIndex_1F86 118-118;
SG_MUL_VAL_ 1409 ProductCode117_1F86_75 SubIndex_1F86 117-117;
SG_MUL_VAL_ 1409 ProductCode116_1F86_74 SubIndex_1F86 116-116;
SG_MUL_VAL_ 1409 ProductCode115_1F86_73 SubIndex_1F86 115-115;
SG_MUL_VAL_ 1409 ProductCode114_1F86_72 SubIndex_1F86 114-114;
SG_MUL_VAL_ 1409 ProductCode113_1F86_71 SubIndex_1F86 113-113;
SG_MUL_VAL_ 1409 ProductCode112_1F86_70 SubIndex_1F86 112-112;
SG_MUL_VAL_ 1409 ProductCode111_1F86_6F SubIndex_1F86 111-111;
SG_MUL_VAL_ 1409 ProductCode110_1F86_6E SubIndex_1F86 110-110;
SG_MUL_VAL_ 1409 ProductCode109_1F86_6D SubIndex_1F86 109-109;
SG_MUL_VAL_ 1409 ProductCode108_1F86_6C SubIndex_1F86 108-108;
SG_MUL_VAL_ 1409 ProductCode107_1F86_6B SubIndex_1F86 107-107;
SG_MUL_VAL_ 1409 ProductCode106_1F86_6A SubIndex_1F86 106-106;
SG_MUL_VAL_ 1409 ProductCode105_1F86_69 SubIndex_1F86 105-105;
SG_MUL_VAL_ 1409 ProductCode104_1F86_68 SubIndex_1F86 104-104;
SG_MUL_VAL_ 1409 ProductCode103_1F86_67 SubIndex_1F86 103-103;
SG_MUL_VAL_ 1409 ProductCode102_1F86_66 SubIndex_1F86 102-102;
SG_MUL_VAL_ 1409 ProductCode101_1F86_65 SubIndex_1F86 101-101;
SG_MUL_VAL_ 1409 ProductCode100_1F86_64 SubIndex_1F86 100-100;
SG_MUL_VAL_ 1409 ProductCode99_1F86_63 SubIndex_1F86 99-99;
SG_MUL_VAL_ 1409 ProductCode98_1F86_62 SubIndex_1F86 98-98;
SG_MUL_VAL_ 1409 ProductCode97_1F86_61 SubIndex_1F86 97-97;
SG_MUL_VAL_ 1409 ProductCode96_1F86_60 SubIndex_1F86 96-96;
SG_MUL_VAL_ 1409 ProductCode95_1F86_5F SubIndex_1F86 95-95;
SG_MUL_VAL_ 1409 ProductCode94_1F86_5E SubIndex_1F86 94-94;
SG_MUL_VAL_ 1409 ProductCode93_1F86_5D SubIndex_1F86 93-93;
SG_MUL_VAL_ 1409 ProductCode92_1F86_5C SubIndex_1F86 92-92;
SG_MUL_VAL_ 1409 ProductCode91_1F86_5B SubIndex_1F86 91-91;
SG_MUL_VAL_ 1409 ProductCode90_1F86_5A SubIndex_1F86 90-90;
SG_MUL_VAL_ 1409 ProductCode89_1F86_59 SubIndex_1F86 89-89;
SG_MUL_VAL_ 1409 ProductCode88_1F86_58 SubIndex_1F86 88-88;
SG_MUL_VAL_ 1409 ProductCode87_1F86_57 SubIndex_1F86 87-87;
SG_MUL_VAL_ 1409 ProductCode86_1F86_56 SubIndex_1F86 86-86;
SG_MUL_VAL_ 1409 ProductCode85_1F86_55 SubIndex_1F86 85-85;
SG_MUL_VAL_ 1409 ProductCode84_1F86_54 SubIndex_1F86 84-84;
SG_MUL_VAL_ 1409 ProductCode83_1F86_53 SubIndex_1F86 83-83;
SG_MUL_VAL_ 1409 ProductCode82_1F86_52 SubIndex_1F86 82-82;
SG_MUL_VAL_ 1409 ProductCode81_1F86_51 SubIndex_1F86 81-81;
SG_MUL_VAL_ 1409 ProductCode80_1F86_50 SubIndex_1F86 80-80;
SG_MUL_VAL_ 1409 ProductCode79_1F86_4F SubIndex_1F86 79-79;
SG_MUL_VAL_ 1409 ProductCode78_1F86_4E SubIndex_1F86 78-78;
SG_MUL_VAL_ 1409 ProductCode77_1F86_4D SubIndex_1F86 77-77;
SG_MUL_VAL_ 1409 ProductCode76_1F86_4C SubIndex_1F86 76-76;
SG_MUL_VAL_ 1409 ProductCode75_1F86_4B SubIndex_1F86 75-75;
SG_MUL_VAL_ 1409 ProductCode74_1F86_4A SubIndex_1F86 74-74;
SG_MUL_VAL_ 1409 ProductCode73_1F86_49 SubIndex_1F86 73-73;
SG_MUL_VAL_ 1409 ProductCode72_1F86_48 SubIndex_1F86 72-72;
SG_MUL_VAL_ 1409 ProductCode71_1F86_47 SubIndex_1F86 71-71;
SG_MUL_VAL_ 1409 ProductCode70_1F86_46 SubIndex_1F86 70-70;
SG_MUL_VAL_ 1409 ProductCode69_1F86_45 SubIndex_1F86 69-69;
SG_MUL_VAL_ 1409 ProductCode68_1F86_44 SubIndex_1F86 68-68;
SG_MUL_VAL_ 1409 ProductCode67_1F86_43 SubIndex_1F86 67-67;
SG_MUL_VAL_ 1409 ProductCode66_1F86_42 SubIndex_1F86 66-66;
SG_MUL_VAL_ 1409 ProductCode65_1F86_41 SubIndex_1F86 65-65;
SG_MUL_VAL_ 1409 ProductCode64_1F86_40 SubIndex_1F86 64-64;
SG_MUL_VAL_ 1409 ProductCode63_1F86_3F SubIndex_1F86 63-63;
SG_MUL_VAL_ 1409 ProductCode62_1F86_3E SubIndex_1F86 62-62;
SG_MUL_VAL_ 1409 ProductCode61_1F86_3D SubIndex_1F86 61-61;
SG_MUL_VAL_ 1409 ProductCode60_1F86_3C SubIndex_1F86 60-60;
SG_MUL_VAL_ 1409 ProductCode59_1F86_3B SubIndex_1F86 59-59;
SG_MUL_VAL_ 1409 ProductCode58_1F86_3A SubIndex_1F86 58-58;
SG_MUL_VAL_ 1409 ProductCode57_1F86_39 SubIndex_1F86 57-57;
SG_MUL_VAL_ 1409 ProductCode56_1F86_38 SubIndex_1F86 56-56;
SG_MUL_VAL_ 1409 ProductCode55_1F86_37 SubIndex_1F86 55-55;
SG_MUL_VAL_ 1409 ProductCode54_1F86_36 SubIndex_1F86 54-54;
SG_MUL_VAL_ 1409 ProductCode53_1F86_35 SubIndex_1F86 53-53;
SG_MUL_VAL_ 1409 ProductCode52_1F86_34 SubIndex_1F86 52-52;
SG_MUL_VAL_ 1409 ProductCode51_1F86_33 SubIndex_1F86 51-51;
SG_MUL_VAL_ 1409 ProductCode50_1F86_32 SubIndex_1F86 50-50;
SG_MUL_VAL_ 1409 ProductCode49_1F86_31 SubIndex_1F86 49-49;
SG_MUL_VAL_ 1409 ProductCode48_1F86_30 SubIndex_1F86 48-48;
